VERSION "created by canmatrix"

NS_ :

BS_:

BU_: MD1_ECM ETC NODE_5 BSM_EBS RM_IRCS IC_Multic SGW BCM_NBM VCM NODE_31 ETS NODE_45 FCCU DICO NODE_72 FMReceiver SGW2 VCU ADCU MRGEN DTCO MBMS TPMS AI_CAID ELC ELC_R NODE_F7 BMS3 TUROLLA PCM SRR_Front_Left SRR_Rear_Right SRR_Front_Right SRR_Front SRR_Rear_Left ELFA3_S THERMOKING_M TMU_HP_Rr NODE_B1 NODE_B2 NODE_B3 NODE_B4 NODE_B5 NODE_B6 NODE_B7 NODE_B8 BMS2 NODE_B9 NODE_BA NODE_FC NODE_BB NODE_BC NODE_BE NODE_BD NODE_BF ACU NODE_C0 BMS1 NODE_C1 FCU NODE_C3 NODE_C4 NODE_EC NODE_C5 NODE_C6 NODE_C7 NODE_C8 VCU2 NODE_CA NODE_CB NODE_CD NODE_CE NODE_CF NODE_ED ST_ScanTool MASTER68_STD1 NODE_D1 NODE_F2 NODE_FD NODE_D2 MCSL NODE_EB NODE_D3 NODE_D4 NODE_D5 NODE_D6 VCCU NODE_D8 NODE_D9 NODE_F9 DiagTool NODE_DA NODE_DB NODE_DC NODE_DD NODE_DE NODE_DF NODE_E0 NODE_E1 NODE_E2 NODE_E9 NODE_E3 SAS NODE_FB NODE_F8 NODE_E6 ELFA3 NODE_F THERMOKING_D FMS MULTIC_S MULTIC_2 BMS4 BMS5 BMS6 BMS7 BMS8 BMS9 BMS10 BMS11 NODE_71

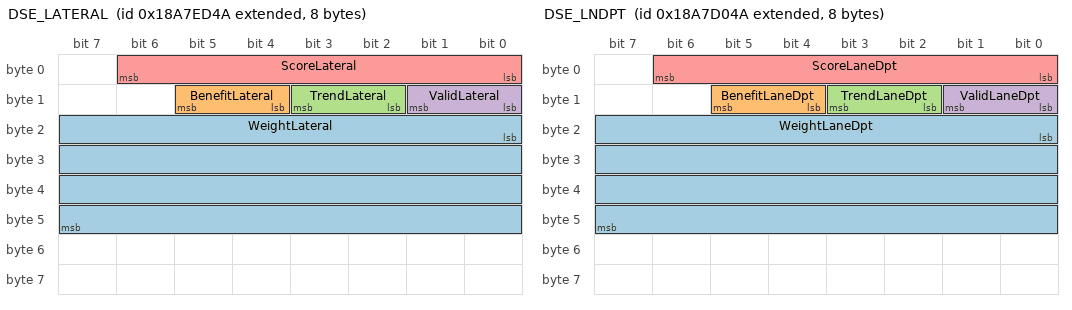
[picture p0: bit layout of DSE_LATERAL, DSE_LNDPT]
BO_ 2561142090 DSE_LATERAL: 8 PCM
 SG_ WeightLateral : 16|32@1+ (1,-1) [-1|4294967294] ""  NODE_ED
 SG_ BenefitLateral : 12|2@1+ (1,0) [0|3] ""  NODE_ED
 SG_ TrendLateral : 10|2@1+ (1,-1) [-1|2] ""  NODE_ED
 SG_ ValidLateral : 8|2@1+ (1,0) [0|3] ""  NODE_ED
 SG_ ScoreLateral : 0|7@1+ (1,0) [0|100] "%"  NODE_ED

BO_ 2561143114 DSE_LATERAL_DBG: 8 PCM
 SG_ EvaluatedMetersLateral : 16|16@1+ (1,-1) [-1|65534] "m"  ST_ScanTool
 SG_ NumEventsLateral : 0|16@1+ (1,-1) [-1|65534] "Count"  ST_ScanTool

BO_ 2561134666 DSE_LNDPT: 8 PCM
 SG_ WeightLaneDpt : 16|32@1+ (1,-1) [-1|4294967294] ""  MASTER68_STD1
 SG_ BenefitLaneDpt : 12|2@1+ (1,0) [0|3] ""  MASTER68_STD1
 SG_ TrendLaneDpt : 10|2@1+ (1,-1) [-1|2] ""  MASTER68_STD1
 SG_ ValidLaneDpt : 8|2@1+ (1,0) [0|3] ""  MASTER68_STD1
 SG_ ScoreLaneDpt : 0|7@1+ (1,-1) [-1|126] "Index"  MASTER68_STD1

BO_ 2561134922 DSE_LNDPT_DBG: 8 PCM
 SG_ EventLaneDpt : 16|2@1+ (1,0) [0|3] ""  NODE_D1
 SG_ EvaluatedSamplesLaneDpt : 0|16@1+ (1,-1) [-1|65534] ""  NODE_D1

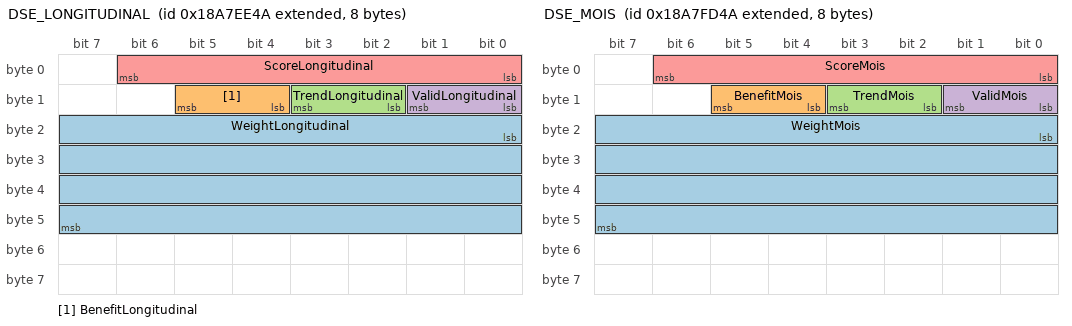
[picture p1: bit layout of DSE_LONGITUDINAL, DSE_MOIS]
BO_ 2561142346 DSE_LONGITUDINAL: 8 PCM
 SG_ WeightLongitudinal : 16|32@1+ (1,-1) [-1|4294967294] ""  DTCO
 SG_ BenefitLongitudinal : 12|2@1+ (1,0) [0|3] ""  DTCO
 SG_ TrendLongitudinal : 10|2@1+ (1,-1) [-1|2] ""  DTCO
 SG_ ValidLongitudinal : 8|2@1+ (1,0) [0|3] ""  DTCO
 SG_ ScoreLongitudinal : 0|7@1+ (1,0) [0|100] "%"  DTCO

BO_ 2561143370 DSE_LONGITUDINAL_DBG: 8 PCM
 SG_ EvalMetersLongitud : 16|16@1+ (1,-1) [-1|65534] "m"  NODE_F2
 SG_ NumEventsLongitudinal : 0|16@1+ (1,-1) [-1|65534] "Count"  NODE_F2

BO_ 2561146186 DSE_MOIS: 8 PCM
 SG_ WeightMois : 16|32@1+ (1,-1) [-1|4294967294] ""  NODE_FD
 SG_ BenefitMois : 12|2@1+ (1,0) [0|3] ""  NODE_FD
 SG_ TrendMois : 10|2@1+ (1,-1) [-1|2] ""  NODE_FD
 SG_ ValidMois : 8|2@1+ (1,0) [0|3] ""  NODE_FD
 SG_ ScoreMois : 0|7@1+ (1,-1) [-1|126] "Index"  NODE_FD

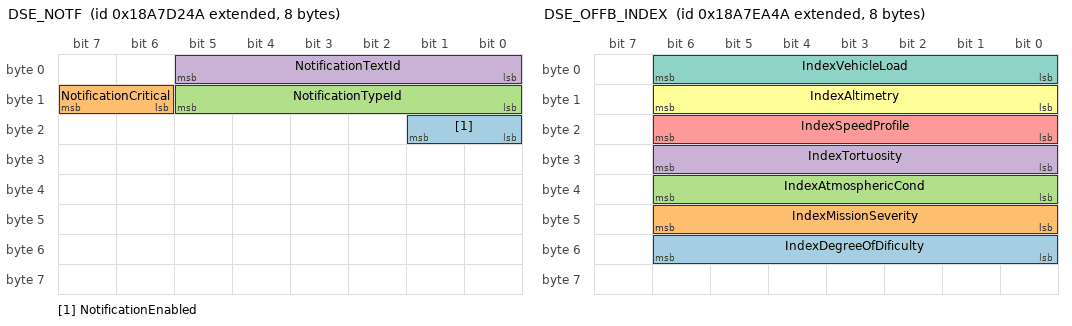
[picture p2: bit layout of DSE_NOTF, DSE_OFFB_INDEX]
BO_ 2561135178 DSE_NOTF: 8 PCM
 SG_ NotificationEnabled : 16|2@1+ (1,0) [0|3] ""  NODE_D2
 SG_ NotificationCritical : 14|2@1+ (1,0) [0|3] ""  NODE_D2
 SG_ NotificationTypeId : 8|6@1+ (1,0) [0|63] ""  NODE_D2
 SG_ NotificationTextId : 0|6@1+ (1,0) [0|63] ""  NODE_D2

BO_ 2561141322 DSE_OFFB_INDEX: 8 PCM
 SG_ IndexDegreeOfDificulty : 48|7@1+ (1,-1) [-1|126] "Index"  MCSL
 SG_ IndexMissionSeverity : 40|7@1+ (1,-1) [-1|126] "Index"  MCSL
 SG_ IndexAtmosphericCond : 32|7@1+ (1,-1) [-1|126] "Index"  MCSL
 SG_ IndexTortuosity : 24|7@1+ (1,-1) [-1|126] "Index"  MCSL
 SG_ IndexSpeedProfile : 16|7@1+ (1,-1) [-1|126] "Index"  MCSL
 SG_ IndexAltimetry : 8|7@1+ (1,-1) [-1|126] "Index"  MCSL
 SG_ IndexVehicleLoad : 0|7@1+ (1,-1) [-1|126] "Index"  MCSL

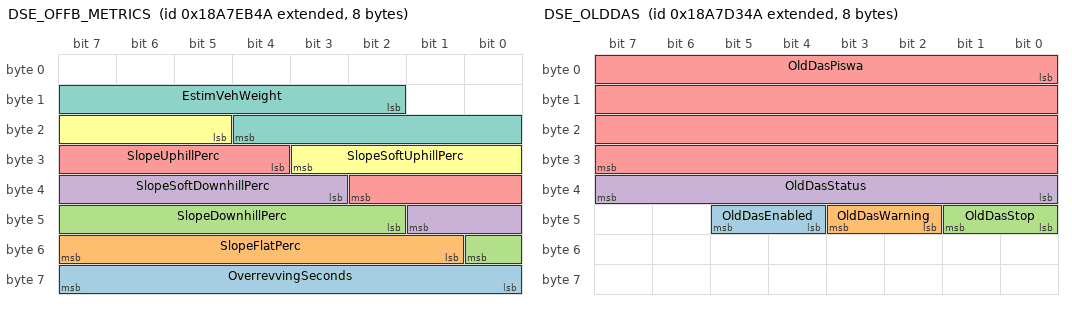
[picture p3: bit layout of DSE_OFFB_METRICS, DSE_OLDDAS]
BO_ 2561141578 DSE_OFFB_METRICS: 8 PCM
 SG_ OverrevvingSeconds : 56|8@1+ (1,-1) [-1|254] "s"  NODE_EB
 SG_ SlopeFlatPerc : 49|7@1+ (1,-1) [-1|126] "Index"  NODE_EB
 SG_ SlopeDownhillPerc : 42|7@1+ (1,-1) [-1|126] "Index"  NODE_EB
 SG_ SlopeSoftDownhillPerc : 35|7@1+ (1,-1) [-1|126] "Index"  NODE_EB
 SG_ SlopeUphillPerc : 28|7@1+ (1,-1) [-1|126] "Index"  NODE_EB
 SG_ SlopeSoftUphillPerc : 21|7@1+ (1,-1) [-1|126] "Index"  NODE_EB
 SG_ EstimVehWeight : 10|11@1+ (50,-1) [-1|102349] "kg"  NODE_EB

BO_ 2561135434 DSE_OLDDAS: 8 PCM
 SG_ OldDasEnabled : 44|2@1+ (1,0) [0|3] ""  NODE_D3
 SG_ OldDasWarning : 42|2@1+ (1,0) [0|3] ""  NODE_D3
 SG_ OldDasStop : 40|2@1+ (1,0) [0|3] ""  NODE_D3
 SG_ OldDasStatus : 32|8@1+ (1,0) [0|250] ""  NODE_D3
 SG_ OldDasPiswa : 0|32@1- (1,0) [0|4294967294] ""  NODE_D3

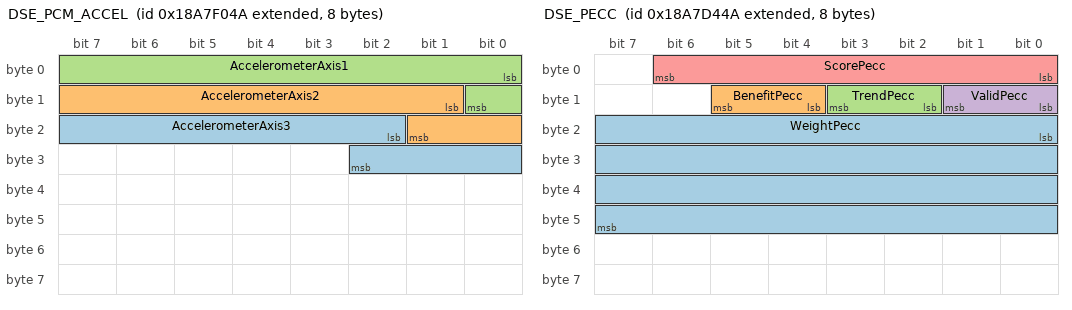
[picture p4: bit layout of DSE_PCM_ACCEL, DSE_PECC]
BO_ 2561142858 DSE_PCM_ACCEL: 8 PCM
 SG_ AccelerometerAxis3 : 18|9@1+ (0.1,-25.55) [-25.55|25.55] "m/s²"  ELFA3_S
 SG_ AccelerometerAxis2 : 9|9@1+ (0.1,-25.55) [-25.55|25.55] "m/s²"  ELFA3_S
 SG_ AccelerometerAxis1 : 0|9@1+ (0.1,-25.55) [-25.55|25.55] "m/s²"  ELFA3_S

BO_ 2561135690 DSE_PECC: 8 PCM
 SG_ WeightPecc : 16|32@1+ (1,-1) [-1|4294967294] ""  NODE_D4
 SG_ BenefitPecc : 12|2@1+ (1,0) [0|3] ""  NODE_D4
 SG_ TrendPecc : 10|2@1+ (1,-1) [-1|2] ""  NODE_D4
 SG_ ValidPecc : 8|2@1+ (1,0) [0|3] ""  NODE_D4
 SG_ ScorePecc : 0|7@1+ (1,-1) [-1|126] "Index"  NODE_D4

BO_ 2561135946 DSE_PECC_DBG: 8 PCM
 SG_ EventPecc : 16|2@1+ (1,0) [0|3] ""  NODE_D5
 SG_ EvalSamplesPecc : 0|16@1+ (1,-1) [-1|65534] ""  NODE_D5

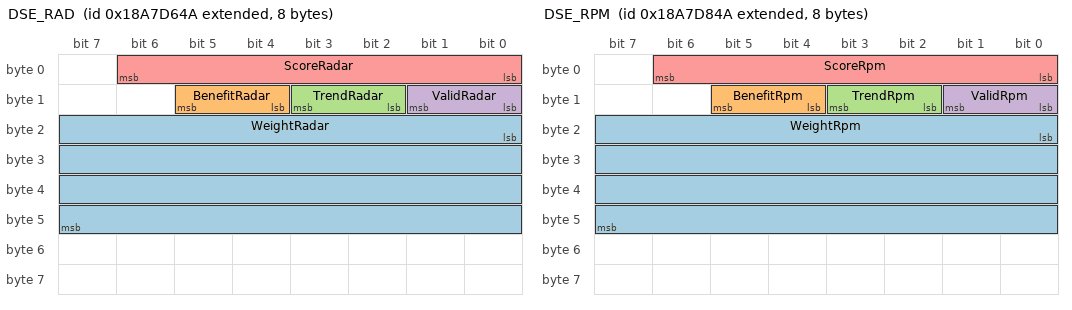
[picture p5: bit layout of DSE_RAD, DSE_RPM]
BO_ 2561136202 DSE_RAD: 8 PCM
 SG_ WeightRadar : 16|32@1+ (1,-1) [-1|4294967294] ""  NODE_D6
 SG_ BenefitRadar : 12|2@1+ (1,0) [0|3] ""  NODE_D6
 SG_ TrendRadar : 10|2@1+ (1,-1) [-1|2] ""  NODE_D6
 SG_ ValidRadar : 8|2@1+ (1,0) [0|3] ""  NODE_D6
 SG_ ScoreRadar : 0|7@1+ (1,-1) [-1|126] "Index"  NODE_D6

BO_ 2561136458 DSE_RAD_DBG: 8 PCM
 SG_ EventRadar : 16|2@1+ (1,0) [0|3] ""  VCCU
 SG_ EvalSamplesRadar : 0|16@1+ (1,-1) [-1|65534] ""  VCCU

BO_ 2561136714 DSE_RPM: 8 PCM
 SG_ WeightRpm : 16|32@1+ (1,-1) [-1|4294967294] ""  NODE_D8
 SG_ BenefitRpm : 12|2@1+ (1,0) [0|3] ""  NODE_D8
 SG_ TrendRpm : 10|2@1+ (1,-1) [-1|2] ""  NODE_D8
 SG_ ValidRpm : 8|2@1+ (1,0) [0|3] ""  NODE_D8
 SG_ ScoreRpm : 0|7@1+ (1,-1) [-1|126] "Index"  NODE_D8

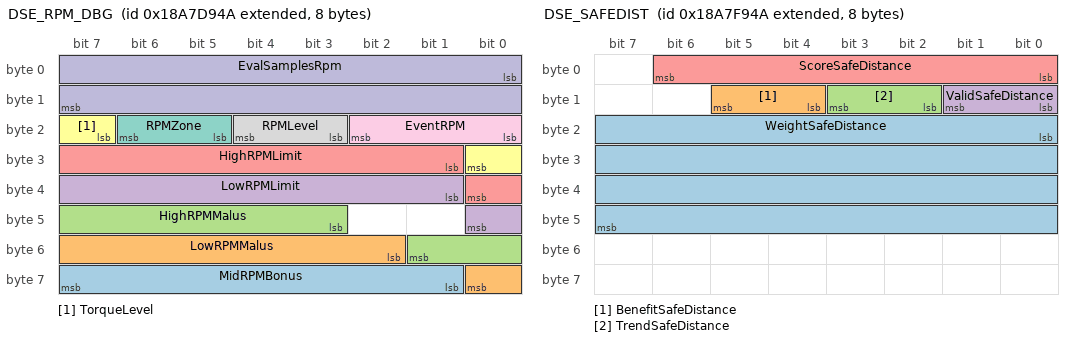
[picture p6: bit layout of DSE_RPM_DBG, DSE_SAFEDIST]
BO_ 2561136970 DSE_RPM_DBG: 8 PCM
 SG_ MidRPMBonus : 57|7@1+ (1,-1) [-1|126] "Index"  NODE_D9
 SG_ LowRPMMalus : 50|7@1+ (1,-126) [-126|1] "Index"  NODE_D9
 SG_ HighRPMMalus : 43|7@1+ (1,-126) [-126|1] "Index"  NODE_D9
 SG_ LowRPMLimit : 33|8@1+ (10,0) [0|2550] "rpm"  NODE_D9
 SG_ HighRPMLimit : 25|8@1+ (10,1000) [1000|3550] "rpm"  NODE_D9
 SG_ TorqueLevel : 23|2@1+ (1,0) [0|3] ""  NODE_D9
 SG_ RPMZone : 21|2@1+ (1,0) [0|3] ""  NODE_D9
 SG_ RPMLevel : 19|2@1+ (1,0) [0|3] ""  NODE_D9
 SG_ EventRPM : 16|3@1+ (1,0) [0|7] ""  NODE_D9
 SG_ EvalSamplesRpm : 0|16@1+ (1,-1) [-1|65534] ""  NODE_D9

BO_ 2561145162 DSE_SAFEDIST: 8 PCM
 SG_ WeightSafeDistance : 16|32@1+ (1,-1) [-1|4294967294] ""  NODE_F9
 SG_ BenefitSafeDistance : 12|2@1+ (1,0) [0|3] ""  NODE_F9
 SG_ TrendSafeDistance : 10|2@1+ (1,-1) [-1|2] ""  NODE_F9
 SG_ ValidSafeDistance : 8|2@1+ (1,0) [0|3] ""  NODE_F9
 SG_ ScoreSafeDistance : 0|7@1+ (1,-1) [-1|126] "Index"  NODE_F9

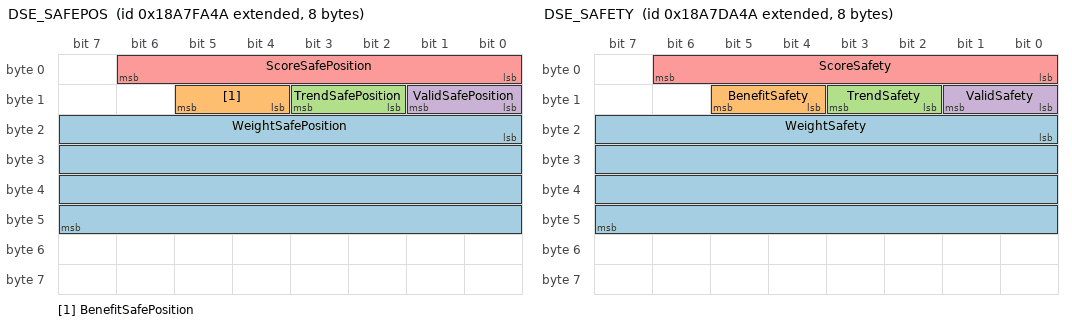
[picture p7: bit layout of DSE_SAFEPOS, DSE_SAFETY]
BO_ 2561145418 DSE_SAFEPOS: 8 PCM
 SG_ WeightSafePosition : 16|32@1+ (1,-1) [-1|4294967294] ""  DiagTool
 SG_ BenefitSafePosition : 12|2@1+ (1,0) [0|3] ""  DiagTool
 SG_ TrendSafePosition : 10|2@1+ (1,-1) [-1|2] ""  DiagTool
 SG_ ValidSafePosition : 8|2@1+ (1,0) [0|3] ""  DiagTool
 SG_ ScoreSafePosition : 0|7@1+ (1,-1) [-1|126] "Index"  DiagTool

BO_ 2561137226 DSE_SAFETY: 8 PCM
 SG_ WeightSafety : 16|32@1+ (1,-1) [-1|4294967294] ""  NODE_DA
 SG_ BenefitSafety : 12|2@1+ (1,0) [0|3] ""  NODE_DA
 SG_ TrendSafety : 10|2@1+ (1,-1) [-1|2] ""  NODE_DA
 SG_ ValidSafety : 8|2@1+ (1,0) [0|3] ""  NODE_DA
 SG_ ScoreSafety : 0|7@1+ (1,-1) [-1|126] "Index"  NODE_DA

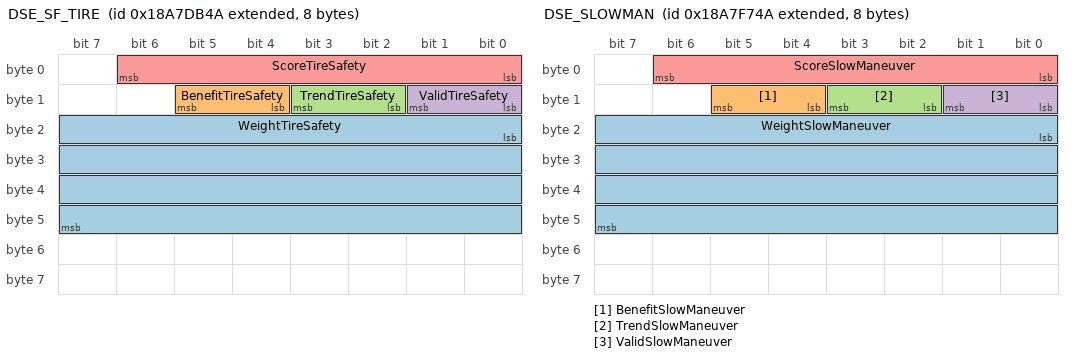
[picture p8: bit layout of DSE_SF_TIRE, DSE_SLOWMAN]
BO_ 2561137482 DSE_SF_TIRE: 8 PCM
 SG_ WeightTireSafety : 16|32@1+ (1,-1) [-1|4294967294] ""  NODE_DB
 SG_ BenefitTireSafety : 12|2@1+ (1,0) [0|3] ""  NODE_DB
 SG_ TrendTireSafety : 10|2@1+ (1,-1) [-1|2] ""  NODE_DB
 SG_ ValidTireSafety : 8|2@1+ (1,0) [0|3] ""  NODE_DB
 SG_ ScoreTireSafety : 0|7@1+ (1,-1) [-1|126] "Index"  NODE_DB

BO_ 2561137738 DSE_SF_TIRE_DBG: 8 PCM
 SG_ EventTireSafety : 16|2@1+ (1,0) [0|3] ""  NODE_DC
 SG_ EvalMetersTireSafety : 0|16@1+ (1,-1) [-1|65534] "m"  NODE_DC

BO_ 2561144650 DSE_SLOWMAN: 8 PCM
 SG_ WeightSlowManeuver : 16|32@1+ (1,-1) [-1|4294967294] ""  NODE_F7
 SG_ BenefitSlowManeuver : 12|2@1+ (1,0) [0|3] ""  NODE_F7
 SG_ TrendSlowManeuver : 10|2@1+ (1,-1) [-1|2] ""  NODE_F7
 SG_ ValidSlowManeuver : 8|2@1+ (1,0) [0|3] ""  NODE_F7
 SG_ ScoreSlowManeuver : 0|7@1+ (1,-1) [-1|126] "Index"  NODE_F7

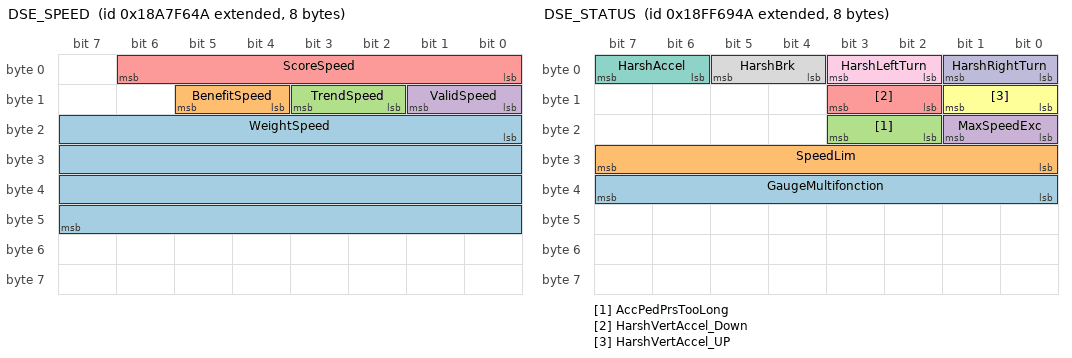
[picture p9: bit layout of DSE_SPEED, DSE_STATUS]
BO_ 2561144394 DSE_SPEED: 8 PCM
 SG_ WeightSpeed : 16|32@1+ (1,-1) [-1|4294967294] ""  BMS3
 SG_ BenefitSpeed : 12|2@1+ (1,0) [0|3] ""  BMS3
 SG_ TrendSpeed : 10|2@1+ (1,-1) [-1|2] ""  BMS3
 SG_ ValidSpeed : 8|2@1+ (1,0) [0|3] ""  BMS3
 SG_ ScoreSpeed : 0|7@1+ (1,-1) [-1|126] "Index"  BMS3

BO_ 2561137994 DSE_START: 8 PCM
 SG_ TimeStampTripStart : 32|32@1+ (1,946684800) [946684800|4294967294] "Count"  NODE_DD
 SG_ OdometerTripStart : 0|32@1+ (5,-1) [-1|21474836474] "m"  NODE_DD

BO_ 2566875466 DSE_STATUS: 8 PCM
 SG_ GaugeMultifonction : 32|8@1+ (0.4,0) [0|100] "%" Vector__XXX
 SG_ SpeedLim : 24|8@1+ (1,0) [0|250] "km/h" Vector__XXX
 SG_ AccPedPrsTooLong : 18|2@1+ (1,0) [0|3] "" Vector__XXX
 SG_ MaxSpeedExc : 16|2@1+ (1,0) [0|3] "" Vector__XXX
 SG_ HarshVertAccel_Down : 10|2@1+ (1,0) [0|3] "" Vector__XXX
 SG_ HarshVertAccel_UP : 8|2@1+ (1,0) [0|3] "" Vector__XXX
 SG_ HarshAccel : 6|2@1+ (1,0) [0|3] "" Vector__XXX
 SG_ HarshBrk : 4|2@1+ (1,0) [0|3] "" Vector__XXX
 SG_ HarshLeftTurn : 2|2@1+ (1,0) [0|3] "" Vector__XXX
 SG_ HarshRightTurn : 0|2@1+ (1,0) [0|3] "" Vector__XXX

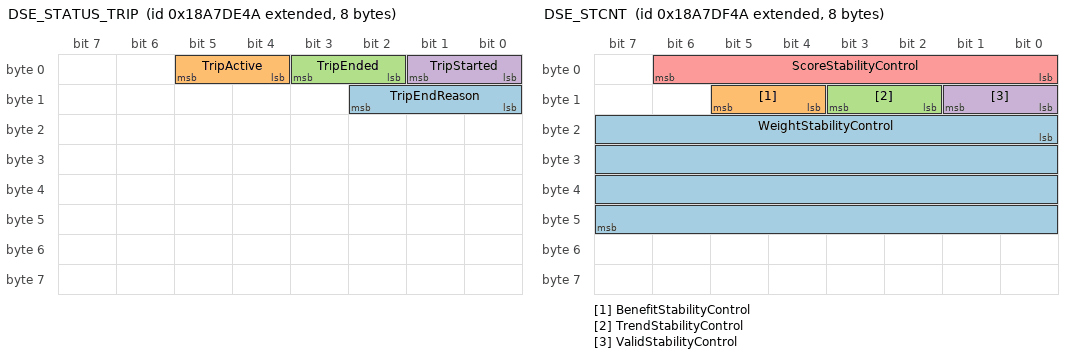
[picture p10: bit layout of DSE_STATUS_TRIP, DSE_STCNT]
BO_ 2561138250 DSE_STATUS_TRIP: 8 PCM
 SG_ TripEndReason : 8|3@1+ (1,0) [0|7] ""  NODE_DE
 SG_ TripActive : 4|2@1+ (1,0) [0|3] ""  NODE_DE
 SG_ TripEnded : 2|2@1+ (1,0) [0|3] ""  NODE_DE
 SG_ TripStarted : 0|2@1+ (1,0) [0|3] ""  NODE_DE

BO_ 2561138506 DSE_STCNT: 8 PCM
 SG_ WeightStabilityControl : 16|32@1+ (1,-1) [-1|4294967294] ""  NODE_DF
 SG_ BenefitStabilityControl : 12|2@1+ (1,0) [0|3] ""  NODE_DF
 SG_ TrendStabilityControl : 10|2@1+ (1,-1) [-1|2] ""  NODE_DF
 SG_ ValidStabilityControl : 8|2@1+ (1,0) [0|3] ""  NODE_DF
 SG_ ScoreStabilityControl : 0|7@1+ (1,-1) [-1|126] "Index"  NODE_DF

BO_ 2561138762 DSE_STCNT_DBG: 8 PCM
 SG_ EventStabilityControl : 16|2@1+ (1,0) [0|3] ""  NODE_E0
 SG_ EvalMetersStabilityCtrl : 0|16@1+ (1,-1) [-1|65534] ""  NODE_E0

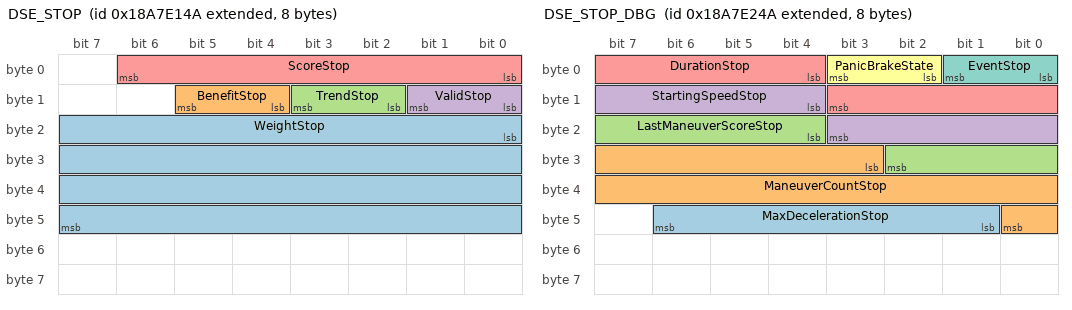
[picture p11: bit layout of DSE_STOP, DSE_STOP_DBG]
BO_ 2561139018 DSE_STOP: 8 PCM
 SG_ WeightStop : 16|32@1+ (1,-1) [-1|4294967294] ""  NODE_E1
 SG_ BenefitStop : 12|2@1+ (1,0) [0|3] ""  NODE_E1
 SG_ TrendStop : 10|2@1+ (1,-1) [-1|2] ""  NODE_E1
 SG_ ValidStop : 8|2@1+ (1,0) [0|3] ""  NODE_E1
 SG_ ScoreStop : 0|7@1+ (1,-1) [-1|126] "Index"  NODE_E1

BO_ 2561139274 DSE_STOP_DBG: 8 PCM
 SG_ MaxDecelerationStop : 41|6@1+ (1,0) [0|63] "kmh/s"  NODE_E2
 SG_ ManeuverCountStop : 27|14@1+ (1,-1) [-1|16382] "Count"  NODE_E2
 SG_ LastManeuverScoreStop : 20|7@1+ (1,-1) [-1|126] "Index"  NODE_E2
 SG_ StartingSpeedStop : 12|8@1+ (0.5,0) [0|127.5] "km/h"  NODE_E2
 SG_ DurationStop : 4|8@1+ (1,-1) [-1|254] "s"  NODE_E2
 SG_ PanicBrakeState : 2|2@1+ (1,0) [0|3] ""  NODE_E2
 SG_ EventStop : 0|2@1+ (1,0) [0|3] ""  NODE_E2

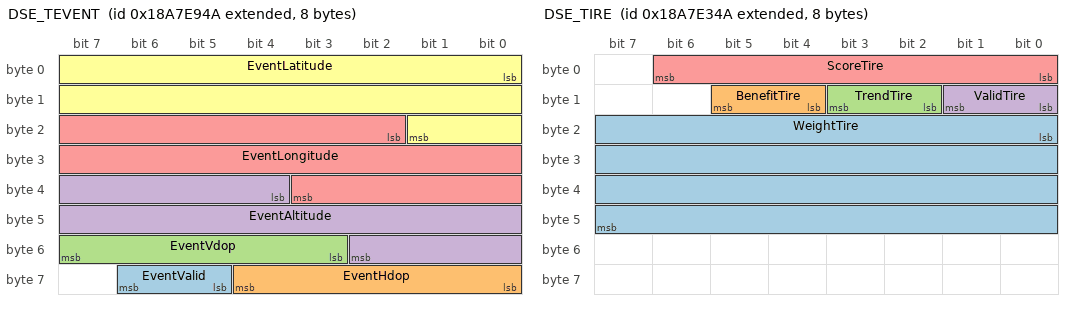
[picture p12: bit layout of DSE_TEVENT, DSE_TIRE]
BO_ 2561141066 DSE_TEVENT: 8 PCM
 SG_ EventValid : 61|2@1+ (1,0) [0|3] ""  NODE_E9
 SG_ EventHdop : 56|5@1+ (1,0) [0|25] ""  NODE_E9
 SG_ EventVdop : 51|5@1+ (1,0) [0|25] ""  NODE_E9
 SG_ EventAltitude : 36|15@1+ (0.2,-500) [-500|6053.4] ""  NODE_E9
 SG_ EventLongitude : 18|18@1+ (0.0015,-196.608) [-196.608|196.6065] ""  NODE_E9
 SG_ EventLatitude : 0|18@1+ (0.001,-131.072) [-131.072|131.071] ""  NODE_E9

BO_ 2561139530 DSE_TIRE: 8 PCM
 SG_ WeightTire : 16|32@1+ (1,-1) [-1|4294967294] ""  NODE_E3
 SG_ BenefitTire : 12|2@1+ (1,0) [0|3] ""  NODE_E3
 SG_ TrendTire : 10|2@1+ (1,-1) [-1|2] ""  NODE_E3
 SG_ ValidTire : 8|2@1+ (1,0) [0|3] ""  NODE_E3
 SG_ ScoreTire : 0|7@1+ (1,-1) [-1|126] "Index"  NODE_E3

BO_ 2561139786 DSE_TIRE_DBG: 8 PCM
 SG_ EventTireSaving : 16|2@1+ (1,0) [0|3] ""  SAS
 SG_ EvaluatedSamplesTire : 0|16@1+ (1,-1) [-1|65534] ""  SAS

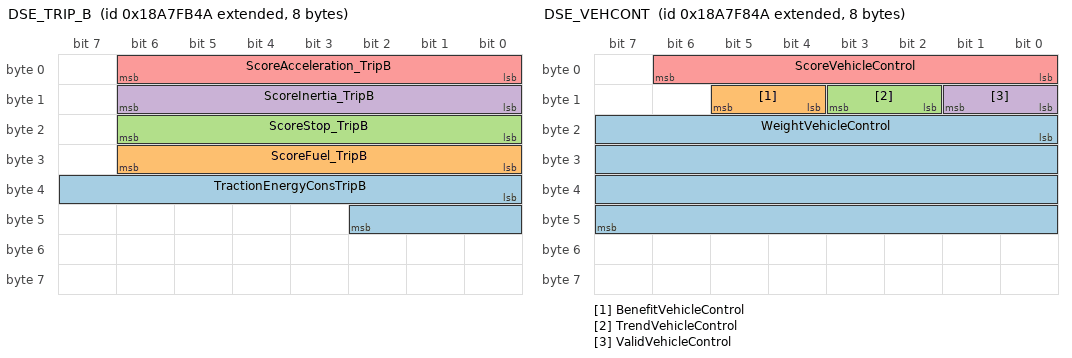
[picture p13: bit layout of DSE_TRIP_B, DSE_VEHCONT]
BO_ 2561145674 DSE_TRIP_B: 8 PCM
 SG_ TractionEnergyConsTripB : 32|11@1+ (0.1,-1) [-1|203.7] "kWh/100km"  NODE_FB
 SG_ ScoreFuel_TripB : 24|7@1+ (1,-1) [-1|100] "Index"  NODE_FB
 SG_ ScoreStop_TripB : 16|7@1+ (1,-1) [-1|100] "Index"  NODE_FB
 SG_ ScoreInertia_TripB : 8|7@1+ (1,-1) [-1|100] "Index"  NODE_FB
 SG_ ScoreAcceleration_TripB : 0|7@1+ (1,-1) [-1|100] "Index"  NODE_FB

BO_ 2561144906 DSE_VEHCONT: 8 PCM
 SG_ WeightVehicleControl : 16|32@1+ (1,-1) [-1|4294967294] ""  NODE_F8
 SG_ BenefitVehicleControl : 12|2@1+ (1,0) [0|3] ""  NODE_F8
 SG_ TrendVehicleControl : 10|2@1+ (1,-1) [-1|2] ""  NODE_F8
 SG_ ValidVehicleControl : 8|2@1+ (1,0) [0|3] ""  NODE_F8
 SG_ ScoreVehicleControl : 0|7@1+ (1,-1) [-1|126] "Index"  NODE_F8

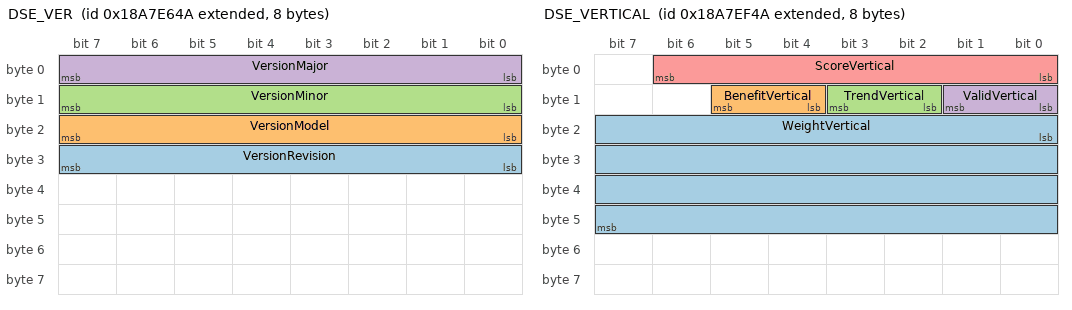
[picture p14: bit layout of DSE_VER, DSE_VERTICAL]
BO_ 2561140298 DSE_VER: 8 PCM
 SG_ VersionRevision : 24|8@1+ (1,-1) [-1|249] ""  NODE_E6
 SG_ VersionModel : 16|8@1+ (1,-1) [-1|249] ""  NODE_E6
 SG_ VersionMinor : 8|8@1+ (1,-1) [-1|249] ""  NODE_E6
 SG_ VersionMajor : 0|8@1+ (1,-1) [-1|249] ""  NODE_E6

BO_ 2561142602 DSE_VERTICAL: 8 PCM
 SG_ WeightVertical : 16|32@1+ (1,-1) [-1|4294967294] ""  ELFA3
 SG_ BenefitVertical : 12|2@1+ (1,0) [0|3] ""  ELFA3
 SG_ TrendVertical : 10|2@1+ (1,-1) [-1|2] ""  ELFA3
 SG_ ValidVertical : 8|2@1+ (1,0) [0|3] ""  ELFA3
 SG_ ScoreVertical : 0|7@1+ (1,0) [0|100] "%"  ELFA3

BO_ 2561143626 DSE_VERTICAL_DBG: 8 PCM
 SG_ EvalMetersVertical : 16|16@1+ (1,-1) [-1|65534] "m"  MBMS
 SG_ NumEventsVertical : 0|16@1+ (1,-1) [-1|65534] "Count"  MBMS

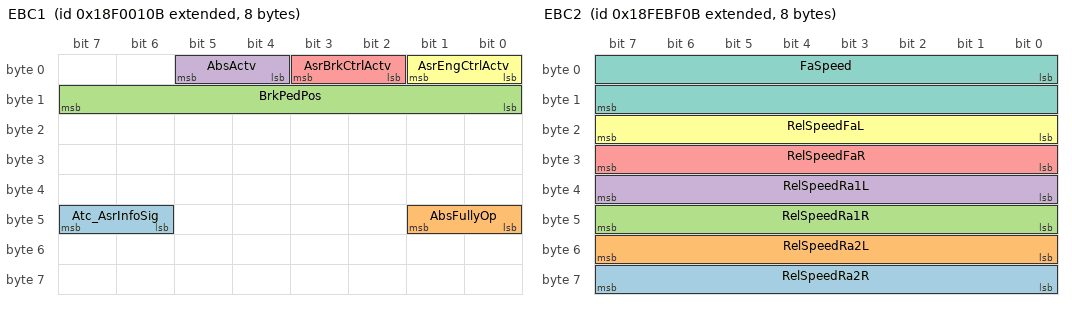
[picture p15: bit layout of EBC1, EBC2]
BO_ 2565865739 EBC1: 8 BSM_EBS
 SG_ Atc_AsrInfoSig : 46|2@1+ (1,0) [0|3] ""  PCM
 SG_ AbsFullyOp : 40|2@1+ (1,0) [0|3] ""  PCM
 SG_ BrkPedPos : 8|8@1+ (0.4,0) [0|100] "%"  PCM
 SG_ AbsActv : 4|2@1+ (1,0) [0|3] ""  PCM
 SG_ AsrBrkCtrlActv : 2|2@1+ (1,0) [0|3] ""  PCM
 SG_ AsrEngCtrlActv : 0|2@1+ (1,0) [0|3] ""  PCM

BO_ 2566831883 EBC2: 8 BSM_EBS
 SG_ RelSpeedRa2R : 56|8@1+ (0.0625,-7.8125) [-7.8125|7.8125] "km/h"  PCM
 SG_ RelSpeedRa2L : 48|8@1+ (0.0625,-7.8125) [-7.8125|7.8125] "km/h"  PCM
 SG_ RelSpeedRa1R : 40|8@1+ (0.0625,-7.8125) [-7.8125|7.8125] "km/h"  PCM
 SG_ RelSpeedRa1L : 32|8@1+ (0.0625,-7.8125) [-7.8125|7.8125] "km/h"  PCM
 SG_ RelSpeedFaR : 24|8@1+ (0.0625,-7.8125) [-7.8125|7.8125] "km/h"  PCM
 SG_ RelSpeedFaL : 16|8@1+ (0.0625,-7.8125) [-7.8125|7.8125] "km/h"  PCM
 SG_ FaSpeed : 0|16@1+ (0.00390625,0) [0|250.996] "km/h"  PCM

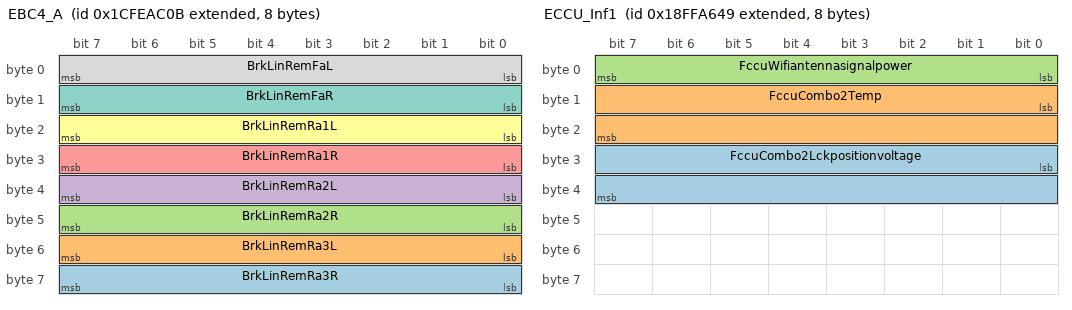
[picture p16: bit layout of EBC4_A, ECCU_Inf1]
BO_ 2633935883 EBC4_A: 8 BSM_EBS
 SG_ BrkLinRemRa3R : 56|8@1+ (0.4,0) [0|100] "%"  PCM
 SG_ BrkLinRemRa3L : 48|8@1+ (0.4,0) [0|100] "%"  PCM
 SG_ BrkLinRemRa2R : 40|8@1+ (0.4,0) [0|100] "%"  PCM
 SG_ BrkLinRemRa2L : 32|8@1+ (0.4,0) [0|100] "%"  PCM
 SG_ BrkLinRemRa1R : 24|8@1+ (0.4,0) [0|100] "%"  PCM
 SG_ BrkLinRemRa1L : 16|8@1+ (0.4,0) [0|100] "%"  PCM
 SG_ BrkLinRemFaR : 8|8@1+ (0.4,0) [0|100] "%"  PCM
 SG_ BrkLinRemFaL : 0|8@1+ (0.4,0) [0|100] "%"  PCM

BO_ 2566767627 EBC5: 8 BSM_EBS
 SG_ HhMode : 5|3@1+ (1,0) [0|7] ""  PCM
 SG_ HaltBrkMode : 2|3@1+ (1,0) [0|7] ""  PCM

BO_ 2566841088 EC1_00_E3: 40 MD1_ECM
 SG_ EngMaxMomOvrSpeedPnt7 : 168|16@1+ (0.125,0) [0|8031.875] "rpm"  PCM
 SG_ EngRefTrq : 152|16@1+ (1,0) [0|64255] "Nm"  PCM
 SG_ EngSpeedAtHighIdlePnt6 : 120|16@1+ (0.125,0) [0|8031.875] "rpm"  PCM
 SG_ EngSpeedAtIdlePnt1 : 0|16@1+ (0.125,0) [0|8031.875] "rpm"  PCM

BO_ 2566841216 EC1_80: 28 VCU
 SG_ EngRefTrq_FEE380 : 152|16@1+ (1,0) [0|64255] "Nm"  PCM

BO_ 2566891081 ECCU_Inf1: 8 FCCU
 SG_ FccuCombo2Lckpositionvoltage : 24|16@1+ (1,0) [0|65535] "mV"  PCM
 SG_ FccuCombo2Temp : 8|16@1+ (1,-150) [-150|65383] "°C"  PCM
 SG_ FccuWifiantennasignalpower : 0|8@1+ (1,-100) [-100|100] "dBm"  PCM

BO_ 2566889801 ECCU2SCU_49: 8 FCCU
 SG_ EvsePresCur : 40|16@1+ (0.1,0) [0|1000] "A"  PCM
 SG_ ChgIntrp : 8|2@1+ (1,0) [0|3] ""  PCM

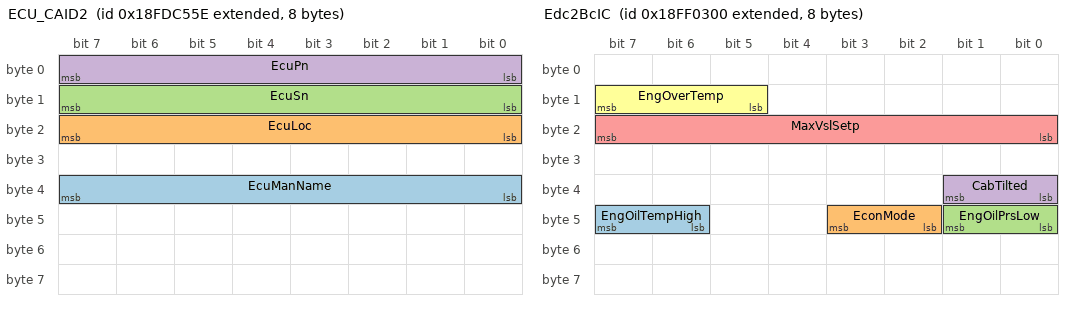
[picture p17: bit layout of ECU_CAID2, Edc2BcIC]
BO_ 2566767966 ECU_CAID2: 8 AI_CAID
 SG_ EcuManName : 32|8@1+ (1,0) [0|255] "ASCII"  PCM
 SG_ EcuLoc : 16|8@1+ (1,0) [0|255] "ASCII"  PCM
 SG_ EcuSn : 8|8@1+ (1,0) [0|255] "ASCII"  PCM
 SG_ EcuPn : 0|8@1+ (1,0) [0|255] "ASCII"  PCM

BO_ 2566767901 ECUID_1D: 1005 SGW
 SG_ EcuManName_FDC51D : 32|8@1+ (1,0) [0|255] "ASCII"  PCM
 SG_ EcuType : 24|8@1+ (1,0) [0|255] "ASCII"  PCM
 SG_ EcuLoc_FDC51D : 16|8@1+ (1,0) [0|255] "ASCII"  PCM
 SG_ EcuSn_FDC51D : 8|8@1+ (1,0) [0|255] "ASCII"  PCM
 SG_ EcuPn_FDC51D : 0|8@1+ (1,0) [0|255] "ASCII"  PCM

BO_ 2566849280 Edc2BcIC: 8 MD1_ECM
 SG_ EngOilTempHigh : 46|2@1+ (1,0) [0|3] ""  PCM
 SG_ EconMode : 42|2@1+ (1,0) [0|3] ""  PCM
 SG_ EngOilPrsLow : 40|2@1+ (1,0) [0|3] ""  PCM
 SG_ CabTilted : 32|2@1+ (1,0) [0|3] ""  PCM
 SG_ MaxVslSetp : 16|8@1+ (1,0) [0|250] "km/h"  PCM
 SG_ EngOverTemp : 13|3@1+ (1,0) [0|7] ""  PCM

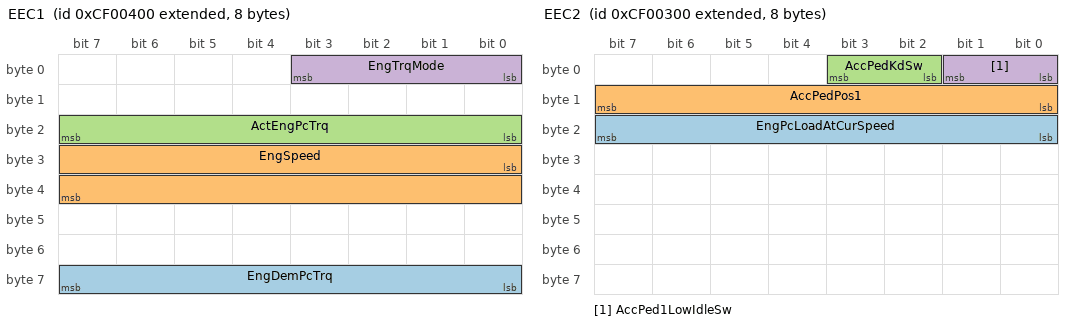
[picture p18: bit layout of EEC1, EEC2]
BO_ 2364539904 EEC1: 8 MD1_ECM
 SG_ EngDemPcTrq : 56|8@1+ (1,-125) [-125|125] "%"  PCM
 SG_ EngSpeed : 24|16@1+ (0.125,0) [0|8031.875] "rpm"  PCM
 SG_ ActEngPcTrq : 16|8@1+ (1,-125) [-125|125] "%"  PCM
 SG_ EngTrqMode : 0|4@1+ (1,0) [0|15] ""  PCM

BO_ 2364540032 EEC1_80: 8 VCU
 SG_ EngSpeed_00480 : 24|16@1+ (0.125,0) [0|8031.875] "rpm"  PCM
 SG_ ActEngPcTrq_00480 : 16|8@1+ (1,-125) [-125|125] "%"  PCM

BO_ 2566767127 EEC14_17: 8 IC_Multic
 SG_ FuelType : 48|8@1+ (1,0) [0|255] ""  PCM

BO_ 2364539648 EEC2: 8 MD1_ECM
 SG_ EngPcLoadAtCurSpeed : 16|8@1+ (1,0) [0|250] "%"  PCM
 SG_ AccPedPos1 : 8|8@1+ (0.4,0) [0|100] "%"  PCM
 SG_ AccPedKdSw : 2|2@1+ (1,0) [0|3] ""  PCM
 SG_ AccPed1LowIdleSw : 0|2@1+ (1,0) [0|3] ""  PCM

BO_ 2364539776 EEC2_80: 8 VCU
 SG_ ActMaxAvEngPcTrq : 48|8@1+ (0.4,0) [0|100] "%"  PCM
 SG_ EngPcLoadAtCurSpeed_00380 : 16|8@1+ (1,0) [0|250] "%"  PCM
 SG_ AccPedPos1_00380 : 8|8@1+ (0.4,0) [0|100] "%"  PCM

BO_ 2566840064 EEC3: 8 MD1_ECM
 SG_ NomFrictPcTrq : 0|8@1+ (1,-125) [-125|125] "%"  PCM

BO_ 2566840192 EEC3_80: 8 VCU
 SG_ NomFrictPcTrq_FEDF80 : 0|8@1+ (1,-125) [-125|125] "%"  PCM

BO_ 2566844160 EFLP1: 8 MD1_ECM
 SG_ EngOilPrs1 : 24|8@1+ (4,0) [0|1000] "kPa"  PCM
 SG_ EngFuelDelPrs : 0|8@1+ (4,0) [0|1000] "kPa"  PCM

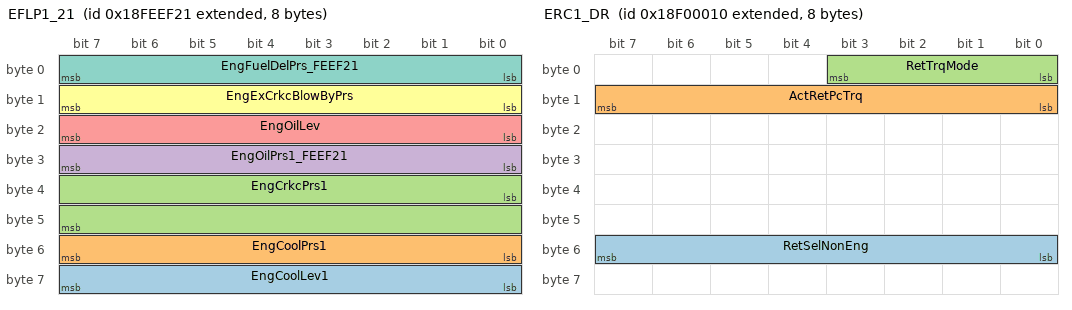
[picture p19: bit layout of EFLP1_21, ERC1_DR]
BO_ 2566844193 EFLP1_21: 8 BCM_NBM
 SG_ EngCoolLev1 : 56|8@1+ (0.4,0) [0|100] "%"  PCM
 SG_ EngCoolPrs1 : 48|8@1+ (2,0) [0|500] "kPa"  PCM
 SG_ EngCrkcPrs1 : 32|16@1+ (0.0078125,-250) [-250|251.99] "kPa"  PCM
 SG_ EngOilPrs1_FEEF21 : 24|8@1+ (4,0) [0|1000] "kPa"  PCM
 SG_ EngOilLev : 16|8@1+ (0.4,0) [0|100] "%"  PCM
 SG_ EngExCrkcBlowByPrs : 8|8@1+ (0.05,0) [0|12.5] "kPa"  PCM
 SG_ EngFuelDelPrs_FEEF21 : 0|8@1+ (4,0) [0|1000] "kPa"  PCM

BO_ 2566885210 ELFASys1_ELFA2: 8 DICO
 SG_ Modefb : 4|4@1+ (1,0) [0|3] ""  PCM

BO_ 2566898290 EmCmd: 8 NODE_72
 SG_ EngStopSw : 18|2@1+ (1,0) [0|3] ""  PCM

BO_ 2565865488 ERC1_DR: 8 RM_IRCS
 SG_ RetSelNonEng : 48|8@1+ (0.4,0) [0|100] "%"  PCM
 SG_ ActRetPcTrq : 8|8@1+ (1,-125) [-125|125] "%"  PCM
 SG_ RetTrqMode : 0|4@1+ (1,0) [0|15] ""  PCM

BO_ 2565865487 ERC1_ER: 8 NODE_F
 SG_ ActRetPcTrq_F0000F : 8|8@1+ (1,-125) [-125|125] "%"  PCM

BO_ 2566843904 ET1: 8 MD1_ECM
 SG_ EngOilTemp1 : 16|16@1+ (0.03125,-273) [-273|1734.96875] "°C"  PCM
 SG_ EngFuel1Temp1 : 8|8@1+ (1,-40) [-40|210] "°C"  PCM
 SG_ EngCoolTemp : 0|8@1+ (1,-40) [-40|210] "°C"  PCM

CM_ BO_ 2561142090 "- DSE Functionnality. Message sent for debugging on the CAN Telem";
CM_ BO_ 2561143114 "- DSE Functionnality. Message sent for debugging on the CAN Telem";
CM_ BO_ 2561134666 "- DSE Functionnality. Message sent for debugging on the CAN Telem";
CM_ BO_ 2561134922 "- DSE Functionnality. Message sent for debugging on the CAN Telem";
CM_ BO_ 2561142346 "- DSE Functionnality. Message sent for debugging on the CAN Telem";
CM_ BO_ 2561143370 "- DSE Functionnality. Message sent for debugging on the CAN Telem";
CM_ BO_ 2561146186 "- DSE Functionnality. Message sent for debugging on the CAN Telem";
CM_ BO_ 2561135178 "- DSE Functionnality. Message sent for debugging on the CAN Telem";
CM_ BO_ 2561141322 "- DSE Functionnality. Message sent for debugging on the CAN Telem";
CM_ BO_ 2561141578 "- DSE Functionnality. Message sent for debugging on the CAN Telem";
CM_ BO_ 2561135434 "- DSE Functionnality. Message sent for debugging on the CAN Telem";
CM_ SG_ 2561135434 OldDasEnabled "- Value Type: Signed --> Unsigned";
CM_ SG_ 2561135434 OldDasPiswa "- Value Type: IEEE Float --> Signed. To be tested if ok or needed Unsigned.";
CM_ BO_ 2561142858 "- DSE Functionnality. Message sent for debugging on the CAN Telem";
CM_ SG_ 2561142858 AccelerometerAxis3 "- Offset changed: 0--> -25.55. To be tested";
CM_ SG_ 2561142858 AccelerometerAxis2 "- Offset changed: 0--> -25.55. To be tested";
CM_ SG_ 2561142858 AccelerometerAxis1 "- Offset changed: 0--> -25.55. To be tested";
CM_ BO_ 2561135690 "- DSE Functionnality. Message sent for debugging on the CAN Telem";
CM_ BO_ 2561135946 "- DSE Functionnality. Message sent for debugging on the CAN Telem";
CM_ BO_ 2561136202 "- DSE Functionnality. Message sent for debugging on the CAN Telem";
CM_ BO_ 2561136458 "- DSE Functionnality. Message sent for debugging on the CAN Telem";
CM_ BO_ 2561136714 "- DSE Functionnality. Message sent for debugging on the CAN Telem";
CM_ BO_ 2561136970 "- DSE Functionnality. Message sent for debugging on the CAN Telem";
CM_ BO_ 2561145162 "- DSE Functionnality. Message sent for debugging on the CAN Telem";
CM_ BO_ 2561145418 "- DSE Functionnality. Message sent for debugging on the CAN Telem";
CM_ BO_ 2561137226 "- DSE Functionnality. Message sent for debugging on the CAN Telem";
CM_ BO_ 2561137482 "- DSE Functionnality. Message sent for debugging on the CAN Telem";
CM_ BO_ 2561137738 "- DSE Functionnality. Message sent for debugging on the CAN Telem";
CM_ BO_ 2561144650 "- DSE Functionnality. Message sent for debugging on the CAN Telem";
CM_ BO_ 2561144394 "- DSE Functionnality. Message sent for debugging on the CAN Telem";
CM_ BO_ 2561137994 "- DSE Functionnality. Message sent for debugging on the CAN Telem";
CM_ BO_ 2566875466 "- Blue pictograms displayed at the top right corner above the vehicle speed on the cluster";
CM_ BO_ 2561138250 "- DSE Functionnality";
CM_ BO_ 2561138506 "- DSE Functionnality. Message sent for debugging on the CAN Telem";
CM_ BO_ 2561138762 "- DSE Functionnality. Message sent for debugging on the CAN Telem";
CM_ BO_ 2561139018 "- DSE Functionnality. Message sent for debugging on the CAN Telem";
CM_ BO_ 2561139274 "- DSE Functionnality. Message sent for debugging on the CAN Telem";
CM_ BO_ 2561141066 "- DSE Functionnality. Message sent for debugging on the CAN Telem";
CM_ BO_ 2561139530 "- DSE Functionnality. Message sent for debugging on the CAN Telem";
CM_ BO_ 2561139786 "- DSE Functionnality. Message sent for debugging on the CAN Telem";
CM_ BO_ 2561145674 "- DSE Functionnality";
CM_ BO_ 2561144906 "- DSE Functionnality. Message sent for debugging on the CAN Telem";
CM_ BO_ 2561140298 "- DSE Functionnality. Message sent for debugging on the CAN Telem";
CM_ BO_ 2561142602 "- DSE Functionnality. Message sent for debugging on the CAN Telem";
CM_ BO_ 2561143626 "- DSE Functionnality. Message sent for debugging on the CAN Telem";
CM_ BO_ 2565865739 "- DR.ZF.RM.INT.3..VDB: only message timeout is monitored";
CM_ BO_ 2566831883 "- Full elec: Timeout (ms): 250 ms
- BC.A.BCM..24..VDB: Only for ESS without AEBS.";
CM_ SG_ 2566831883 RelSpeedRa2R "- 18m vehicle only";
CM_ SG_ 2566831883 RelSpeedRa2L "- 18m vehicle only";
CM_ BO_ 2633935883 "- Only valid if no faster OnRequest requests are sollicitated";
CM_ SG_ 2633935883 BrkLinRemRa3R "- Not applicable bus/coach";
CM_ SG_ 2633935883 BrkLinRemRa3L "- Not applicable bus/coach";
CM_ SG_ 2633935883 BrkLinRemRa2R "- 18m vehicle";
CM_ SG_ 2633935883 BrkLinRemRa2L "- 18m vehicle";
CM_ BO_ 2566767627 "- Not used for Bus ACC, as no XBR_ACC.
- BC.A.BCM..24..VDB: Only for ESS without AEBS
- CUC.C.PCM..3..TELEM: Predisposal
- MC.A.VCU..24..VDB: Only Gx (ELFA2).
- MC.B.VMU..25..Traction: Used (again) in according with VMU_CAN_Interface 4 file.
- MC.W.VCM....VDB: Used by VCM for adaptive cruise control.";
CM_ SG_ 2566767627 HhMode "- MC.A.VCU..24..VDB: Only Gx (ELFA2)";
CM_ SG_ 2566767627 HaltBrkMode "- EBC.KB.BSM..23..VDB: R.S: This signal is used by function Bus Stop Brake (Door Brake).
- MC.A.VCU..24..VDB: Only Gx (ELFA2)";
CM_ BO_ 2566841088 "- Message Length: 34/40 bytes, depending on the application.
-  Multipacket message handled by SAE Transport Protocol (J1939/21, par 5.10, Multipacket Broadcast with TP.CM/BAM, TP.DT).";
CM_ BO_ 2566841216 "- Specific to Siemens Full Elec vehicles.";
CM_ BO_ 2566891081 "- Specific to Siemens Full Elec vehicles. Only for case FCCU.";
CM_ BO_ 2566889801 "- Message sent by the ECCU at period 5000ms in the case ECCU.";
CM_ SG_ 2566889801 EvsePresCur "- The ground station current at the charger so the VCU can determine whether it is safe to charge, Not required for integration build";
CM_ SG_ 2566889801 ChgIntrp "- The charger sends a message to the VCU informing of an interruption of charging (stop button on charger), This is not currently included as default";
CM_ BO_ 2566767966 "- Multipacket message handled by SAE Transport Protocol (J1939/21, par 5.10, Multipacket Broadcast with TP.CM/BAM, TP.DT)
-  Transport Protocol with Control Flow  (RTS, CTS, EndOfMsgAck, Conn_Abort) shall be also supported by the receiver if the multipacket message has been solicited by a Destination Specific Request
-  Variable Message Length, maximum value used for dbc generation";
CM_ SG_ 2566767966 EcuManName "- 15+1 characters maximum, (CNHI Std. 18-2253)
-  Variable signal length, 8 bits used for dbc generation only";
CM_ SG_ 2566767966 EcuLoc "- 10+1 characters maximum. concatenation of Subnetwork Identifiers Hex number in ASCII (CNHI Std. 18-2254)
-  Variable signal length, 8 bits used for dbc generation only";
CM_ SG_ 2566767966 EcuSn "- 10+1 characters maximum. Manufacturer assigned (CNHI Std. 18-2253)
-  Variable signal length, 8 bits used for dbc generation only";
CM_ SG_ 2566767966 EcuPn "- 15+1 characters maximum. Iveco assigned ECU Hw+Sw P/N (CNHI Std. 18-2253)
-  Variable signal length, 8 bits used for dbc generation only";
CM_ BO_ 2566767901 "- Multipacket message handled by SAE Transport Protocol (J1939/21, par 5.10, Multipacket Broadcast with TP.CM/BAM, TP.DT)
-  Transport Protocol with Control Flow  (RTS, CTS, EndOfMsgAck, Conn_Abort) shall be also supported by the receiver if the multipacket message has been solicited by a Destination Specific Request
-  Variable Message Length, maximum value used for dbc generation";
CM_ SG_ 2566767901 EcuManName_FDC51D "- 15+1 characters maximum, (CNHI Std. 18-2253)
-  Variable signal length, 8 bits used for dbc generation only";
CM_ SG_ 2566767901 EcuType "- 1 character, Empty field, delimiter only (CNHI Std. 18-2253)";
CM_ SG_ 2566767901 EcuLoc_FDC51D "- 10+1 characters maximum. concatenation of Subnetwork Identifiers Hex number in ASCII (CNHI Std. 18-2254)
-  Variable signal length, 8 bits used for dbc generation only";
CM_ SG_ 2566767901 EcuSn_FDC51D "- 10+1 characters maximum. Manufacturer assigned (CNHI Std. 18-2253)
-  Variable signal length, 8 bits used for dbc generation only";
CM_ SG_ 2566767901 EcuPn_FDC51D "- 15+1 characters maximum. Iveco assigned ECU Hw+Sw P/N (CNHI Std. 18-2253)
-  Variable signal length, 8 bits used for dbc generation only";
CM_ BO_ 2566849280 "- VCM4 read EDC2BC on Engine CAN with Id 18 FF 21 00 and emit a copy with Id 18 FF 03 00.";
CM_ BO_ 2364539904 "- Broadcasted with modifications
-  CAN VDB, Telem, Tacho, FMS, Infot: Only ICE. CAN NRJ: available.
- VS2.B.SGW2..23..Ethylo: Added for backwards compatibility with CAID";
CM_ SG_ 2364539904 EngSpeed "- SAE J1939/73 Freeze Frame parameter";
CM_ SG_ 2364539904 ActEngPcTrq "- FEh in case of error";
CM_ SG_ 2364539904 EngTrqMode "- SAE J1939/73 Freeze Frame parameter";
CM_ BO_ 2364540032 "- Timeout (ms): 50 ms / -
- MC.A.VCU..24..VDB: Only Gx (ELFA2).
- PCM.Si.DICO....Traction: 10ms in messagerie ELFA2";
CM_ BO_ 2364539648 "- ICE bus only";
CM_ SG_ 2364539648 EngPcLoadAtCurSpeed "- SAE J1939/73 Freeze Frame parameter";
CM_ BO_ 2364539776 "- Full elec Siemens only";
CM_ SG_ 2364539776 EngPcLoadAtCurSpeed_00380 "- MC.A.VCU..24..VDB: Sent as Not available.
- MC.B.VMU..25..VDB: Sent as Not available.";
CM_ SG_ 2364539776 AccPedPos1_00380 "- UW: recopy of information in EEC2 (0C F0 03 00)";
CM_ BO_ 2566840064 "- Diesel / Gas only";
CM_ BO_ 2566840192 "- Siemens Full elec only. 250 ms in messagerie ELFA3 . 200ms in messagerie ELFA2.";
CM_ SG_ 2566844160 EngOilPrs1 "- FEh in case of defective sensor";
CM_ SG_ 2566844160 EngFuelDelPrs "- GAZ only. To be added into VCM4 VDB";
CM_ SG_ 2566844193 EngCoolLev1 "- Set to FF";
CM_ SG_ 2566844193 EngCoolPrs1 "- Set to FF";
CM_ SG_ 2566844193 EngCrkcPrs1 "- Set to FFFF";
CM_ SG_ 2566844193 EngOilPrs1_FEEF21 "- FEh in case of defective sensor";
CM_ SG_ 2566844193 EngExCrkcBlowByPrs "- Set to FF";
CM_ SG_ 2566844193 EngFuelDelPrs_FEEF21 "- Set to FF";
CM_ BO_ 2566885210 "- Specific to Siemens Full Elec vehicles. Elfa2 only.";
CM_ BO_ 2566898290 "- CNG and MH only
- MC.W.VCM....VDB: Transmission rate: ''As Needed''";
CM_ SG_ 2566898290 EngStopSw "- BC.A.BCM..24.UwDG.VDB: Gas: one shot 500ms (NBM)";
CM_ BO_ 2565865488 "-  2 Message Variant(s): Transm.Rates 20, 100
-  Specific to Siemens Full Elec vehicles.
-  Read only, no routing on ECB
-  Transmission Rate [ms] 100";
CM_ SG_ 2565865488 RetSelNonEng "- ETC1.ZF.ETC.Ecolife.2..VDB: Not available 0 value (shift selector not connected to the TCU)";
CM_ BO_ 2565865487 "- 1 message instance, SA=0x0F, 0x29, as selected by calibration (Integration Layer)
-  Routing from ERC1_ER";
CM_ SG_ 2566843904 EngOilTemp1 "- FE00h in case of defective sensor";
CM_ SG_ 2566843904 EngFuel1Temp1 "- FEh in case of defective sensor";
CM_ SG_ 2566843904 EngCoolTemp "- FEh in case of defective sensor
-  SAE J1939/73 Freeze Frame parameter";
BA_DEF_ BO_  "CI_MsgDefinition" STRING ;
BA_DEF_ BO_  "CI_MsgId" INT 0 2147483647;
BA_DEF_ BO_  "CI_MsgName" STRING ;
BA_DEF_ BO_  "GenMsgCycleTime" INT 0 3600000;
BA_DEF_ BO_  "GenMsgCycleTimeFast" INT 0 3600000;
BA_DEF_ BO_  "GenMsgDelayTime" INT 0 3600000;
BA_DEF_ BO_  "GenMsgILSupport" ENUM  "No","Yes";
BA_DEF_ BO_  "GenMsgNrOfRepetition" INT 0 1000000;
BA_DEF_ BO_  "GenMsgRequestable" INT 0 1;
BA_DEF_ BO_  "GenMsgSendType" ENUM  "cyclic","NotUsed","NotUsed","NotUsed","NotUsed","NotUsed","NotUsed","IfActive","noMsgSendType";
BA_DEF_ BO_  "GenMsgStartDelayTime" INT 0 100000;
BA_DEF_ BO_  "TpJ1939VarDlc" ENUM  "No","Yes";
BA_DEF_ BO_  "VFrameFormat" ENUM  "StandardCAN","ExtendedCAN","reserved","J1939PG";
BA_DEF_ SG_  "CI_ParId" STRING ;
BA_DEF_ SG_  "CI_SigId" INT 0 2147483647;
BA_DEF_ SG_  "CI_SigName" STRING ;
BA_DEF_ SG_  "GenSigEVName" STRING ;
BA_DEF_ SG_  "GenSigILSupport" ENUM  "No","Yes";
BA_DEF_ SG_  "GenSigInactiveValue" INT 0 2147483647;
BA_DEF_ SG_  "GenSigSendType" ENUM  "Cyclic","OnWrite","OnWriteWithRepetition","OnChange","OnChangeWithRepetition","IfActive","IfActiveWithRepetition","NoSigSendType";
BA_DEF_ SG_  "GenSigStartValue" INT 0 2147483647;
BA_DEF_ SG_  "GenSigTimeoutTime_ACM_CANAIR" INT 0 3600000;
BA_DEF_ SG_  "GenSigTimeoutTime_ACU" INT 0 3600000;
BA_DEF_ SG_  "GenSigTimeoutTime_ADCU" INT 0 3600000;
BA_DEF_ SG_  "GenSigTimeoutTime_AI_CAID" INT 0 3600000;
BA_DEF_ SG_  "GenSigTimeoutTime_ASM_ELC5_Fr" INT 0 3600000;
BA_DEF_ SG_  "GenSigTimeoutTime_AVAS" INT 0 3600000;
BA_DEF_ SG_  "GenSigTimeoutTime_Av2HP" INT 0 3600000;
BA_DEF_ SG_  "GenSigTimeoutTime_BCM_NBM" INT 0 3600000;
BA_DEF_ SG_  "GenSigTimeoutTime_BSM_EBS" INT 0 3600000;
BA_DEF_ SG_  "GenSigTimeoutTime_DICO" INT 0 3600000;
BA_DEF_ SG_  "GenSigTimeoutTime_DMS" INT 0 3600000;
BA_DEF_ SG_  "GenSigTimeoutTime_EBS_EBR" INT 0 3600000;
BA_DEF_ SG_  "GenSigTimeoutTime_ECM_MD1_D" INT 0 3600000;
BA_DEF_ SG_  "GenSigTimeoutTime_ECM_MD1_G" INT 0 3600000;
BA_DEF_ SG_  "GenSigTimeoutTime_ETC_DiwaNXT" INT 0 3600000;
BA_DEF_ SG_  "GenSigTimeoutTime_ETC_DiwaNXT_MH" INT 0 3600000;
BA_DEF_ SG_  "GenSigTimeoutTime_ETC_Ecolife2" INT 0 3600000;
BA_DEF_ SG_  "GenSigTimeoutTime_FCCU" INT 0 3600000;
BA_DEF_ SG_  "GenSigTimeoutTime_FMS_FMS4" INT 0 3600000;
BA_DEF_ SG_  "GenSigTimeoutTime_FMS_FMS5" INT 0 3600000;
BA_DEF_ SG_  "GenSigTimeoutTime_HVPDU_HV_BOX" INT 0 3600000;
BA_DEF_ SG_  "GenSigTimeoutTime_IC_MulticII" INT 0 3600000;
BA_DEF_ SG_  "GenSigTimeoutTime_IC_MulticS" INT 0 3600000;
BA_DEF_ SG_  "GenSigTimeoutTime_INVEM1_ELFA3" INT 0 3600000;
BA_DEF_ SG_  "GenSigTimeoutTime_MBMS" INT 0 3600000;
BA_DEF_ SG_  "GenSigTimeoutTime_MCSL" INT 0 3600000;
BA_DEF_ SG_  "GenSigTimeoutTime_MPPxPTFE2" INT 0 3600000;
BA_DEF_ SG_  "GenSigTimeoutTime_PCM" INT 0 3600000;
BA_DEF_ SG_  "GenSigTimeoutTime_RDAB_SmtRadio" INT 0 3600000;
BA_DEF_ SG_  "GenSigTimeoutTime_RM_INTD" INT 0 3600000;
BA_DEF_ SG_  "GenSigTimeoutTime_RM_IRCS" INT 0 3600000;
BA_DEF_ SG_  "GenSigTimeoutTime_SAS" INT 0 3600000;
BA_DEF_ SG_  "GenSigTimeoutTime_SGW" INT 0 3600000;
BA_DEF_ SG_  "GenSigTimeoutTime_SGW2" INT 0 3600000;
BA_DEF_ SG_  "GenSigTimeoutTime_TASM_ETS" INT 0 3600000;
BA_DEF_ SG_  "GenSigTimeoutTime_TMU_HP_Fr" INT 0 3600000;
BA_DEF_ SG_  "GenSigTimeoutTime_TMU_HP_Rr" INT 0 3600000;
BA_DEF_ SG_  "GenSigTimeoutTime_TPMS" INT 0 3600000;
BA_DEF_ SG_  "GenSigTimeoutTime_Tacho_DTCO" INT 0 3600000;
BA_DEF_ SG_  "GenSigTimeoutTime_Tacho_MTCO" INT 0 3600000;
BA_DEF_ SG_  "GenSigTimeoutTime_Tacho_TSU" INT 0 3600000;
BA_DEF_ SG_  "GenSigTimeoutTime_VCM" INT 0 3600000;
BA_DEF_ SG_  "GenSigTimeoutTime_VCU" INT 0 3600000;
BA_DEF_ SG_  "GenSigTimeoutTime_VMU" INT 0 3600000;
BA_DEF_ SG_  "SPN" INT 0 524287;
BA_DEF_ SG_  "SigType" ENUM  "Default","Range","RangeSigned","ASCII","Discrete","Control","ReferencePGN","DTC","StringDelimiter","StringLength","StringLengthControl";
BA_DEF_DEF_  "CI_MsgDefinition" "";
BA_DEF_DEF_  "CI_MsgId" 0;
BA_DEF_DEF_  "CI_MsgName" "";
BA_DEF_DEF_  "GenMsgCycleTime" 0;
BA_DEF_DEF_  "GenMsgCycleTimeFast" 0;
BA_DEF_DEF_  "GenMsgDelayTime" 1;
BA_DEF_DEF_  "GenMsgILSupport" "Yes";
BA_DEF_DEF_  "GenMsgNrOfRepetition" 0;
BA_DEF_DEF_  "GenMsgRequestable" 0;
BA_DEF_DEF_  "GenMsgSendType" "noMsgSendType";
BA_DEF_DEF_  "GenMsgStartDelayTime" 0;
BA_DEF_DEF_  "TpJ1939VarDlc" "No";
BA_DEF_DEF_  "VFrameFormat" "J1939PG";
BA_DEF_DEF_  "CI_ParId" "";
BA_DEF_DEF_  "CI_SigId" 0;
BA_DEF_DEF_  "CI_SigName" "";
BA_DEF_DEF_  "GenSigEVName" "Env@Nodename_@Signame";
BA_DEF_DEF_  "GenSigILSupport" "Yes";
BA_DEF_DEF_  "GenSigInactiveValue" 0;
BA_DEF_DEF_  "GenSigSendType" "NoSigSendType";
BA_DEF_DEF_  "GenSigStartValue" 0;
BA_DEF_DEF_  "GenSigTimeoutTime_ACM_CANAIR" 0;
BA_DEF_DEF_  "GenSigTimeoutTime_ACU" 0;
BA_DEF_DEF_  "GenSigTimeoutTime_ADCU" 0;
BA_DEF_DEF_  "GenSigTimeoutTime_AI_CAID" 0;
BA_DEF_DEF_  "GenSigTimeoutTime_ASM_ELC5_Fr" 0;
BA_DEF_DEF_  "GenSigTimeoutTime_AVAS" 0;
BA_DEF_DEF_  "GenSigTimeoutTime_Av2HP" 0;
BA_DEF_DEF_  "GenSigTimeoutTime_BCM_NBM" 0;
BA_DEF_DEF_  "GenSigTimeoutTime_BSM_EBS" 0;
BA_DEF_DEF_  "GenSigTimeoutTime_DICO" 0;
BA_DEF_DEF_  "GenSigTimeoutTime_DMS" 0;
BA_DEF_DEF_  "GenSigTimeoutTime_EBS_EBR" 0;
BA_DEF_DEF_  "GenSigTimeoutTime_ECM_MD1_D" 0;
BA_DEF_DEF_  "GenSigTimeoutTime_ECM_MD1_G" 0;
BA_DEF_DEF_  "GenSigTimeoutTime_ETC_DiwaNXT" 0;
BA_DEF_DEF_  "GenSigTimeoutTime_ETC_DiwaNXT_MH" 0;
BA_DEF_DEF_  "GenSigTimeoutTime_ETC_Ecolife2" 0;
BA_DEF_DEF_  "GenSigTimeoutTime_FCCU" 0;
BA_DEF_DEF_  "GenSigTimeoutTime_FMS_FMS4" 0;
BA_DEF_DEF_  "GenSigTimeoutTime_FMS_FMS5" 0;
BA_DEF_DEF_  "GenSigTimeoutTime_HVPDU_HV_BOX" 0;
BA_DEF_DEF_  "GenSigTimeoutTime_IC_MulticII" 0;
BA_DEF_DEF_  "GenSigTimeoutTime_IC_MulticS" 0;
BA_DEF_DEF_  "GenSigTimeoutTime_INVEM1_ELFA3" 0;
BA_DEF_DEF_  "GenSigTimeoutTime_MBMS" 0;
BA_DEF_DEF_  "GenSigTimeoutTime_MCSL" 0;
BA_DEF_DEF_  "GenSigTimeoutTime_MPPxPTFE2" 0;
BA_DEF_DEF_  "GenSigTimeoutTime_PCM" 0;
BA_DEF_DEF_  "GenSigTimeoutTime_RDAB_SmtRadio" 0;
BA_DEF_DEF_  "GenSigTimeoutTime_RM_INTD" 0;
BA_DEF_DEF_  "GenSigTimeoutTime_RM_IRCS" 0;
BA_DEF_DEF_  "GenSigTimeoutTime_SAS" 0;
BA_DEF_DEF_  "GenSigTimeoutTime_SGW" 0;
BA_DEF_DEF_  "GenSigTimeoutTime_SGW2" 0;
BA_DEF_DEF_  "GenSigTimeoutTime_TASM_ETS" 0;
BA_DEF_DEF_  "GenSigTimeoutTime_TMU_HP_Fr" 0;
BA_DEF_DEF_  "GenSigTimeoutTime_TMU_HP_Rr" 0;
BA_DEF_DEF_  "GenSigTimeoutTime_TPMS" 0;
BA_DEF_DEF_  "GenSigTimeoutTime_Tacho_DTCO" 0;
BA_DEF_DEF_  "GenSigTimeoutTime_Tacho_MTCO" 0;
BA_DEF_DEF_  "GenSigTimeoutTime_Tacho_TSU" 0;
BA_DEF_DEF_  "GenSigTimeoutTime_VCM" 0;
BA_DEF_DEF_  "GenSigTimeoutTime_VCU" 0;
BA_DEF_DEF_  "GenSigTimeoutTime_VMU" 0;
BA_DEF_DEF_  "SPN" 0;
BA_DEF_DEF_  "SigType" "Default";
BA_ "GenMsgStartDelayTime" BO_ 2561142090 118;
BA_ "GenMsgSendType" BO_ 2561142090 0;
BA_ "GenMsgDelayTime" BO_ 2561142090 500;
BA_ "GenMsgCycleTimeFast" BO_ 2561142090 1000;
BA_ "GenMsgCycleTime" BO_ 2561142090 1000;
BA_ "CI_MsgName" BO_ 2561142090 "DSE_LATERAL - DSE Lateral";
BA_ "CI_MsgId" BO_ 2561142090 14406;
BA_ "CI_MsgDefinition" BO_ 2561142090 "Iveco Bus Proprietary";
BA_ "GenMsgStartDelayTime" BO_ 2561143114 126;
BA_ "GenMsgSendType" BO_ 2561143114 0;
BA_ "GenMsgDelayTime" BO_ 2561143114 500;
BA_ "GenMsgCycleTimeFast" BO_ 2561143114 1000;
BA_ "GenMsgCycleTime" BO_ 2561143114 1000;
BA_ "CI_MsgName" BO_ 2561143114 "DSE_LATERAL_DBG - DSE Lateral DBG";
BA_ "CI_MsgId" BO_ 2561143114 14412;
BA_ "CI_MsgDefinition" BO_ 2561143114 "Iveco Bus Proprietary";
BA_ "GenMsgStartDelayTime" BO_ 2561134666 62;
BA_ "GenMsgSendType" BO_ 2561134666 0;
BA_ "GenMsgDelayTime" BO_ 2561134666 500;
BA_ "GenMsgCycleTimeFast" BO_ 2561134666 1000;
BA_ "GenMsgCycleTime" BO_ 2561134666 1000;
BA_ "CI_MsgName" BO_ 2561134666 "DSE_LNDPT - DSE Lane departure";
BA_ "CI_MsgId" BO_ 2561134666 14415;
BA_ "CI_MsgDefinition" BO_ 2561134666 "Iveco Bus Proprietary";
BA_ "GenMsgStartDelayTime" BO_ 2561134922 64;
BA_ "GenMsgSendType" BO_ 2561134922 0;
BA_ "GenMsgDelayTime" BO_ 2561134922 500;
BA_ "GenMsgCycleTimeFast" BO_ 2561134922 1000;
BA_ "GenMsgCycleTime" BO_ 2561134922 1000;
BA_ "CI_MsgName" BO_ 2561134922 "DSE_LNDPT_DBG - DSE Lane departure DBG";
BA_ "CI_MsgId" BO_ 2561134922 14421;
BA_ "CI_MsgDefinition" BO_ 2561134922 "Iveco Bus Proprietary";
BA_ "GenMsgStartDelayTime" BO_ 2561142346 120;
BA_ "GenMsgSendType" BO_ 2561142346 0;
BA_ "GenMsgDelayTime" BO_ 2561142346 500;
BA_ "GenMsgCycleTimeFast" BO_ 2561142346 1000;
BA_ "GenMsgCycleTime" BO_ 2561142346 1000;
BA_ "CI_MsgName" BO_ 2561142346 "DSE_LONGITUDINAL - DSE Longitudinal";
BA_ "CI_MsgId" BO_ 2561142346 14424;
BA_ "CI_MsgDefinition" BO_ 2561142346 "Iveco Bus Proprietary";
BA_ "GenMsgStartDelayTime" BO_ 2561143370 128;
BA_ "GenMsgSendType" BO_ 2561143370 0;
BA_ "GenMsgDelayTime" BO_ 2561143370 500;
BA_ "GenMsgCycleTimeFast" BO_ 2561143370 1000;
BA_ "GenMsgCycleTime" BO_ 2561143370 1000;
BA_ "CI_MsgName" BO_ 2561143370 "DSE_LONGITUDINAL_DBG - DSE Longitudinal DBG";
BA_ "CI_MsgId" BO_ 2561143370 14430;
BA_ "CI_MsgDefinition" BO_ 2561143370 "Iveco Bus Proprietary";
BA_ "GenMsgStartDelayTime" BO_ 2561146186 150;
BA_ "GenMsgSendType" BO_ 2561146186 0;
BA_ "GenMsgDelayTime" BO_ 2561146186 500;
BA_ "GenMsgCycleTimeFast" BO_ 2561146186 1000;
BA_ "GenMsgCycleTime" BO_ 2561146186 1000;
BA_ "CI_MsgName" BO_ 2561146186 "DSE_MOIS - DSE Mois";
BA_ "CI_MsgId" BO_ 2561146186 14511;
BA_ "CI_MsgDefinition" BO_ 2561146186 "Iveco Bus Proprietary";
BA_ "GenMsgStartDelayTime" BO_ 2561135178 66;
BA_ "GenMsgSendType" BO_ 2561135178 0;
BA_ "GenMsgDelayTime" BO_ 2561135178 500;
BA_ "GenMsgCycleTimeFast" BO_ 2561135178 1000;
BA_ "GenMsgCycleTime" BO_ 2561135178 1000;
BA_ "CI_MsgName" BO_ 2561135178 "DSE_NOTF - DSE Notification";
BA_ "CI_MsgId" BO_ 2561135178 14517;
BA_ "CI_MsgDefinition" BO_ 2561135178 "Iveco Bus Proprietary";
BA_ "GenMsgStartDelayTime" BO_ 2561141322 112;
BA_ "GenMsgSendType" BO_ 2561141322 0;
BA_ "GenMsgDelayTime" BO_ 2561141322 500;
BA_ "GenMsgCycleTimeFast" BO_ 2561141322 1000;
BA_ "GenMsgCycleTime" BO_ 2561141322 1000;
BA_ "CI_MsgName" BO_ 2561141322 "DSE_OFFB_INDEX - DSE OFFB Index";
BA_ "CI_MsgId" BO_ 2561141322 14522;
BA_ "CI_MsgDefinition" BO_ 2561141322 "Iveco Bus Proprietary";
BA_ "GenMsgStartDelayTime" BO_ 2561141578 114;
BA_ "GenMsgSendType" BO_ 2561141578 0;
BA_ "GenMsgDelayTime" BO_ 2561141578 500;
BA_ "GenMsgCycleTimeFast" BO_ 2561141578 1000;
BA_ "GenMsgCycleTime" BO_ 2561141578 1000;
BA_ "CI_MsgName" BO_ 2561141578 "DSE_OFFB_METRICS - DSE OFFB METRICS";
BA_ "CI_MsgId" BO_ 2561141578 14530;
BA_ "CI_MsgDefinition" BO_ 2561141578 "Iveco Bus Proprietary";
BA_ "GenMsgStartDelayTime" BO_ 2561135434 68;
BA_ "GenMsgSendType" BO_ 2561135434 0;
BA_ "GenMsgDelayTime" BO_ 2561135434 500;
BA_ "GenMsgCycleTimeFast" BO_ 2561135434 1000;
BA_ "GenMsgCycleTime" BO_ 2561135434 1000;
BA_ "CI_MsgName" BO_ 2561135434 "DSE_OLDDAS - DSE OldDas";
BA_ "CI_MsgId" BO_ 2561135434 14538;
BA_ "CI_MsgDefinition" BO_ 2561135434 "Iveco Bus Proprietary";
BA_ "GenMsgStartDelayTime" BO_ 2561142858 124;
BA_ "GenMsgSendType" BO_ 2561142858 0;
BA_ "GenMsgDelayTime" BO_ 2561142858 500;
BA_ "GenMsgCycleTimeFast" BO_ 2561142858 1000;
BA_ "GenMsgCycleTime" BO_ 2561142858 1000;
BA_ "CI_MsgName" BO_ 2561142858 "DSE_PCM_ACCEL - DSE PCM Accelerometer";
BA_ "CI_MsgId" BO_ 2561142858 14544;
BA_ "CI_MsgDefinition" BO_ 2561142858 "Iveco Bus Proprietary";
BA_ "GenMsgStartDelayTime" BO_ 2561135690 70;
BA_ "GenMsgSendType" BO_ 2561135690 0;
BA_ "GenMsgDelayTime" BO_ 2561135690 500;
BA_ "GenMsgCycleTimeFast" BO_ 2561135690 1000;
BA_ "GenMsgCycleTime" BO_ 2561135690 1000;
BA_ "CI_MsgName" BO_ 2561135690 "DSE_PECC - DSE Pecc";
BA_ "CI_MsgId" BO_ 2561135690 14548;
BA_ "CI_MsgDefinition" BO_ 2561135690 "Iveco Bus Proprietary";
BA_ "GenMsgStartDelayTime" BO_ 2561135946 72;
BA_ "GenMsgSendType" BO_ 2561135946 0;
BA_ "GenMsgDelayTime" BO_ 2561135946 500;
BA_ "GenMsgCycleTimeFast" BO_ 2561135946 1000;
BA_ "GenMsgCycleTime" BO_ 2561135946 1000;
BA_ "CI_MsgName" BO_ 2561135946 "DSE_PECC_DBG - DSE Pecc DBG";
BA_ "CI_MsgId" BO_ 2561135946 14554;
BA_ "CI_MsgDefinition" BO_ 2561135946 "Iveco Bus Proprietary";
BA_ "GenMsgStartDelayTime" BO_ 2561136202 74;
BA_ "GenMsgSendType" BO_ 2561136202 0;
BA_ "GenMsgDelayTime" BO_ 2561136202 500;
BA_ "GenMsgCycleTimeFast" BO_ 2561136202 1000;
BA_ "GenMsgCycleTime" BO_ 2561136202 1000;
BA_ "CI_MsgName" BO_ 2561136202 "DSE_RAD - DSE Radar";
BA_ "CI_MsgId" BO_ 2561136202 14557;
BA_ "CI_MsgDefinition" BO_ 2561136202 "Iveco Bus Proprietary";
BA_ "GenMsgStartDelayTime" BO_ 2561136458 76;
BA_ "GenMsgSendType" BO_ 2561136458 0;
BA_ "GenMsgDelayTime" BO_ 2561136458 500;
BA_ "GenMsgCycleTimeFast" BO_ 2561136458 1000;
BA_ "GenMsgCycleTime" BO_ 2561136458 1000;
BA_ "CI_MsgName" BO_ 2561136458 "DSE_RAD_DBG - DSE Radar DBG";
BA_ "CI_MsgId" BO_ 2561136458 14563;
BA_ "CI_MsgDefinition" BO_ 2561136458 "Iveco Bus Proprietary";
BA_ "GenMsgStartDelayTime" BO_ 2561136714 78;
BA_ "GenMsgSendType" BO_ 2561136714 0;
BA_ "GenMsgDelayTime" BO_ 2561136714 500;
BA_ "GenMsgCycleTimeFast" BO_ 2561136714 1000;
BA_ "GenMsgCycleTime" BO_ 2561136714 1000;
BA_ "CI_MsgName" BO_ 2561136714 "DSE_RPM - DSE Rpm";
BA_ "CI_MsgId" BO_ 2561136714 14566;
BA_ "CI_MsgDefinition" BO_ 2561136714 "Iveco Bus Proprietary";
BA_ "GenMsgStartDelayTime" BO_ 2561136970 80;
BA_ "GenMsgSendType" BO_ 2561136970 0;
BA_ "GenMsgDelayTime" BO_ 2561136970 500;
BA_ "GenMsgCycleTimeFast" BO_ 2561136970 1000;
BA_ "GenMsgCycleTime" BO_ 2561136970 1000;
BA_ "CI_MsgName" BO_ 2561136970 "DSE_RPM_DBG - DSE Rpm DBG";
BA_ "CI_MsgId" BO_ 2561136970 14572;
BA_ "CI_MsgDefinition" BO_ 2561136970 "Iveco Bus Proprietary";
BA_ "GenMsgStartDelayTime" BO_ 2561145162 142;
BA_ "GenMsgSendType" BO_ 2561145162 0;
BA_ "GenMsgDelayTime" BO_ 2561145162 500;
BA_ "GenMsgCycleTimeFast" BO_ 2561145162 1000;
BA_ "GenMsgCycleTime" BO_ 2561145162 1000;
BA_ "CI_MsgName" BO_ 2561145162 "DSE_SAFEDIST - DSE Safe Distance";
BA_ "CI_MsgId" BO_ 2561145162 14583;
BA_ "CI_MsgDefinition" BO_ 2561145162 "Iveco Bus Proprietary";
BA_ "GenMsgStartDelayTime" BO_ 2561145418 144;
BA_ "GenMsgSendType" BO_ 2561145418 0;
BA_ "GenMsgDelayTime" BO_ 2561145418 500;
BA_ "GenMsgCycleTimeFast" BO_ 2561145418 1000;
BA_ "GenMsgCycleTime" BO_ 2561145418 1000;
BA_ "CI_MsgName" BO_ 2561145418 "DSE_SAFEPOS - DSE Safe Position";
BA_ "CI_MsgId" BO_ 2561145418 14589;
BA_ "CI_MsgDefinition" BO_ 2561145418 "Iveco Bus Proprietary";
BA_ "GenMsgStartDelayTime" BO_ 2561137226 82;
BA_ "GenMsgSendType" BO_ 2561137226 0;
BA_ "GenMsgDelayTime" BO_ 2561137226 500;
BA_ "GenMsgCycleTimeFast" BO_ 2561137226 1000;
BA_ "GenMsgCycleTime" BO_ 2561137226 1000;
BA_ "CI_MsgName" BO_ 2561137226 "DSE_SAFETY - DSE Safety";
BA_ "CI_MsgId" BO_ 2561137226 14595;
BA_ "CI_MsgDefinition" BO_ 2561137226 "Iveco Bus Proprietary";
BA_ "GenMsgStartDelayTime" BO_ 2561137482 84;
BA_ "GenMsgSendType" BO_ 2561137482 0;
BA_ "GenMsgDelayTime" BO_ 2561137482 500;
BA_ "GenMsgCycleTimeFast" BO_ 2561137482 1000;
BA_ "GenMsgCycleTime" BO_ 2561137482 1000;
BA_ "CI_MsgName" BO_ 2561137482 "DSE_SF_TIRE - DSE Tire safety";
BA_ "CI_MsgId" BO_ 2561137482 14601;
BA_ "CI_MsgDefinition" BO_ 2561137482 "Iveco Bus Proprietary";
BA_ "GenMsgStartDelayTime" BO_ 2561137738 86;
BA_ "GenMsgSendType" BO_ 2561137738 0;
BA_ "GenMsgDelayTime" BO_ 2561137738 500;
BA_ "GenMsgCycleTimeFast" BO_ 2561137738 1000;
BA_ "GenMsgCycleTime" BO_ 2561137738 1000;
BA_ "CI_MsgName" BO_ 2561137738 "DSE_SF_TIRE_DBG - DSE Tire safety DBG";
BA_ "CI_MsgId" BO_ 2561137738 14607;
BA_ "CI_MsgDefinition" BO_ 2561137738 "Iveco Bus Proprietary";
BA_ "GenMsgStartDelayTime" BO_ 2561144650 138;
BA_ "GenMsgSendType" BO_ 2561144650 0;
BA_ "GenMsgDelayTime" BO_ 2561144650 500;
BA_ "GenMsgCycleTimeFast" BO_ 2561144650 1000;
BA_ "GenMsgCycleTime" BO_ 2561144650 1000;
BA_ "CI_MsgName" BO_ 2561144650 "DSE_SLOWMAN - DSE Slow Maneuver";
BA_ "CI_MsgId" BO_ 2561144650 14610;
BA_ "CI_MsgDefinition" BO_ 2561144650 "Iveco Bus Proprietary";
BA_ "GenMsgStartDelayTime" BO_ 2561144394 136;
BA_ "GenMsgSendType" BO_ 2561144394 0;
BA_ "GenMsgDelayTime" BO_ 2561144394 500;
BA_ "GenMsgCycleTimeFast" BO_ 2561144394 1000;
BA_ "GenMsgCycleTime" BO_ 2561144394 1000;
BA_ "CI_MsgName" BO_ 2561144394 "DSE_SPEED - DSE Speed";
BA_ "CI_MsgId" BO_ 2561144394 14616;
BA_ "CI_MsgDefinition" BO_ 2561144394 "Iveco Bus Proprietary";
BA_ "GenMsgStartDelayTime" BO_ 2561137994 88;
BA_ "GenMsgSendType" BO_ 2561137994 0;
BA_ "GenMsgDelayTime" BO_ 2561137994 500;
BA_ "GenMsgCycleTimeFast" BO_ 2561137994 1000;
BA_ "GenMsgCycleTime" BO_ 2561137994 1000;
BA_ "CI_MsgName" BO_ 2561137994 "DSE_START - DSE Start";
BA_ "CI_MsgId" BO_ 2561137994 14622;
BA_ "CI_MsgDefinition" BO_ 2561137994 "Iveco Bus Proprietary";
BA_ "GenMsgStartDelayTime" BO_ 2566875466 2;
BA_ "GenMsgSendType" BO_ 2566875466 0;
BA_ "GenMsgDelayTime" BO_ 2566875466 250;
BA_ "GenMsgCycleTimeFast" BO_ 2566875466 500;
BA_ "GenMsgCycleTime" BO_ 2566875466 500;
BA_ "CI_MsgName" BO_ 2566875466 "DSE_STATUS - DSE Status Harsh";
BA_ "CI_MsgId" BO_ 2566875466 1912;
BA_ "CI_MsgDefinition" BO_ 2566875466 "Iveco Proprietary";
BA_ "GenMsgStartDelayTime" BO_ 2561138250 90;
BA_ "GenMsgSendType" BO_ 2561138250 0;
BA_ "GenMsgDelayTime" BO_ 2561138250 500;
BA_ "GenMsgCycleTimeFast" BO_ 2561138250 1000;
BA_ "GenMsgCycleTime" BO_ 2561138250 1000;
BA_ "CI_MsgName" BO_ 2561138250 "DSE_STATUS_TRIP - DSE Status Trip";
BA_ "CI_MsgId" BO_ 2561138250 14625;
BA_ "CI_MsgDefinition" BO_ 2561138250 "Iveco Bus Proprietary";
BA_ "GenMsgStartDelayTime" BO_ 2561138506 92;
BA_ "GenMsgSendType" BO_ 2561138506 0;
BA_ "GenMsgDelayTime" BO_ 2561138506 500;
BA_ "GenMsgCycleTimeFast" BO_ 2561138506 1000;
BA_ "GenMsgCycleTime" BO_ 2561138506 1000;
BA_ "CI_MsgName" BO_ 2561138506 "DSE_STCNT - DSE Stability Control";
BA_ "CI_MsgId" BO_ 2561138506 14630;
BA_ "CI_MsgDefinition" BO_ 2561138506 "Iveco Bus Proprietary";
BA_ "GenMsgStartDelayTime" BO_ 2561138762 94;
BA_ "GenMsgSendType" BO_ 2561138762 0;
BA_ "GenMsgDelayTime" BO_ 2561138762 500;
BA_ "GenMsgCycleTimeFast" BO_ 2561138762 1000;
BA_ "GenMsgCycleTime" BO_ 2561138762 1000;
BA_ "CI_MsgName" BO_ 2561138762 "DSE_STCNT_DBG - DSE Stability Control DBG";
BA_ "CI_MsgId" BO_ 2561138762 14636;
BA_ "CI_MsgDefinition" BO_ 2561138762 "Iveco Bus Proprietary";
BA_ "GenMsgStartDelayTime" BO_ 2561139018 96;
BA_ "GenMsgSendType" BO_ 2561139018 0;
BA_ "GenMsgDelayTime" BO_ 2561139018 500;
BA_ "GenMsgCycleTimeFast" BO_ 2561139018 1000;
BA_ "GenMsgCycleTime" BO_ 2561139018 1000;
BA_ "CI_MsgName" BO_ 2561139018 "DSE_STOP - DSE Stop";
BA_ "CI_MsgId" BO_ 2561139018 14639;
BA_ "CI_MsgDefinition" BO_ 2561139018 "Iveco Bus Proprietary";
BA_ "GenMsgStartDelayTime" BO_ 2561139274 98;
BA_ "GenMsgSendType" BO_ 2561139274 0;
BA_ "GenMsgDelayTime" BO_ 2561139274 500;
BA_ "GenMsgCycleTimeFast" BO_ 2561139274 1000;
BA_ "GenMsgCycleTime" BO_ 2561139274 1000;
BA_ "CI_MsgName" BO_ 2561139274 "DSE_STOP_DBG - DSE Stop DBG";
BA_ "CI_MsgId" BO_ 2561139274 14645;
BA_ "CI_MsgDefinition" BO_ 2561139274 "Iveco Bus Proprietary";
BA_ "GenMsgStartDelayTime" BO_ 2561141066 110;
BA_ "GenMsgSendType" BO_ 2561141066 0;
BA_ "GenMsgDelayTime" BO_ 2561141066 500;
BA_ "GenMsgCycleTimeFast" BO_ 2561141066 1000;
BA_ "GenMsgCycleTime" BO_ 2561141066 1000;
BA_ "CI_MsgName" BO_ 2561141066 "DSE_TEVENT - DSE TEvent";
BA_ "CI_MsgId" BO_ 2561141066 14653;
BA_ "CI_MsgDefinition" BO_ 2561141066 "Iveco Bus Proprietary";
BA_ "GenMsgStartDelayTime" BO_ 2561139530 100;
BA_ "GenMsgSendType" BO_ 2561139530 0;
BA_ "GenMsgDelayTime" BO_ 2561139530 500;
BA_ "GenMsgCycleTimeFast" BO_ 2561139530 1000;
BA_ "GenMsgCycleTime" BO_ 2561139530 1000;
BA_ "CI_MsgName" BO_ 2561139530 "DSE_TIRE - DSE Tire";
BA_ "CI_MsgId" BO_ 2561139530 14660;
BA_ "CI_MsgDefinition" BO_ 2561139530 "Iveco Bus Proprietary";
BA_ "GenMsgStartDelayTime" BO_ 2561139786 102;
BA_ "GenMsgSendType" BO_ 2561139786 0;
BA_ "GenMsgDelayTime" BO_ 2561139786 500;
BA_ "GenMsgCycleTimeFast" BO_ 2561139786 1000;
BA_ "GenMsgCycleTime" BO_ 2561139786 1000;
BA_ "CI_MsgName" BO_ 2561139786 "DSE_TIRE_DBG - DSE Tire DBG";
BA_ "CI_MsgId" BO_ 2561139786 14666;
BA_ "CI_MsgDefinition" BO_ 2561139786 "Iveco Bus Proprietary";
BA_ "GenMsgStartDelayTime" BO_ 2561145674 146;
BA_ "GenMsgSendType" BO_ 2561145674 0;
BA_ "GenMsgDelayTime" BO_ 2561145674 500;
BA_ "GenMsgCycleTimeFast" BO_ 2561145674 1000;
BA_ "GenMsgCycleTime" BO_ 2561145674 1000;
BA_ "CI_MsgName" BO_ 2561145674 "DSE_TRIP_B - DSE TripB";
BA_ "CI_MsgId" BO_ 2561145674 14669;
BA_ "CI_MsgDefinition" BO_ 2561145674 "Iveco Bus Proprietary";
BA_ "GenMsgStartDelayTime" BO_ 2561144906 140;
BA_ "GenMsgSendType" BO_ 2561144906 0;
BA_ "GenMsgDelayTime" BO_ 2561144906 500;
BA_ "GenMsgCycleTimeFast" BO_ 2561144906 1000;
BA_ "GenMsgCycleTime" BO_ 2561144906 1000;
BA_ "CI_MsgName" BO_ 2561144906 "DSE_VEHCONT - DSE Vehicle Control";
BA_ "CI_MsgId" BO_ 2561144906 14675;
BA_ "CI_MsgDefinition" BO_ 2561144906 "Iveco Bus Proprietary";
BA_ "GenMsgStartDelayTime" BO_ 2561140298 104;
BA_ "GenMsgSendType" BO_ 2561140298 0;
BA_ "GenMsgDelayTime" BO_ 2561140298 500;
BA_ "GenMsgCycleTimeFast" BO_ 2561140298 1000;
BA_ "GenMsgCycleTime" BO_ 2561140298 1000;
BA_ "CI_MsgName" BO_ 2561140298 "DSE_VER - DSE Version";
BA_ "CI_MsgId" BO_ 2561140298 14681;
BA_ "CI_MsgDefinition" BO_ 2561140298 "Iveco Bus Proprietary";
BA_ "GenMsgStartDelayTime" BO_ 2561142602 122;
BA_ "GenMsgSendType" BO_ 2561142602 0;
BA_ "GenMsgDelayTime" BO_ 2561142602 500;
BA_ "GenMsgCycleTimeFast" BO_ 2561142602 1000;
BA_ "GenMsgCycleTime" BO_ 2561142602 1000;
BA_ "CI_MsgName" BO_ 2561142602 "DSE_VERTICAL - DSE Vertical";
BA_ "CI_MsgId" BO_ 2561142602 14686;
BA_ "CI_MsgDefinition" BO_ 2561142602 "Iveco Bus Proprietary";
BA_ "GenMsgStartDelayTime" BO_ 2561143626 130;
BA_ "GenMsgSendType" BO_ 2561143626 0;
BA_ "GenMsgDelayTime" BO_ 2561143626 500;
BA_ "GenMsgCycleTimeFast" BO_ 2561143626 1000;
BA_ "GenMsgCycleTime" BO_ 2561143626 1000;
BA_ "CI_MsgName" BO_ 2561143626 "DSE_VERTICAL_DBG - DSE Vertical DBG";
BA_ "CI_MsgId" BO_ 2561143626 14692;
BA_ "CI_MsgDefinition" BO_ 2561143626 "Iveco Bus Proprietary";
BA_ "GenMsgStartDelayTime" BO_ 2565865739 4;
BA_ "GenMsgSendType" BO_ 2565865739 0;
BA_ "GenMsgDelayTime" BO_ 2565865739 50;
BA_ "GenMsgCycleTimeFast" BO_ 2565865739 100;
BA_ "GenMsgCycleTime" BO_ 2565865739 100;
BA_ "CI_MsgName" BO_ 2565865739 "EBC1 - Electronic Brake Controller 1";
BA_ "CI_MsgId" BO_ 2565865739 229;
BA_ "CI_MsgDefinition" BO_ 2565865739 "J1939DA";
BA_ "GenMsgStartDelayTime" BO_ 2566831883 2;
BA_ "GenMsgSendType" BO_ 2566831883 0;
BA_ "GenMsgDelayTime" BO_ 2566831883 25;
BA_ "GenMsgCycleTimeFast" BO_ 2566831883 50;
BA_ "GenMsgCycleTime" BO_ 2566831883 50;
BA_ "CI_MsgName" BO_ 2566831883 "EBC2 - Wheel Speed Information";
BA_ "CI_MsgId" BO_ 2566831883 266;
BA_ "CI_MsgDefinition" BO_ 2566831883 "J1939DA";
BA_ "GenMsgStartDelayTime" BO_ 2633935883 55;
BA_ "GenMsgSendType" BO_ 2633935883 0;
BA_ "GenMsgDelayTime" BO_ 2633935883 2500;
BA_ "GenMsgCycleTimeFast" BO_ 2633935883 5000;
BA_ "GenMsgCycleTime" BO_ 2633935883 5000;
BA_ "CI_MsgName" BO_ 2633935883 "EBC4_A - Wheel Brake Lining Remaining Information";
BA_ "CI_MsgId" BO_ 2633935883 292;
BA_ "CI_MsgDefinition" BO_ 2633935883 "J1939DA";
BA_ "GenMsgStartDelayTime" BO_ 2566767627 16;
BA_ "GenMsgSendType" BO_ 2566767627 0;
BA_ "GenMsgDelayTime" BO_ 2566767627 50;
BA_ "GenMsgCycleTimeFast" BO_ 2566767627 100;
BA_ "GenMsgCycleTime" BO_ 2566767627 100;
BA_ "CI_MsgName" BO_ 2566767627 "EBC5 - Electronic Brake Controller 5";
BA_ "CI_MsgId" BO_ 2566767627 301;
BA_ "CI_MsgDefinition" BO_ 2566767627 "J1939DA";
BA_ "GenMsgStartDelayTime" BO_ 2566841088 44;
BA_ "GenMsgSendType" BO_ 2566841088 0;
BA_ "GenMsgDelayTime" BO_ 2566841088 500;
BA_ "GenMsgCycleTimeFast" BO_ 2566841088 5000;
BA_ "GenMsgCycleTime" BO_ 2566841088 5000;
BA_ "CI_MsgName" BO_ 2566841088 "EC1_00_E3 - Engine Configuration 1";
BA_ "CI_MsgId" BO_ 2566841088 965;
BA_ "CI_MsgDefinition" BO_ 2566841088 "J1939DA";
BA_ "GenMsgStartDelayTime" BO_ 2566841216 13;
BA_ "GenMsgSendType" BO_ 2566841216 0;
BA_ "GenMsgDelayTime" BO_ 2566841216 500;
BA_ "GenMsgCycleTimeFast" BO_ 2566841216 2000;
BA_ "GenMsgCycleTime" BO_ 2566841216 2000;
BA_ "CI_MsgName" BO_ 2566841216 "EC1_80 - Engine Configuration 1";
BA_ "CI_MsgId" BO_ 2566841216 994;
BA_ "CI_MsgDefinition" BO_ 2566841216 "J1939DA";
BA_ "GenMsgStartDelayTime" BO_ 2566891081 2;
BA_ "GenMsgSendType" BO_ 2566891081 0;
BA_ "GenMsgDelayTime" BO_ 2566891081 500;
BA_ "GenMsgCycleTimeFast" BO_ 2566891081 1000;
BA_ "GenMsgCycleTime" BO_ 2566891081 1000;
BA_ "CI_MsgName" BO_ 2566891081 "ECCU_Inf1 - ECCU_Information_1 - Embedded Charging Control Unit ";
BA_ "CI_MsgId" BO_ 2566891081 2904;
BA_ "CI_MsgDefinition" BO_ 2566891081 "Iveco Proprietary";
BA_ "GenMsgStartDelayTime" BO_ 2566889801 6;
BA_ "GenMsgSendType" BO_ 2566889801 0;
BA_ "GenMsgDelayTime" BO_ 2566889801 2500;
BA_ "GenMsgCycleTimeFast" BO_ 2566889801 5000;
BA_ "GenMsgCycleTime" BO_ 2566889801 5000;
BA_ "CI_MsgName" BO_ 2566889801 "ECCU2SCU_49 - Embedded Charging Control Unit to Supervisor";
BA_ "CI_MsgId" BO_ 2566889801 4033;
BA_ "CI_MsgDefinition" BO_ 2566889801 "Iveco Proprietary";
BA_ "GenMsgStartDelayTime" BO_ 2566767966 4;
BA_ "GenMsgSendType" BO_ 2566767966 0;
BA_ "GenMsgDelayTime" BO_ 2566767966 500;
BA_ "GenMsgCycleTimeFast" BO_ 2566767966 1000;
BA_ "GenMsgCycleTime" BO_ 2566767966 1000;
BA_ "CI_MsgName" BO_ 2566767966 "ECU_CAID2 - ECU Identification CAID2";
BA_ "CI_MsgId" BO_ 2566767966 10343;
BA_ "CI_MsgDefinition" BO_ 2566767966 "J1939DA";
BA_ "TpJ1939VarDlc" BO_ 2566767901 1;
BA_ "CI_MsgName" BO_ 2566767901 "ECUID_1D - ECU Identification Information";
BA_ "CI_MsgId" BO_ 2566767901 10322;
BA_ "CI_MsgDefinition" BO_ 2566767901 "J1939DA";
BA_ "GenMsgStartDelayTime" BO_ 2566849280 13;
BA_ "GenMsgSendType" BO_ 2566849280 0;
BA_ "GenMsgDelayTime" BO_ 2566849280 25;
BA_ "GenMsgCycleTimeFast" BO_ 2566849280 50;
BA_ "GenMsgCycleTime" BO_ 2566849280 50;
BA_ "CI_MsgName" BO_ 2566849280 "Edc2BcIC - EDC to Body Computer - IC";
BA_ "CI_MsgId" BO_ 2566849280 4048;
BA_ "CI_MsgDefinition" BO_ 2566849280 "Iveco SPR1 Proprietary";
BA_ "GenMsgStartDelayTime" BO_ 2364539904 8;
BA_ "GenMsgSendType" BO_ 2364539904 0;
BA_ "GenMsgDelayTime" BO_ 2364539904 5;
BA_ "GenMsgCycleTimeFast" BO_ 2364539904 10;
BA_ "GenMsgCycleTime" BO_ 2364539904 10;
BA_ "CI_MsgName" BO_ 2364539904 "EEC1 - Electronic Engine Controller 1";
BA_ "CI_MsgId" BO_ 2364539904 836;
BA_ "CI_MsgDefinition" BO_ 2364539904 "J1939DA";
BA_ "GenMsgStartDelayTime" BO_ 2364540032 2;
BA_ "GenMsgSendType" BO_ 2364540032 0;
BA_ "GenMsgDelayTime" BO_ 2364540032 5;
BA_ "GenMsgCycleTimeFast" BO_ 2364540032 10;
BA_ "GenMsgCycleTime" BO_ 2364540032 10;
BA_ "CI_MsgName" BO_ 2364540032 "EEC1_80 - Electronic Engine Controller 1";
BA_ "CI_MsgId" BO_ 2364540032 855;
BA_ "CI_MsgDefinition" BO_ 2364540032 "J1939DA";
BA_ "GenMsgStartDelayTime" BO_ 2566767127 127;
BA_ "GenMsgSendType" BO_ 2566767127 0;
BA_ "GenMsgDelayTime" BO_ 2566767127 5000;
BA_ "GenMsgCycleTimeFast" BO_ 2566767127 10000;
BA_ "GenMsgCycleTime" BO_ 2566767127 10000;
BA_ "CI_MsgName" BO_ 2566767127 "EEC14_17 - Engine Configuration";
BA_ "CI_MsgId" BO_ 2566767127 959;
BA_ "CI_MsgDefinition" BO_ 2566767127 "J1939DA";
BA_ "GenMsgStartDelayTime" BO_ 2364539648 11;
BA_ "GenMsgSendType" BO_ 2364539648 0;
BA_ "GenMsgDelayTime" BO_ 2364539648 25;
BA_ "GenMsgCycleTimeFast" BO_ 2364539648 50;
BA_ "GenMsgCycleTime" BO_ 2364539648 50;
BA_ "CI_MsgName" BO_ 2364539648 "EEC2 - Electronic Engine Controller 2";
BA_ "CI_MsgId" BO_ 2364539648 863;
BA_ "CI_MsgDefinition" BO_ 2364539648 "J1939DA";
BA_ "GenMsgStartDelayTime" BO_ 2364539776 6;
BA_ "GenMsgSendType" BO_ 2364539776 0;
BA_ "GenMsgDelayTime" BO_ 2364539776 25;
BA_ "GenMsgCycleTimeFast" BO_ 2364539776 50;
BA_ "GenMsgCycleTime" BO_ 2364539776 50;
BA_ "CI_MsgName" BO_ 2364539776 "EEC2_80 - Electronic Engine Controller 2";
BA_ "CI_MsgId" BO_ 2364539776 878;
BA_ "CI_MsgDefinition" BO_ 2364539776 "J1939DA";
BA_ "GenMsgStartDelayTime" BO_ 2566840064 32;
BA_ "GenMsgSendType" BO_ 2566840064 0;
BA_ "GenMsgDelayTime" BO_ 2566840064 125;
BA_ "GenMsgCycleTimeFast" BO_ 2566840064 250;
BA_ "GenMsgCycleTime" BO_ 2566840064 250;
BA_ "CI_MsgName" BO_ 2566840064 "EEC3 - Electronic Engine Controller 3";
BA_ "CI_MsgId" BO_ 2566840064 931;
BA_ "CI_MsgDefinition" BO_ 2566840064 "J1939DA";
BA_ "GenMsgStartDelayTime" BO_ 2566840192 17;
BA_ "GenMsgSendType" BO_ 2566840192 0;
BA_ "GenMsgDelayTime" BO_ 2566840192 100;
BA_ "GenMsgCycleTimeFast" BO_ 2566840192 200;
BA_ "GenMsgCycleTime" BO_ 2566840192 200;
BA_ "CI_MsgName" BO_ 2566840192 "EEC3_80 - Electronic Engine Controller 3";
BA_ "CI_MsgId" BO_ 2566840192 941;
BA_ "CI_MsgDefinition" BO_ 2566840192 "J1939DA";
BA_ "GenMsgStartDelayTime" BO_ 2566844160 29;
BA_ "GenMsgSendType" BO_ 2566844160 0;
BA_ "GenMsgDelayTime" BO_ 2566844160 250;
BA_ "GenMsgCycleTimeFast" BO_ 2566844160 500;
BA_ "GenMsgCycleTime" BO_ 2566844160 500;
BA_ "CI_MsgName" BO_ 2566844160 "EFLP1 - Engine Fluid Level/Pressure 1";
BA_ "CI_MsgId" BO_ 2566844160 1076;
BA_ "CI_MsgDefinition" BO_ 2566844160 "J1939DA";
BA_ "GenMsgStartDelayTime" BO_ 2566844193 92;
BA_ "GenMsgSendType" BO_ 2566844193 0;
BA_ "GenMsgDelayTime" BO_ 2566844193 250;
BA_ "GenMsgCycleTimeFast" BO_ 2566844193 500;
BA_ "GenMsgCycleTime" BO_ 2566844193 500;
BA_ "CI_MsgName" BO_ 2566844193 "EFLP1_21 - Engine Fluid Level/Pressure 1";
BA_ "CI_MsgId" BO_ 2566844193 1085;
BA_ "CI_MsgDefinition" BO_ 2566844193 "J1939DA";
BA_ "GenMsgStartDelayTime" BO_ 2566885210 8;
BA_ "GenMsgSendType" BO_ 2566885210 0;
BA_ "GenMsgDelayTime" BO_ 2566885210 25;
BA_ "GenMsgCycleTimeFast" BO_ 2566885210 50;
BA_ "GenMsgCycleTime" BO_ 2566885210 50;
BA_ "CI_MsgName" BO_ 2566885210 "ELFASys1_ELFA2 - ElfaSystem1 - DICO to VCU";
BA_ "CI_MsgId" BO_ 2566885210 1364;
BA_ "CI_MsgDefinition" BO_ 2566885210 "Iveco Proprietary";
BA_ "GenMsgStartDelayTime" BO_ 2566898290 10;
BA_ "GenMsgSendType" BO_ 2566898290 0;
BA_ "GenMsgDelayTime" BO_ 2566898290 50;
BA_ "GenMsgCycleTimeFast" BO_ 2566898290 50;
BA_ "GenMsgCycleTime" BO_ 2566898290 50;
BA_ "CI_MsgName" BO_ 2566898290 "EmCmd - Expansion Module Command";
BA_ "CI_MsgId" BO_ 2566898290 3928;
BA_ "CI_MsgDefinition" BO_ 2566898290 "Iveco SPR2 Proprietary";
BA_ "GenMsgStartDelayTime" BO_ 2565865488 4;
BA_ "GenMsgSendType" BO_ 2565865488 0;
BA_ "GenMsgDelayTime" BO_ 2565865488 10;
BA_ "GenMsgCycleTimeFast" BO_ 2565865488 20;
BA_ "GenMsgCycleTime" BO_ 2565865488 20;
BA_ "CI_MsgName" BO_ 2565865488 "ERC1_DR - Electronic Retarder Controller 1 - Driveline Retarder";
BA_ "CI_MsgId" BO_ 2565865488 407;
BA_ "CI_MsgDefinition" BO_ 2565865488 "J1939DA";
BA_ "GenMsgStartDelayTime" BO_ 2565865487 15;
BA_ "GenMsgSendType" BO_ 2565865487 0;
BA_ "GenMsgDelayTime" BO_ 2565865487 50;
BA_ "GenMsgCycleTimeFast" BO_ 2565865487 100;
BA_ "GenMsgCycleTime" BO_ 2565865487 100;
BA_ "CI_MsgName" BO_ 2565865487 "ERC1_ER - Electronic Retarder Controller 1 - Engine Retarder";
BA_ "CI_MsgId" BO_ 2565865487 14809;
BA_ "CI_MsgDefinition" BO_ 2565865487 "J1939DA";
BA_ "GenMsgStartDelayTime" BO_ 2566843904 42;
BA_ "GenMsgSendType" BO_ 2566843904 0;
BA_ "GenMsgDelayTime" BO_ 2566843904 500;
BA_ "GenMsgCycleTimeFast" BO_ 2566843904 1000;
BA_ "GenMsgCycleTime" BO_ 2566843904 1000;
BA_ "CI_MsgName" BO_ 2566843904 "ET1 - Engine Temperature 1";
BA_ "CI_MsgId" BO_ 2566843904 1069;
BA_ "CI_MsgDefinition" BO_ 2566843904 "J1939DA";
BA_ "GenSigTimeoutTime_SGW" SG_ 2561142090 WeightLateral 5000;
BA_ "GenSigStartValue" SG_ 2561142090 WeightLateral 1;
BA_ "CI_SigName" SG_ 2561142090 WeightLateral "WeightLateral";
BA_ "CI_SigId" SG_ 2561142090 WeightLateral 14411;
BA_ "CI_ParId" SG_ 2561142090 WeightLateral "IB1764";
BA_ "SigType" SG_ 2561142090 BenefitLateral 4;
BA_ "GenSigTimeoutTime_SGW" SG_ 2561142090 BenefitLateral 5000;
BA_ "CI_SigName" SG_ 2561142090 BenefitLateral "BenefitLateral";
BA_ "CI_SigId" SG_ 2561142090 BenefitLateral 14410;
BA_ "CI_ParId" SG_ 2561142090 BenefitLateral "IB1763";
BA_ "GenSigTimeoutTime_SGW" SG_ 2561142090 TrendLateral 5000;
BA_ "GenSigStartValue" SG_ 2561142090 TrendLateral 1;
BA_ "CI_SigName" SG_ 2561142090 TrendLateral "TrendLateral";
BA_ "CI_SigId" SG_ 2561142090 TrendLateral 14409;
BA_ "CI_ParId" SG_ 2561142090 TrendLateral "IB1762";
BA_ "SigType" SG_ 2561142090 ValidLateral 4;
BA_ "GenSigTimeoutTime_SGW" SG_ 2561142090 ValidLateral 5000;
BA_ "CI_SigName" SG_ 2561142090 ValidLateral "ValidLateral";
BA_ "CI_SigId" SG_ 2561142090 ValidLateral 14408;
BA_ "CI_ParId" SG_ 2561142090 ValidLateral "IB1761";
BA_ "GenSigTimeoutTime_SGW" SG_ 2561142090 ScoreLateral 5000;
BA_ "CI_SigName" SG_ 2561142090 ScoreLateral "ScoreLateral";
BA_ "CI_SigId" SG_ 2561142090 ScoreLateral 14407;
BA_ "CI_ParId" SG_ 2561142090 ScoreLateral "IB1760";
BA_ "SigType" SG_ 2561143114 EvaluatedMetersLateral 1;
BA_ "GenSigTimeoutTime_SGW" SG_ 2561143114 EvaluatedMetersLateral 5000;
BA_ "GenSigStartValue" SG_ 2561143114 EvaluatedMetersLateral 1;
BA_ "CI_SigName" SG_ 2561143114 EvaluatedMetersLateral "EvaluatedMetersLateral";
BA_ "CI_SigId" SG_ 2561143114 EvaluatedMetersLateral 14414;
BA_ "CI_ParId" SG_ 2561143114 EvaluatedMetersLateral "IB1766";
BA_ "SigType" SG_ 2561143114 NumEventsLateral 1;
BA_ "GenSigTimeoutTime_SGW" SG_ 2561143114 NumEventsLateral 5000;
BA_ "GenSigStartValue" SG_ 2561143114 NumEventsLateral 1;
BA_ "CI_SigName" SG_ 2561143114 NumEventsLateral "NumEventsLateral";
BA_ "CI_SigId" SG_ 2561143114 NumEventsLateral 14413;
BA_ "CI_ParId" SG_ 2561143114 NumEventsLateral "IB1765";
BA_ "GenSigTimeoutTime_SGW" SG_ 2561134666 WeightLaneDpt 5000;
BA_ "GenSigStartValue" SG_ 2561134666 WeightLaneDpt 1;
BA_ "CI_SigName" SG_ 2561134666 WeightLaneDpt "WeightLaneDpt";
BA_ "CI_SigId" SG_ 2561134666 WeightLaneDpt 14420;
BA_ "CI_ParId" SG_ 2561134666 WeightLaneDpt "IB1771";
BA_ "SigType" SG_ 2561134666 BenefitLaneDpt 4;
BA_ "GenSigTimeoutTime_SGW" SG_ 2561134666 BenefitLaneDpt 5000;
BA_ "CI_SigName" SG_ 2561134666 BenefitLaneDpt "BenefitLaneDpt";
BA_ "CI_SigId" SG_ 2561134666 BenefitLaneDpt 14419;
BA_ "CI_ParId" SG_ 2561134666 BenefitLaneDpt "IB1770";
BA_ "GenSigTimeoutTime_SGW" SG_ 2561134666 TrendLaneDpt 5000;
BA_ "GenSigStartValue" SG_ 2561134666 TrendLaneDpt 1;
BA_ "CI_SigName" SG_ 2561134666 TrendLaneDpt "TrendLaneDpt";
BA_ "CI_SigId" SG_ 2561134666 TrendLaneDpt 14418;
BA_ "CI_ParId" SG_ 2561134666 TrendLaneDpt "IB1769";
BA_ "SigType" SG_ 2561134666 ValidLaneDpt 4;
BA_ "GenSigTimeoutTime_SGW" SG_ 2561134666 ValidLaneDpt 5000;
BA_ "CI_SigName" SG_ 2561134666 ValidLaneDpt "ValidLaneDpt";
BA_ "CI_SigId" SG_ 2561134666 ValidLaneDpt 14417;
BA_ "CI_ParId" SG_ 2561134666 ValidLaneDpt "IB1768";
BA_ "GenSigTimeoutTime_SGW" SG_ 2561134666 ScoreLaneDpt 5000;
BA_ "GenSigStartValue" SG_ 2561134666 ScoreLaneDpt 1;
BA_ "CI_SigName" SG_ 2561134666 ScoreLaneDpt "ScoreLaneDpt";
BA_ "CI_SigId" SG_ 2561134666 ScoreLaneDpt 14416;
BA_ "CI_ParId" SG_ 2561134666 ScoreLaneDpt "IB1767";
BA_ "SigType" SG_ 2561134922 EventLaneDpt 4;
BA_ "GenSigTimeoutTime_SGW" SG_ 2561134922 EventLaneDpt 5000;
BA_ "CI_SigName" SG_ 2561134922 EventLaneDpt "EventLaneDpt";
BA_ "CI_SigId" SG_ 2561134922 EventLaneDpt 14423;
BA_ "CI_ParId" SG_ 2561134922 EventLaneDpt "IB1773";
BA_ "GenSigTimeoutTime_SGW" SG_ 2561134922 EvaluatedSamplesLaneDpt 5000;
BA_ "GenSigStartValue" SG_ 2561134922 EvaluatedSamplesLaneDpt 1;
BA_ "CI_SigName" SG_ 2561134922 EvaluatedSamplesLaneDpt "EvaluatedSamplesLaneDpt";
BA_ "CI_SigId" SG_ 2561134922 EvaluatedSamplesLaneDpt 14422;
BA_ "CI_ParId" SG_ 2561134922 EvaluatedSamplesLaneDpt "IB1772";
BA_ "GenSigTimeoutTime_SGW" SG_ 2561142346 WeightLongitudinal 5000;
BA_ "GenSigStartValue" SG_ 2561142346 WeightLongitudinal 1;
BA_ "CI_SigName" SG_ 2561142346 WeightLongitudinal "WeightLongitudinal";
BA_ "CI_SigId" SG_ 2561142346 WeightLongitudinal 14429;
BA_ "CI_ParId" SG_ 2561142346 WeightLongitudinal "IB1778";
BA_ "SigType" SG_ 2561142346 BenefitLongitudinal 4;
BA_ "GenSigTimeoutTime_SGW" SG_ 2561142346 BenefitLongitudinal 5000;
BA_ "CI_SigName" SG_ 2561142346 BenefitLongitudinal "BenefitLongitudinal";
BA_ "CI_SigId" SG_ 2561142346 BenefitLongitudinal 14428;
BA_ "CI_ParId" SG_ 2561142346 BenefitLongitudinal "IB1777";
BA_ "GenSigTimeoutTime_SGW" SG_ 2561142346 TrendLongitudinal 5000;
BA_ "GenSigStartValue" SG_ 2561142346 TrendLongitudinal 1;
BA_ "CI_SigName" SG_ 2561142346 TrendLongitudinal "TrendLongitudinal";
BA_ "CI_SigId" SG_ 2561142346 TrendLongitudinal 14427;
BA_ "CI_ParId" SG_ 2561142346 TrendLongitudinal "IB1776";
BA_ "SigType" SG_ 2561142346 ValidLongitudinal 4;
BA_ "GenSigTimeoutTime_SGW" SG_ 2561142346 ValidLongitudinal 5000;
BA_ "CI_SigName" SG_ 2561142346 ValidLongitudinal "ValidLongitudinal";
BA_ "CI_SigId" SG_ 2561142346 ValidLongitudinal 14426;
BA_ "CI_ParId" SG_ 2561142346 ValidLongitudinal "IB1775";
BA_ "GenSigTimeoutTime_SGW" SG_ 2561142346 ScoreLongitudinal 5000;
BA_ "CI_SigName" SG_ 2561142346 ScoreLongitudinal "ScoreLongitudinal";
BA_ "CI_SigId" SG_ 2561142346 ScoreLongitudinal 14425;
BA_ "CI_ParId" SG_ 2561142346 ScoreLongitudinal "IB1774";
BA_ "SigType" SG_ 2561143370 EvalMetersLongitud 1;
BA_ "GenSigTimeoutTime_SGW" SG_ 2561143370 EvalMetersLongitud 5000;
BA_ "GenSigStartValue" SG_ 2561143370 EvalMetersLongitud 1;
BA_ "CI_SigName" SG_ 2561143370 EvalMetersLongitud "EvaluatedMetersLongitudinal";
BA_ "CI_SigId" SG_ 2561143370 EvalMetersLongitud 14432;
BA_ "CI_ParId" SG_ 2561143370 EvalMetersLongitud "IB1780";
BA_ "SigType" SG_ 2561143370 NumEventsLongitudinal 1;
BA_ "GenSigTimeoutTime_SGW" SG_ 2561143370 NumEventsLongitudinal 5000;
BA_ "GenSigStartValue" SG_ 2561143370 NumEventsLongitudinal 1;
BA_ "CI_SigName" SG_ 2561143370 NumEventsLongitudinal "NumEventsLongitudinal";
BA_ "CI_SigId" SG_ 2561143370 NumEventsLongitudinal 14431;
BA_ "CI_ParId" SG_ 2561143370 NumEventsLongitudinal "IB1779";
BA_ "GenSigTimeoutTime_SGW" SG_ 2561146186 WeightMois 5000;
BA_ "GenSigStartValue" SG_ 2561146186 WeightMois 1;
BA_ "CI_SigName" SG_ 2561146186 WeightMois "WeightMois";
BA_ "CI_SigId" SG_ 2561146186 WeightMois 14516;
BA_ "CI_ParId" SG_ 2561146186 WeightMois "IB1785";
BA_ "SigType" SG_ 2561146186 BenefitMois 4;
BA_ "GenSigTimeoutTime_SGW" SG_ 2561146186 BenefitMois 5000;
BA_ "CI_SigName" SG_ 2561146186 BenefitMois "BenefitMois";
BA_ "CI_SigId" SG_ 2561146186 BenefitMois 14515;
BA_ "CI_ParId" SG_ 2561146186 BenefitMois "IB1784";
BA_ "GenSigTimeoutTime_SGW" SG_ 2561146186 TrendMois 5000;
BA_ "GenSigStartValue" SG_ 2561146186 TrendMois 1;
BA_ "CI_SigName" SG_ 2561146186 TrendMois "TrendMois";
BA_ "CI_SigId" SG_ 2561146186 TrendMois 14514;
BA_ "CI_ParId" SG_ 2561146186 TrendMois "IB1783";
BA_ "SigType" SG_ 2561146186 ValidMois 4;
BA_ "GenSigTimeoutTime_SGW" SG_ 2561146186 ValidMois 5000;
BA_ "CI_SigName" SG_ 2561146186 ValidMois "ValidMois";
BA_ "CI_SigId" SG_ 2561146186 ValidMois 14513;
BA_ "CI_ParId" SG_ 2561146186 ValidMois "IB1782";
BA_ "GenSigTimeoutTime_SGW" SG_ 2561146186 ScoreMois 5000;
BA_ "GenSigStartValue" SG_ 2561146186 ScoreMois 1;
BA_ "CI_SigName" SG_ 2561146186 ScoreMois "ScoreMois";
BA_ "CI_SigId" SG_ 2561146186 ScoreMois 14512;
BA_ "CI_ParId" SG_ 2561146186 ScoreMois "IB1781";
BA_ "GenSigTimeoutTime_SGW" SG_ 2561135178 NotificationEnabled 5000;
BA_ "CI_SigName" SG_ 2561135178 NotificationEnabled "NotificationEnabled";
BA_ "CI_SigId" SG_ 2561135178 NotificationEnabled 14521;
BA_ "CI_ParId" SG_ 2561135178 NotificationEnabled "IB1789";
BA_ "GenSigTimeoutTime_SGW" SG_ 2561135178 NotificationCritical 5000;
BA_ "CI_SigName" SG_ 2561135178 NotificationCritical "NotificationCritical";
BA_ "CI_SigId" SG_ 2561135178 NotificationCritical 14520;
BA_ "CI_ParId" SG_ 2561135178 NotificationCritical "IB1788";
BA_ "GenSigTimeoutTime_SGW" SG_ 2561135178 NotificationTypeId 5000;
BA_ "CI_SigName" SG_ 2561135178 NotificationTypeId "NotificationTypeId";
BA_ "CI_SigId" SG_ 2561135178 NotificationTypeId 14519;
BA_ "CI_ParId" SG_ 2561135178 NotificationTypeId "IB1787";
BA_ "GenSigTimeoutTime_SGW" SG_ 2561135178 NotificationTextId 5000;
BA_ "CI_SigName" SG_ 2561135178 NotificationTextId "NotificationTextId";
BA_ "CI_SigId" SG_ 2561135178 NotificationTextId 14518;
BA_ "CI_ParId" SG_ 2561135178 NotificationTextId "IB1786";
BA_ "GenSigTimeoutTime_SGW" SG_ 2561141322 IndexDegreeOfDificulty 5000;
BA_ "GenSigStartValue" SG_ 2561141322 IndexDegreeOfDificulty 1;
BA_ "CI_SigName" SG_ 2561141322 IndexDegreeOfDificulty "IndexDegreeOfDificulty";
BA_ "CI_SigId" SG_ 2561141322 IndexDegreeOfDificulty 14529;
BA_ "CI_ParId" SG_ 2561141322 IndexDegreeOfDificulty "IB1931";
BA_ "GenSigTimeoutTime_SGW" SG_ 2561141322 IndexMissionSeverity 5000;
BA_ "GenSigStartValue" SG_ 2561141322 IndexMissionSeverity 1;
BA_ "CI_SigName" SG_ 2561141322 IndexMissionSeverity "IndexMissionSeverity";
BA_ "CI_SigId" SG_ 2561141322 IndexMissionSeverity 14528;
BA_ "CI_ParId" SG_ 2561141322 IndexMissionSeverity "IB1930";
BA_ "GenSigTimeoutTime_SGW" SG_ 2561141322 IndexAtmosphericCond 5000;
BA_ "GenSigStartValue" SG_ 2561141322 IndexAtmosphericCond 1;
BA_ "CI_SigName" SG_ 2561141322 IndexAtmosphericCond "IndexAtmosphericConditions";
BA_ "CI_SigId" SG_ 2561141322 IndexAtmosphericCond 14527;
BA_ "CI_ParId" SG_ 2561141322 IndexAtmosphericCond "IB1929";
BA_ "GenSigTimeoutTime_SGW" SG_ 2561141322 IndexTortuosity 5000;
BA_ "GenSigStartValue" SG_ 2561141322 IndexTortuosity 1;
BA_ "CI_SigName" SG_ 2561141322 IndexTortuosity "IndexTortuosity";
BA_ "CI_SigId" SG_ 2561141322 IndexTortuosity 14526;
BA_ "CI_ParId" SG_ 2561141322 IndexTortuosity "IB1928";
BA_ "GenSigTimeoutTime_SGW" SG_ 2561141322 IndexSpeedProfile 5000;
BA_ "GenSigStartValue" SG_ 2561141322 IndexSpeedProfile 1;
BA_ "CI_SigName" SG_ 2561141322 IndexSpeedProfile "IndexSpeedProfile";
BA_ "CI_SigId" SG_ 2561141322 IndexSpeedProfile 14525;
BA_ "CI_ParId" SG_ 2561141322 IndexSpeedProfile "IB1927";
BA_ "GenSigTimeoutTime_SGW" SG_ 2561141322 IndexAltimetry 5000;
BA_ "GenSigStartValue" SG_ 2561141322 IndexAltimetry 1;
BA_ "CI_SigName" SG_ 2561141322 IndexAltimetry "IndexAltimetry";
BA_ "CI_SigId" SG_ 2561141322 IndexAltimetry 14524;
BA_ "CI_ParId" SG_ 2561141322 IndexAltimetry "IB1926";
BA_ "GenSigTimeoutTime_SGW" SG_ 2561141322 IndexVehicleLoad 5000;
BA_ "GenSigStartValue" SG_ 2561141322 IndexVehicleLoad 1;
BA_ "CI_SigName" SG_ 2561141322 IndexVehicleLoad "IndexVehicleLoad";
BA_ "CI_SigId" SG_ 2561141322 IndexVehicleLoad 14523;
BA_ "CI_ParId" SG_ 2561141322 IndexVehicleLoad "IB1925";
BA_ "SigType" SG_ 2561141578 OverrevvingSeconds 1;
BA_ "GenSigTimeoutTime_SGW" SG_ 2561141578 OverrevvingSeconds 5000;
BA_ "GenSigStartValue" SG_ 2561141578 OverrevvingSeconds 1;
BA_ "CI_SigName" SG_ 2561141578 OverrevvingSeconds "OverrevvingSeconds";
BA_ "CI_SigId" SG_ 2561141578 OverrevvingSeconds 14537;
BA_ "CI_ParId" SG_ 2561141578 OverrevvingSeconds "IB1796";
BA_ "GenSigTimeoutTime_SGW" SG_ 2561141578 SlopeFlatPerc 5000;
BA_ "GenSigStartValue" SG_ 2561141578 SlopeFlatPerc 1;
BA_ "CI_SigName" SG_ 2561141578 SlopeFlatPerc "SlopeFlatPerc";
BA_ "CI_SigId" SG_ 2561141578 SlopeFlatPerc 14536;
BA_ "CI_ParId" SG_ 2561141578 SlopeFlatPerc "IB1795";
BA_ "GenSigTimeoutTime_SGW" SG_ 2561141578 SlopeDownhillPerc 5000;
BA_ "GenSigStartValue" SG_ 2561141578 SlopeDownhillPerc 1;
BA_ "CI_SigName" SG_ 2561141578 SlopeDownhillPerc "SlopeDownhillPerc";
BA_ "CI_SigId" SG_ 2561141578 SlopeDownhillPerc 14535;
BA_ "CI_ParId" SG_ 2561141578 SlopeDownhillPerc "IB1794";
BA_ "GenSigTimeoutTime_SGW" SG_ 2561141578 SlopeSoftDownhillPerc 5000;
BA_ "GenSigStartValue" SG_ 2561141578 SlopeSoftDownhillPerc 1;
BA_ "CI_SigName" SG_ 2561141578 SlopeSoftDownhillPerc "SlopeSoftDownhillPerc";
BA_ "CI_SigId" SG_ 2561141578 SlopeSoftDownhillPerc 14534;
BA_ "CI_ParId" SG_ 2561141578 SlopeSoftDownhillPerc "IB1793";
BA_ "GenSigTimeoutTime_SGW" SG_ 2561141578 SlopeUphillPerc 5000;
BA_ "GenSigStartValue" SG_ 2561141578 SlopeUphillPerc 1;
BA_ "CI_SigName" SG_ 2561141578 SlopeUphillPerc "SlopeUphillPerc";
BA_ "CI_SigId" SG_ 2561141578 SlopeUphillPerc 14533;
BA_ "CI_ParId" SG_ 2561141578 SlopeUphillPerc "IB1792";
BA_ "GenSigTimeoutTime_SGW" SG_ 2561141578 SlopeSoftUphillPerc 5000;
BA_ "GenSigStartValue" SG_ 2561141578 SlopeSoftUphillPerc 1;
BA_ "CI_SigName" SG_ 2561141578 SlopeSoftUphillPerc "SlopeSoftUphillPerc";
BA_ "CI_SigId" SG_ 2561141578 SlopeSoftUphillPerc 14532;
BA_ "CI_ParId" SG_ 2561141578 SlopeSoftUphillPerc "IB1791";
BA_ "GenSigTimeoutTime_SGW" SG_ 2561141578 EstimVehWeight 5000;
BA_ "CI_SigName" SG_ 2561141578 EstimVehWeight "EstimatedVehicleWeight";
BA_ "CI_SigId" SG_ 2561141578 EstimVehWeight 14531;
BA_ "CI_ParId" SG_ 2561141578 EstimVehWeight "IB1790";
BA_ "SigType" SG_ 2561135434 OldDasEnabled 4;
BA_ "GenSigTimeoutTime_SGW" SG_ 2561135434 OldDasEnabled 5000;
BA_ "CI_SigName" SG_ 2561135434 OldDasEnabled "OldDasEnabled";
BA_ "CI_SigId" SG_ 2561135434 OldDasEnabled 14543;
BA_ "CI_ParId" SG_ 2561135434 OldDasEnabled "IB1801";
BA_ "SigType" SG_ 2561135434 OldDasWarning 4;
BA_ "GenSigTimeoutTime_SGW" SG_ 2561135434 OldDasWarning 5000;
BA_ "CI_SigName" SG_ 2561135434 OldDasWarning "OldDasWarning";
BA_ "CI_SigId" SG_ 2561135434 OldDasWarning 14542;
BA_ "CI_ParId" SG_ 2561135434 OldDasWarning "IB1800";
BA_ "SigType" SG_ 2561135434 OldDasStop 4;
BA_ "GenSigTimeoutTime_SGW" SG_ 2561135434 OldDasStop 5000;
BA_ "CI_SigName" SG_ 2561135434 OldDasStop "OldDasStop";
BA_ "CI_SigId" SG_ 2561135434 OldDasStop 14541;
BA_ "CI_ParId" SG_ 2561135434 OldDasStop "IB1799";
BA_ "GenSigTimeoutTime_SGW" SG_ 2561135434 OldDasStatus 5000;
BA_ "CI_SigName" SG_ 2561135434 OldDasStatus "OldDasStatus";
BA_ "CI_SigId" SG_ 2561135434 OldDasStatus 14540;
BA_ "CI_ParId" SG_ 2561135434 OldDasStatus "IB1798";
BA_ "GenSigTimeoutTime_SGW" SG_ 2561135434 OldDasPiswa 5000;
BA_ "CI_SigName" SG_ 2561135434 OldDasPiswa "OldDasPiswa";
BA_ "CI_SigId" SG_ 2561135434 OldDasPiswa 14539;
BA_ "CI_ParId" SG_ 2561135434 OldDasPiswa "IB1797";
BA_ "GenSigTimeoutTime_SGW" SG_ 2561142858 AccelerometerAxis3 5000;
BA_ "GenSigStartValue" SG_ 2561142858 AccelerometerAxis3 256;
BA_ "CI_SigName" SG_ 2561142858 AccelerometerAxis3 "AccelerometerAxis3";
BA_ "CI_SigId" SG_ 2561142858 AccelerometerAxis3 14547;
BA_ "CI_ParId" SG_ 2561142858 AccelerometerAxis3 "IB1804";
BA_ "GenSigTimeoutTime_SGW" SG_ 2561142858 AccelerometerAxis2 5000;
BA_ "GenSigStartValue" SG_ 2561142858 AccelerometerAxis2 256;
BA_ "CI_SigName" SG_ 2561142858 AccelerometerAxis2 "AccelerometerAxis2";
BA_ "CI_SigId" SG_ 2561142858 AccelerometerAxis2 14546;
BA_ "CI_ParId" SG_ 2561142858 AccelerometerAxis2 "IB1803";
BA_ "GenSigTimeoutTime_SGW" SG_ 2561142858 AccelerometerAxis1 5000;
BA_ "GenSigStartValue" SG_ 2561142858 AccelerometerAxis1 256;
BA_ "CI_SigName" SG_ 2561142858 AccelerometerAxis1 "AccelerometerAxis1";
BA_ "CI_SigId" SG_ 2561142858 AccelerometerAxis1 14545;
BA_ "CI_ParId" SG_ 2561142858 AccelerometerAxis1 "IB1802";
BA_ "GenSigTimeoutTime_SGW" SG_ 2561135690 WeightPecc 5000;
BA_ "GenSigStartValue" SG_ 2561135690 WeightPecc 1;
BA_ "CI_SigName" SG_ 2561135690 WeightPecc "WeightPecc";
BA_ "CI_SigId" SG_ 2561135690 WeightPecc 14553;
BA_ "CI_ParId" SG_ 2561135690 WeightPecc "IB1809";
BA_ "SigType" SG_ 2561135690 BenefitPecc 4;
BA_ "GenSigTimeoutTime_SGW" SG_ 2561135690 BenefitPecc 5000;
BA_ "CI_SigName" SG_ 2561135690 BenefitPecc "BenefitPecc";
BA_ "CI_SigId" SG_ 2561135690 BenefitPecc 14552;
BA_ "CI_ParId" SG_ 2561135690 BenefitPecc "IB1808";
BA_ "GenSigTimeoutTime_SGW" SG_ 2561135690 TrendPecc 5000;
BA_ "GenSigStartValue" SG_ 2561135690 TrendPecc 1;
BA_ "CI_SigName" SG_ 2561135690 TrendPecc "TrendPecc";
BA_ "CI_SigId" SG_ 2561135690 TrendPecc 14551;
BA_ "CI_ParId" SG_ 2561135690 TrendPecc "IB1807";
BA_ "SigType" SG_ 2561135690 ValidPecc 4;
BA_ "GenSigTimeoutTime_SGW" SG_ 2561135690 ValidPecc 5000;
BA_ "CI_SigName" SG_ 2561135690 ValidPecc "ValidPecc";
BA_ "CI_SigId" SG_ 2561135690 ValidPecc 14550;
BA_ "CI_ParId" SG_ 2561135690 ValidPecc "IB1806";
BA_ "GenSigTimeoutTime_SGW" SG_ 2561135690 ScorePecc 5000;
BA_ "GenSigStartValue" SG_ 2561135690 ScorePecc 1;
BA_ "CI_SigName" SG_ 2561135690 ScorePecc "ScorePecc";
BA_ "CI_SigId" SG_ 2561135690 ScorePecc 14549;
BA_ "CI_ParId" SG_ 2561135690 ScorePecc "IB1805";
BA_ "SigType" SG_ 2561135946 EventPecc 4;
BA_ "GenSigTimeoutTime_SGW" SG_ 2561135946 EventPecc 5000;
BA_ "CI_SigName" SG_ 2561135946 EventPecc "EventPecc";
BA_ "CI_SigId" SG_ 2561135946 EventPecc 14556;
BA_ "CI_ParId" SG_ 2561135946 EventPecc "IB1811";
BA_ "GenSigTimeoutTime_SGW" SG_ 2561135946 EvalSamplesPecc 5000;
BA_ "GenSigStartValue" SG_ 2561135946 EvalSamplesPecc 1;
BA_ "CI_SigName" SG_ 2561135946 EvalSamplesPecc "EvaluatedSamplesPecc";
BA_ "CI_SigId" SG_ 2561135946 EvalSamplesPecc 14555;
BA_ "CI_ParId" SG_ 2561135946 EvalSamplesPecc "IB1810";
BA_ "GenSigTimeoutTime_SGW" SG_ 2561136202 WeightRadar 5000;
BA_ "GenSigStartValue" SG_ 2561136202 WeightRadar 1;
BA_ "CI_SigName" SG_ 2561136202 WeightRadar "WeightRadar";
BA_ "CI_SigId" SG_ 2561136202 WeightRadar 14562;
BA_ "CI_ParId" SG_ 2561136202 WeightRadar "IB1816";
BA_ "SigType" SG_ 2561136202 BenefitRadar 4;
BA_ "GenSigTimeoutTime_SGW" SG_ 2561136202 BenefitRadar 5000;
BA_ "CI_SigName" SG_ 2561136202 BenefitRadar "BenefitRadar";
BA_ "CI_SigId" SG_ 2561136202 BenefitRadar 14561;
BA_ "CI_ParId" SG_ 2561136202 BenefitRadar "IB1815";
BA_ "GenSigTimeoutTime_SGW" SG_ 2561136202 TrendRadar 5000;
BA_ "GenSigStartValue" SG_ 2561136202 TrendRadar 1;
BA_ "CI_SigName" SG_ 2561136202 TrendRadar "TrendRadar";
BA_ "CI_SigId" SG_ 2561136202 TrendRadar 14560;
BA_ "CI_ParId" SG_ 2561136202 TrendRadar "IB1814";
BA_ "SigType" SG_ 2561136202 ValidRadar 4;
BA_ "GenSigTimeoutTime_SGW" SG_ 2561136202 ValidRadar 5000;
BA_ "CI_SigName" SG_ 2561136202 ValidRadar "ValidRadar";
BA_ "CI_SigId" SG_ 2561136202 ValidRadar 14559;
BA_ "CI_ParId" SG_ 2561136202 ValidRadar "IB1813";
BA_ "GenSigTimeoutTime_SGW" SG_ 2561136202 ScoreRadar 5000;
BA_ "GenSigStartValue" SG_ 2561136202 ScoreRadar 1;
BA_ "CI_SigName" SG_ 2561136202 ScoreRadar "ScoreRadar";
BA_ "CI_SigId" SG_ 2561136202 ScoreRadar 14558;
BA_ "CI_ParId" SG_ 2561136202 ScoreRadar "IB1812";
BA_ "SigType" SG_ 2561136458 EventRadar 4;
BA_ "GenSigTimeoutTime_SGW" SG_ 2561136458 EventRadar 5000;
BA_ "CI_SigName" SG_ 2561136458 EventRadar "EventRadar";
BA_ "CI_SigId" SG_ 2561136458 EventRadar 14565;
BA_ "CI_ParId" SG_ 2561136458 EventRadar "IB1818";
BA_ "GenSigTimeoutTime_SGW" SG_ 2561136458 EvalSamplesRadar 5000;
BA_ "GenSigStartValue" SG_ 2561136458 EvalSamplesRadar 1;
BA_ "CI_SigName" SG_ 2561136458 EvalSamplesRadar "EvaluatedSamplesRadar";
BA_ "CI_SigId" SG_ 2561136458 EvalSamplesRadar 14564;
BA_ "CI_ParId" SG_ 2561136458 EvalSamplesRadar "IB1817";
BA_ "GenSigTimeoutTime_SGW" SG_ 2561136714 WeightRpm 5000;
BA_ "GenSigStartValue" SG_ 2561136714 WeightRpm 1;
BA_ "CI_SigName" SG_ 2561136714 WeightRpm "WeightRpm";
BA_ "CI_SigId" SG_ 2561136714 WeightRpm 14571;
BA_ "CI_ParId" SG_ 2561136714 WeightRpm "IB1823";
BA_ "SigType" SG_ 2561136714 BenefitRpm 4;
BA_ "GenSigTimeoutTime_SGW" SG_ 2561136714 BenefitRpm 5000;
BA_ "CI_SigName" SG_ 2561136714 BenefitRpm "BenefitRpm";
BA_ "CI_SigId" SG_ 2561136714 BenefitRpm 14570;
BA_ "CI_ParId" SG_ 2561136714 BenefitRpm "IB1822";
BA_ "GenSigTimeoutTime_SGW" SG_ 2561136714 TrendRpm 5000;
BA_ "GenSigStartValue" SG_ 2561136714 TrendRpm 1;
BA_ "CI_SigName" SG_ 2561136714 TrendRpm "TrendRpm";
BA_ "CI_SigId" SG_ 2561136714 TrendRpm 14569;
BA_ "CI_ParId" SG_ 2561136714 TrendRpm "IB1821";
BA_ "SigType" SG_ 2561136714 ValidRpm 4;
BA_ "GenSigTimeoutTime_SGW" SG_ 2561136714 ValidRpm 5000;
BA_ "CI_SigName" SG_ 2561136714 ValidRpm "ValidRpm";
BA_ "CI_SigId" SG_ 2561136714 ValidRpm 14568;
BA_ "CI_ParId" SG_ 2561136714 ValidRpm "IB1820";
BA_ "GenSigTimeoutTime_SGW" SG_ 2561136714 ScoreRpm 5000;
BA_ "GenSigStartValue" SG_ 2561136714 ScoreRpm 1;
BA_ "CI_SigName" SG_ 2561136714 ScoreRpm "ScoreRpm";
BA_ "CI_SigId" SG_ 2561136714 ScoreRpm 14567;
BA_ "CI_ParId" SG_ 2561136714 ScoreRpm "IB1819";
BA_ "GenSigTimeoutTime_SGW" SG_ 2561136970 MidRPMBonus 5000;
BA_ "GenSigStartValue" SG_ 2561136970 MidRPMBonus 1;
BA_ "CI_SigName" SG_ 2561136970 MidRPMBonus "MidRPMBonus";
BA_ "CI_SigId" SG_ 2561136970 MidRPMBonus 14582;
BA_ "CI_ParId" SG_ 2561136970 MidRPMBonus "IB1833";
BA_ "GenSigTimeoutTime_SGW" SG_ 2561136970 LowRPMMalus 5000;
BA_ "GenSigStartValue" SG_ 2561136970 LowRPMMalus 126;
BA_ "CI_SigName" SG_ 2561136970 LowRPMMalus "LowRPMMalus";
BA_ "CI_SigId" SG_ 2561136970 LowRPMMalus 14581;
BA_ "CI_ParId" SG_ 2561136970 LowRPMMalus "IB1832";
BA_ "GenSigTimeoutTime_SGW" SG_ 2561136970 HighRPMMalus 5000;
BA_ "GenSigStartValue" SG_ 2561136970 HighRPMMalus 126;
BA_ "CI_SigName" SG_ 2561136970 HighRPMMalus "HighRPMMalus";
BA_ "CI_SigId" SG_ 2561136970 HighRPMMalus 14580;
BA_ "CI_ParId" SG_ 2561136970 HighRPMMalus "IB1831";
BA_ "SigType" SG_ 2561136970 LowRPMLimit 1;
BA_ "GenSigTimeoutTime_SGW" SG_ 2561136970 LowRPMLimit 5000;
BA_ "CI_SigName" SG_ 2561136970 LowRPMLimit "LowRPMLimit";
BA_ "CI_SigId" SG_ 2561136970 LowRPMLimit 14579;
BA_ "CI_ParId" SG_ 2561136970 LowRPMLimit "IB1830";
BA_ "SigType" SG_ 2561136970 HighRPMLimit 1;
BA_ "GenSigTimeoutTime_SGW" SG_ 2561136970 HighRPMLimit 5000;
BA_ "CI_SigName" SG_ 2561136970 HighRPMLimit "HighRPMLimit";
BA_ "CI_SigId" SG_ 2561136970 HighRPMLimit 14578;
BA_ "CI_ParId" SG_ 2561136970 HighRPMLimit "IB1829";
BA_ "SigType" SG_ 2561136970 TorqueLevel 4;
BA_ "GenSigTimeoutTime_SGW" SG_ 2561136970 TorqueLevel 5000;
BA_ "CI_SigName" SG_ 2561136970 TorqueLevel "TorqueLevel";
BA_ "CI_SigId" SG_ 2561136970 TorqueLevel 14577;
BA_ "CI_ParId" SG_ 2561136970 TorqueLevel "IB1828";
BA_ "SigType" SG_ 2561136970 RPMZone 4;
BA_ "GenSigTimeoutTime_SGW" SG_ 2561136970 RPMZone 5000;
BA_ "CI_SigName" SG_ 2561136970 RPMZone "RPMZone";
BA_ "CI_SigId" SG_ 2561136970 RPMZone 14576;
BA_ "CI_ParId" SG_ 2561136970 RPMZone "IB1827";
BA_ "SigType" SG_ 2561136970 RPMLevel 4;
BA_ "GenSigTimeoutTime_SGW" SG_ 2561136970 RPMLevel 5000;
BA_ "CI_SigName" SG_ 2561136970 RPMLevel "RPMLevel";
BA_ "CI_SigId" SG_ 2561136970 RPMLevel 14575;
BA_ "CI_ParId" SG_ 2561136970 RPMLevel "IB1826";
BA_ "GenSigTimeoutTime_SGW" SG_ 2561136970 EventRPM 5000;
BA_ "CI_SigName" SG_ 2561136970 EventRPM "EventRPM";
BA_ "CI_SigId" SG_ 2561136970 EventRPM 14574;
BA_ "CI_ParId" SG_ 2561136970 EventRPM "IB1825";
BA_ "GenSigTimeoutTime_SGW" SG_ 2561136970 EvalSamplesRpm 5000;
BA_ "GenSigStartValue" SG_ 2561136970 EvalSamplesRpm 1;
BA_ "CI_SigName" SG_ 2561136970 EvalSamplesRpm "EvaluatedSamplesRpm";
BA_ "CI_SigId" SG_ 2561136970 EvalSamplesRpm 14573;
BA_ "CI_ParId" SG_ 2561136970 EvalSamplesRpm "IB1824";
BA_ "GenSigTimeoutTime_SGW" SG_ 2561145162 WeightSafeDistance 5000;
BA_ "GenSigStartValue" SG_ 2561145162 WeightSafeDistance 1;
BA_ "CI_SigName" SG_ 2561145162 WeightSafeDistance "WeightSafeDistance";
BA_ "CI_SigId" SG_ 2561145162 WeightSafeDistance 14588;
BA_ "CI_ParId" SG_ 2561145162 WeightSafeDistance "IB1838";
BA_ "SigType" SG_ 2561145162 BenefitSafeDistance 4;
BA_ "GenSigTimeoutTime_SGW" SG_ 2561145162 BenefitSafeDistance 5000;
BA_ "CI_SigName" SG_ 2561145162 BenefitSafeDistance "BenefitSafeDistance";
BA_ "CI_SigId" SG_ 2561145162 BenefitSafeDistance 14587;
BA_ "CI_ParId" SG_ 2561145162 BenefitSafeDistance "IB1837";
BA_ "GenSigTimeoutTime_SGW" SG_ 2561145162 TrendSafeDistance 5000;
BA_ "GenSigStartValue" SG_ 2561145162 TrendSafeDistance 1;
BA_ "CI_SigName" SG_ 2561145162 TrendSafeDistance "TrendSafeDistance";
BA_ "CI_SigId" SG_ 2561145162 TrendSafeDistance 14586;
BA_ "CI_ParId" SG_ 2561145162 TrendSafeDistance "IB1836";
BA_ "SigType" SG_ 2561145162 ValidSafeDistance 4;
BA_ "GenSigTimeoutTime_SGW" SG_ 2561145162 ValidSafeDistance 5000;
BA_ "CI_SigName" SG_ 2561145162 ValidSafeDistance "ValidSafeDistance";
BA_ "CI_SigId" SG_ 2561145162 ValidSafeDistance 14585;
BA_ "CI_ParId" SG_ 2561145162 ValidSafeDistance "IB1835";
BA_ "GenSigTimeoutTime_SGW" SG_ 2561145162 ScoreSafeDistance 5000;
BA_ "GenSigStartValue" SG_ 2561145162 ScoreSafeDistance 1;
BA_ "CI_SigName" SG_ 2561145162 ScoreSafeDistance "ScoreSafeDistance";
BA_ "CI_SigId" SG_ 2561145162 ScoreSafeDistance 14584;
BA_ "CI_ParId" SG_ 2561145162 ScoreSafeDistance "IB1834";
BA_ "GenSigTimeoutTime_SGW" SG_ 2561145418 WeightSafePosition 5000;
BA_ "GenSigStartValue" SG_ 2561145418 WeightSafePosition 1;
BA_ "CI_SigName" SG_ 2561145418 WeightSafePosition "WeightSafePosition";
BA_ "CI_SigId" SG_ 2561145418 WeightSafePosition 14594;
BA_ "CI_ParId" SG_ 2561145418 WeightSafePosition "IB1843";
BA_ "SigType" SG_ 2561145418 BenefitSafePosition 4;
BA_ "GenSigTimeoutTime_SGW" SG_ 2561145418 BenefitSafePosition 5000;
BA_ "CI_SigName" SG_ 2561145418 BenefitSafePosition "BenefitSafePosition";
BA_ "CI_SigId" SG_ 2561145418 BenefitSafePosition 14593;
BA_ "CI_ParId" SG_ 2561145418 BenefitSafePosition "IB1842";
BA_ "GenSigTimeoutTime_SGW" SG_ 2561145418 TrendSafePosition 5000;
BA_ "GenSigStartValue" SG_ 2561145418 TrendSafePosition 1;
BA_ "CI_SigName" SG_ 2561145418 TrendSafePosition "TrendSafePosition";
BA_ "CI_SigId" SG_ 2561145418 TrendSafePosition 14592;
BA_ "CI_ParId" SG_ 2561145418 TrendSafePosition "IB1841";
BA_ "SigType" SG_ 2561145418 ValidSafePosition 4;
BA_ "GenSigTimeoutTime_SGW" SG_ 2561145418 ValidSafePosition 5000;
BA_ "CI_SigName" SG_ 2561145418 ValidSafePosition "ValidSafePosition";
BA_ "CI_SigId" SG_ 2561145418 ValidSafePosition 14591;
BA_ "CI_ParId" SG_ 2561145418 ValidSafePosition "IB1840";
BA_ "GenSigTimeoutTime_SGW" SG_ 2561145418 ScoreSafePosition 5000;
BA_ "GenSigStartValue" SG_ 2561145418 ScoreSafePosition 1;
BA_ "CI_SigName" SG_ 2561145418 ScoreSafePosition "ScoreSafePosition";
BA_ "CI_SigId" SG_ 2561145418 ScoreSafePosition 14590;
BA_ "CI_ParId" SG_ 2561145418 ScoreSafePosition "IB1839";
BA_ "GenSigTimeoutTime_SGW" SG_ 2561137226 WeightSafety 5000;
BA_ "GenSigStartValue" SG_ 2561137226 WeightSafety 1;
BA_ "CI_SigName" SG_ 2561137226 WeightSafety "WeightSafety";
BA_ "CI_SigId" SG_ 2561137226 WeightSafety 14600;
BA_ "CI_ParId" SG_ 2561137226 WeightSafety "IB1848";
BA_ "SigType" SG_ 2561137226 BenefitSafety 4;
BA_ "GenSigTimeoutTime_SGW" SG_ 2561137226 BenefitSafety 5000;
BA_ "CI_SigName" SG_ 2561137226 BenefitSafety "BenefitSafety";
BA_ "CI_SigId" SG_ 2561137226 BenefitSafety 14599;
BA_ "CI_ParId" SG_ 2561137226 BenefitSafety "IB1847";
BA_ "GenSigTimeoutTime_SGW" SG_ 2561137226 TrendSafety 5000;
BA_ "GenSigStartValue" SG_ 2561137226 TrendSafety 1;
BA_ "CI_SigName" SG_ 2561137226 TrendSafety "TrendSafety";
BA_ "CI_SigId" SG_ 2561137226 TrendSafety 14598;
BA_ "CI_ParId" SG_ 2561137226 TrendSafety "IB1846";
BA_ "SigType" SG_ 2561137226 ValidSafety 4;
BA_ "GenSigTimeoutTime_SGW" SG_ 2561137226 ValidSafety 5000;
BA_ "CI_SigName" SG_ 2561137226 ValidSafety "ValidSafety";
BA_ "CI_SigId" SG_ 2561137226 ValidSafety 14597;
BA_ "CI_ParId" SG_ 2561137226 ValidSafety "IB1845";
BA_ "GenSigTimeoutTime_SGW" SG_ 2561137226 ScoreSafety 5000;
BA_ "GenSigStartValue" SG_ 2561137226 ScoreSafety 1;
BA_ "CI_SigName" SG_ 2561137226 ScoreSafety "ScoreSafety";
BA_ "CI_SigId" SG_ 2561137226 ScoreSafety 14596;
BA_ "CI_ParId" SG_ 2561137226 ScoreSafety "IB1844";
BA_ "GenSigTimeoutTime_SGW" SG_ 2561137482 WeightTireSafety 5000;
BA_ "GenSigStartValue" SG_ 2561137482 WeightTireSafety 1;
BA_ "CI_SigName" SG_ 2561137482 WeightTireSafety "WeightTireSafety";
BA_ "CI_SigId" SG_ 2561137482 WeightTireSafety 14606;
BA_ "CI_ParId" SG_ 2561137482 WeightTireSafety "IB1853";
BA_ "SigType" SG_ 2561137482 BenefitTireSafety 4;
BA_ "GenSigTimeoutTime_SGW" SG_ 2561137482 BenefitTireSafety 5000;
BA_ "CI_SigName" SG_ 2561137482 BenefitTireSafety "BenefitTireSafety";
BA_ "CI_SigId" SG_ 2561137482 BenefitTireSafety 14605;
BA_ "CI_ParId" SG_ 2561137482 BenefitTireSafety "IB1852";
BA_ "GenSigTimeoutTime_SGW" SG_ 2561137482 TrendTireSafety 5000;
BA_ "GenSigStartValue" SG_ 2561137482 TrendTireSafety 1;
BA_ "CI_SigName" SG_ 2561137482 TrendTireSafety "TrendTireSafety";
BA_ "CI_SigId" SG_ 2561137482 TrendTireSafety 14604;
BA_ "CI_ParId" SG_ 2561137482 TrendTireSafety "IB1851";
BA_ "SigType" SG_ 2561137482 ValidTireSafety 4;
BA_ "GenSigTimeoutTime_SGW" SG_ 2561137482 ValidTireSafety 5000;
BA_ "CI_SigName" SG_ 2561137482 ValidTireSafety "ValidTireSafety";
BA_ "CI_SigId" SG_ 2561137482 ValidTireSafety 14603;
BA_ "CI_ParId" SG_ 2561137482 ValidTireSafety "IB1850";
BA_ "GenSigTimeoutTime_SGW" SG_ 2561137482 ScoreTireSafety 5000;
BA_ "GenSigStartValue" SG_ 2561137482 ScoreTireSafety 1;
BA_ "CI_SigName" SG_ 2561137482 ScoreTireSafety "ScoreTireSafety";
BA_ "CI_SigId" SG_ 2561137482 ScoreTireSafety 14602;
BA_ "CI_ParId" SG_ 2561137482 ScoreTireSafety "IB1849";
BA_ "SigType" SG_ 2561137738 EventTireSafety 4;
BA_ "GenSigTimeoutTime_SGW" SG_ 2561137738 EventTireSafety 5000;
BA_ "CI_SigName" SG_ 2561137738 EventTireSafety "EventTireSafety";
BA_ "CI_SigId" SG_ 2561137738 EventTireSafety 14609;
BA_ "CI_ParId" SG_ 2561137738 EventTireSafety "IB1855";
BA_ "SigType" SG_ 2561137738 EvalMetersTireSafety 1;
BA_ "GenSigTimeoutTime_SGW" SG_ 2561137738 EvalMetersTireSafety 5000;
BA_ "GenSigStartValue" SG_ 2561137738 EvalMetersTireSafety 1;
BA_ "CI_SigName" SG_ 2561137738 EvalMetersTireSafety "EvaluatedMetersTireSafety";
BA_ "CI_SigId" SG_ 2561137738 EvalMetersTireSafety 14608;
BA_ "CI_ParId" SG_ 2561137738 EvalMetersTireSafety "IB1854";
BA_ "GenSigTimeoutTime_SGW" SG_ 2561144650 WeightSlowManeuver 5000;
BA_ "GenSigStartValue" SG_ 2561144650 WeightSlowManeuver 1;
BA_ "CI_SigName" SG_ 2561144650 WeightSlowManeuver "WeightSlowManeuver";
BA_ "CI_SigId" SG_ 2561144650 WeightSlowManeuver 14615;
BA_ "CI_ParId" SG_ 2561144650 WeightSlowManeuver "IB1860";
BA_ "SigType" SG_ 2561144650 BenefitSlowManeuver 4;
BA_ "GenSigTimeoutTime_SGW" SG_ 2561144650 BenefitSlowManeuver 5000;
BA_ "CI_SigName" SG_ 2561144650 BenefitSlowManeuver "BenefitSlowManeuver";
BA_ "CI_SigId" SG_ 2561144650 BenefitSlowManeuver 14614;
BA_ "CI_ParId" SG_ 2561144650 BenefitSlowManeuver "IB1859";
BA_ "GenSigTimeoutTime_SGW" SG_ 2561144650 TrendSlowManeuver 5000;
BA_ "GenSigStartValue" SG_ 2561144650 TrendSlowManeuver 1;
BA_ "CI_SigName" SG_ 2561144650 TrendSlowManeuver "TrendSlowManeuver";
BA_ "CI_SigId" SG_ 2561144650 TrendSlowManeuver 14613;
BA_ "CI_ParId" SG_ 2561144650 TrendSlowManeuver "IB1858";
BA_ "SigType" SG_ 2561144650 ValidSlowManeuver 4;
BA_ "GenSigTimeoutTime_SGW" SG_ 2561144650 ValidSlowManeuver 5000;
BA_ "CI_SigName" SG_ 2561144650 ValidSlowManeuver "ValidSlowManeuver";
BA_ "CI_SigId" SG_ 2561144650 ValidSlowManeuver 14612;
BA_ "CI_ParId" SG_ 2561144650 ValidSlowManeuver "IB1857";
BA_ "GenSigTimeoutTime_SGW" SG_ 2561144650 ScoreSlowManeuver 5000;
BA_ "GenSigStartValue" SG_ 2561144650 ScoreSlowManeuver 1;
BA_ "CI_SigName" SG_ 2561144650 ScoreSlowManeuver "ScoreSlowManeuver";
BA_ "CI_SigId" SG_ 2561144650 ScoreSlowManeuver 14611;
BA_ "CI_ParId" SG_ 2561144650 ScoreSlowManeuver "IB1856";
BA_ "GenSigTimeoutTime_SGW" SG_ 2561144394 WeightSpeed 5000;
BA_ "GenSigStartValue" SG_ 2561144394 WeightSpeed 1;
BA_ "CI_SigName" SG_ 2561144394 WeightSpeed "WeightSpeed";
BA_ "CI_SigId" SG_ 2561144394 WeightSpeed 14621;
BA_ "CI_ParId" SG_ 2561144394 WeightSpeed "IB1865";
BA_ "SigType" SG_ 2561144394 BenefitSpeed 4;
BA_ "GenSigTimeoutTime_SGW" SG_ 2561144394 BenefitSpeed 5000;
BA_ "CI_SigName" SG_ 2561144394 BenefitSpeed "BenefitSpeed";
BA_ "CI_SigId" SG_ 2561144394 BenefitSpeed 14620;
BA_ "CI_ParId" SG_ 2561144394 BenefitSpeed "IB1864";
BA_ "GenSigTimeoutTime_SGW" SG_ 2561144394 TrendSpeed 5000;
BA_ "GenSigStartValue" SG_ 2561144394 TrendSpeed 1;
BA_ "CI_SigName" SG_ 2561144394 TrendSpeed "TrendSpeed";
BA_ "CI_SigId" SG_ 2561144394 TrendSpeed 14619;
BA_ "CI_ParId" SG_ 2561144394 TrendSpeed "IB1863";
BA_ "SigType" SG_ 2561144394 ValidSpeed 4;
BA_ "GenSigTimeoutTime_SGW" SG_ 2561144394 ValidSpeed 5000;
BA_ "CI_SigName" SG_ 2561144394 ValidSpeed "ValidSpeed";
BA_ "CI_SigId" SG_ 2561144394 ValidSpeed 14618;
BA_ "CI_ParId" SG_ 2561144394 ValidSpeed "IB1862";
BA_ "GenSigTimeoutTime_SGW" SG_ 2561144394 ScoreSpeed 5000;
BA_ "GenSigStartValue" SG_ 2561144394 ScoreSpeed 1;
BA_ "CI_SigName" SG_ 2561144394 ScoreSpeed "ScoreSpeed";
BA_ "CI_SigId" SG_ 2561144394 ScoreSpeed 14617;
BA_ "CI_ParId" SG_ 2561144394 ScoreSpeed "IB1861";
BA_ "SigType" SG_ 2561137994 TimeStampTripStart 1;
BA_ "GenSigTimeoutTime_SGW" SG_ 2561137994 TimeStampTripStart 5000;
BA_ "CI_SigName" SG_ 2561137994 TimeStampTripStart "TimeStampTripStart";
BA_ "CI_SigId" SG_ 2561137994 TimeStampTripStart 14624;
BA_ "CI_ParId" SG_ 2561137994 TimeStampTripStart "IB1867";
BA_ "SigType" SG_ 2561137994 OdometerTripStart 1;
BA_ "GenSigTimeoutTime_SGW" SG_ 2561137994 OdometerTripStart 5000;
BA_ "CI_SigName" SG_ 2561137994 OdometerTripStart "OdometerTripStart";
BA_ "CI_SigId" SG_ 2561137994 OdometerTripStart 14623;
BA_ "CI_ParId" SG_ 2561137994 OdometerTripStart "IB1866";
BA_ "SigType" SG_ 2566875466 GaugeMultifonction 1;
BA_ "GenSigTimeoutTime_SGW" SG_ 2566875466 GaugeMultifonction 2500;
BA_ "GenSigTimeoutTime_IC_MulticS" SG_ 2566875466 GaugeMultifonction 2500;
BA_ "GenSigTimeoutTime_IC_MulticII" SG_ 2566875466 GaugeMultifonction 2500;
BA_ "CI_SigName" SG_ 2566875466 GaugeMultifonction "Gauge multifonction (not used)";
BA_ "CI_SigId" SG_ 2566875466 GaugeMultifonction 1922;
BA_ "CI_ParId" SG_ 2566875466 GaugeMultifonction "IB805";
BA_ "SigType" SG_ 2566875466 SpeedLim 1;
BA_ "GenSigTimeoutTime_SGW" SG_ 2566875466 SpeedLim 2500;
BA_ "GenSigTimeoutTime_IC_MulticS" SG_ 2566875466 SpeedLim 2500;
BA_ "GenSigTimeoutTime_IC_MulticII" SG_ 2566875466 SpeedLim 2500;
BA_ "CI_SigName" SG_ 2566875466 SpeedLim "Speed limit";
BA_ "CI_SigId" SG_ 2566875466 SpeedLim 1921;
BA_ "CI_ParId" SG_ 2566875466 SpeedLim "IB804";
BA_ "SigType" SG_ 2566875466 AccPedPrsTooLong 4;
BA_ "GenSigTimeoutTime_SGW" SG_ 2566875466 AccPedPrsTooLong 2500;
BA_ "GenSigTimeoutTime_IC_MulticS" SG_ 2566875466 AccPedPrsTooLong 2500;
BA_ "GenSigTimeoutTime_IC_MulticII" SG_ 2566875466 AccPedPrsTooLong 2500;
BA_ "CI_SigName" SG_ 2566875466 AccPedPrsTooLong "Accelerator pedal pressed too long";
BA_ "CI_SigId" SG_ 2566875466 AccPedPrsTooLong 1920;
BA_ "CI_ParId" SG_ 2566875466 AccPedPrsTooLong "IB803";
BA_ "SigType" SG_ 2566875466 MaxSpeedExc 4;
BA_ "GenSigTimeoutTime_SGW" SG_ 2566875466 MaxSpeedExc 2500;
BA_ "GenSigTimeoutTime_IC_MulticS" SG_ 2566875466 MaxSpeedExc 2500;
BA_ "GenSigTimeoutTime_IC_MulticII" SG_ 2566875466 MaxSpeedExc 2500;
BA_ "CI_SigName" SG_ 2566875466 MaxSpeedExc "Maximum speed exceeded";
BA_ "CI_SigId" SG_ 2566875466 MaxSpeedExc 1919;
BA_ "CI_ParId" SG_ 2566875466 MaxSpeedExc "IB802";
BA_ "SigType" SG_ 2566875466 HarshVertAccel_Down 4;
BA_ "GenSigTimeoutTime_SGW" SG_ 2566875466 HarshVertAccel_Down 2500;
BA_ "GenSigTimeoutTime_IC_MulticS" SG_ 2566875466 HarshVertAccel_Down 2500;
BA_ "GenSigTimeoutTime_IC_MulticII" SG_ 2566875466 HarshVertAccel_Down 2500;
BA_ "CI_SigName" SG_ 2566875466 HarshVertAccel_Down "Harsh vertical acceleration (downwards)";
BA_ "CI_SigId" SG_ 2566875466 HarshVertAccel_Down 1918;
BA_ "CI_ParId" SG_ 2566875466 HarshVertAccel_Down "IB801";
BA_ "SigType" SG_ 2566875466 HarshVertAccel_UP 4;
BA_ "GenSigTimeoutTime_SGW" SG_ 2566875466 HarshVertAccel_UP 2500;
BA_ "GenSigTimeoutTime_IC_MulticS" SG_ 2566875466 HarshVertAccel_UP 2500;
BA_ "GenSigTimeoutTime_IC_MulticII" SG_ 2566875466 HarshVertAccel_UP 2500;
BA_ "CI_SigName" SG_ 2566875466 HarshVertAccel_UP "Harsh vertical acceleration (upwards)";
BA_ "CI_SigId" SG_ 2566875466 HarshVertAccel_UP 1917;
BA_ "CI_ParId" SG_ 2566875466 HarshVertAccel_UP "IB800";
BA_ "SigType" SG_ 2566875466 HarshAccel 4;
BA_ "GenSigTimeoutTime_SGW" SG_ 2566875466 HarshAccel 2500;
BA_ "GenSigTimeoutTime_IC_MulticS" SG_ 2566875466 HarshAccel 2500;
BA_ "GenSigTimeoutTime_IC_MulticII" SG_ 2566875466 HarshAccel 2500;
BA_ "CI_SigName" SG_ 2566875466 HarshAccel "Harsh acceleration";
BA_ "CI_SigId" SG_ 2566875466 HarshAccel 1916;
BA_ "CI_ParId" SG_ 2566875466 HarshAccel "IB799";
BA_ "SigType" SG_ 2566875466 HarshBrk 4;
BA_ "GenSigTimeoutTime_SGW" SG_ 2566875466 HarshBrk 2500;
BA_ "GenSigTimeoutTime_IC_MulticS" SG_ 2566875466 HarshBrk 2500;
BA_ "GenSigTimeoutTime_IC_MulticII" SG_ 2566875466 HarshBrk 2500;
BA_ "CI_SigName" SG_ 2566875466 HarshBrk "Harsh braking";
BA_ "CI_SigId" SG_ 2566875466 HarshBrk 1915;
BA_ "CI_ParId" SG_ 2566875466 HarshBrk "IB798";
BA_ "SigType" SG_ 2566875466 HarshLeftTurn 4;
BA_ "GenSigTimeoutTime_SGW" SG_ 2566875466 HarshLeftTurn 2500;
BA_ "GenSigTimeoutTime_IC_MulticS" SG_ 2566875466 HarshLeftTurn 2500;
BA_ "GenSigTimeoutTime_IC_MulticII" SG_ 2566875466 HarshLeftTurn 2500;
BA_ "CI_SigName" SG_ 2566875466 HarshLeftTurn "Harsh left turn";
BA_ "CI_SigId" SG_ 2566875466 HarshLeftTurn 1914;
BA_ "CI_ParId" SG_ 2566875466 HarshLeftTurn "IB797";
BA_ "SigType" SG_ 2566875466 HarshRightTurn 4;
BA_ "GenSigTimeoutTime_SGW" SG_ 2566875466 HarshRightTurn 2500;
BA_ "GenSigTimeoutTime_IC_MulticS" SG_ 2566875466 HarshRightTurn 2500;
BA_ "GenSigTimeoutTime_IC_MulticII" SG_ 2566875466 HarshRightTurn 2500;
BA_ "CI_SigName" SG_ 2566875466 HarshRightTurn "Harsh right turn";
BA_ "CI_SigId" SG_ 2566875466 HarshRightTurn 1913;
BA_ "CI_ParId" SG_ 2566875466 HarshRightTurn "IB796";
BA_ "GenSigTimeoutTime_SGW" SG_ 2561138250 TripEndReason 5000;
BA_ "GenSigTimeoutTime_IC_MulticS" SG_ 2561138250 TripEndReason 5000;
BA_ "CI_SigName" SG_ 2561138250 TripEndReason "TripEndReason";
BA_ "CI_SigId" SG_ 2561138250 TripEndReason 14629;
BA_ "CI_ParId" SG_ 2561138250 TripEndReason "IB1871";
BA_ "SigType" SG_ 2561138250 TripActive 4;
BA_ "GenSigTimeoutTime_SGW" SG_ 2561138250 TripActive 5000;
BA_ "GenSigTimeoutTime_IC_MulticS" SG_ 2561138250 TripActive 5000;
BA_ "CI_SigName" SG_ 2561138250 TripActive "TripActive";
BA_ "CI_SigId" SG_ 2561138250 TripActive 14628;
BA_ "CI_ParId" SG_ 2561138250 TripActive "IB1870";
BA_ "SigType" SG_ 2561138250 TripEnded 4;
BA_ "GenSigTimeoutTime_SGW" SG_ 2561138250 TripEnded 5000;
BA_ "GenSigTimeoutTime_IC_MulticS" SG_ 2561138250 TripEnded 5000;
BA_ "CI_SigName" SG_ 2561138250 TripEnded "TripEnded";
BA_ "CI_SigId" SG_ 2561138250 TripEnded 14627;
BA_ "CI_ParId" SG_ 2561138250 TripEnded "IB1869";
BA_ "SigType" SG_ 2561138250 TripStarted 4;
BA_ "GenSigTimeoutTime_SGW" SG_ 2561138250 TripStarted 5000;
BA_ "GenSigTimeoutTime_IC_MulticS" SG_ 2561138250 TripStarted 5000;
BA_ "CI_SigName" SG_ 2561138250 TripStarted "TripStarted";
BA_ "CI_SigId" SG_ 2561138250 TripStarted 14626;
BA_ "CI_ParId" SG_ 2561138250 TripStarted "IB1868";
BA_ "GenSigTimeoutTime_SGW" SG_ 2561138506 WeightStabilityControl 5000;
BA_ "GenSigStartValue" SG_ 2561138506 WeightStabilityControl 1;
BA_ "CI_SigName" SG_ 2561138506 WeightStabilityControl "WeightStabilityControl";
BA_ "CI_SigId" SG_ 2561138506 WeightStabilityControl 14635;
BA_ "CI_ParId" SG_ 2561138506 WeightStabilityControl "IB1876";
BA_ "SigType" SG_ 2561138506 BenefitStabilityControl 4;
BA_ "GenSigTimeoutTime_SGW" SG_ 2561138506 BenefitStabilityControl 5000;
BA_ "CI_SigName" SG_ 2561138506 BenefitStabilityControl "BenefitStabilityControl";
BA_ "CI_SigId" SG_ 2561138506 BenefitStabilityControl 14634;
BA_ "CI_ParId" SG_ 2561138506 BenefitStabilityControl "IB1875";
BA_ "GenSigTimeoutTime_SGW" SG_ 2561138506 TrendStabilityControl 5000;
BA_ "GenSigStartValue" SG_ 2561138506 TrendStabilityControl 1;
BA_ "CI_SigName" SG_ 2561138506 TrendStabilityControl "TrendStabilityControl";
BA_ "CI_SigId" SG_ 2561138506 TrendStabilityControl 14633;
BA_ "CI_ParId" SG_ 2561138506 TrendStabilityControl "IB1874";
BA_ "SigType" SG_ 2561138506 ValidStabilityControl 4;
BA_ "GenSigTimeoutTime_SGW" SG_ 2561138506 ValidStabilityControl 5000;
BA_ "CI_SigName" SG_ 2561138506 ValidStabilityControl "ValidStabilityControl";
BA_ "CI_SigId" SG_ 2561138506 ValidStabilityControl 14632;
BA_ "CI_ParId" SG_ 2561138506 ValidStabilityControl "IB1873";
BA_ "GenSigTimeoutTime_SGW" SG_ 2561138506 ScoreStabilityControl 5000;
BA_ "GenSigStartValue" SG_ 2561138506 ScoreStabilityControl 1;
BA_ "CI_SigName" SG_ 2561138506 ScoreStabilityControl "ScoreStabilityControl";
BA_ "CI_SigId" SG_ 2561138506 ScoreStabilityControl 14631;
BA_ "CI_ParId" SG_ 2561138506 ScoreStabilityControl "IB1872";
BA_ "SigType" SG_ 2561138762 EventStabilityControl 4;
BA_ "GenSigTimeoutTime_SGW" SG_ 2561138762 EventStabilityControl 5000;
BA_ "CI_SigName" SG_ 2561138762 EventStabilityControl "EventStabilityControl";
BA_ "CI_SigId" SG_ 2561138762 EventStabilityControl 14638;
BA_ "CI_ParId" SG_ 2561138762 EventStabilityControl "IB1878";
BA_ "GenSigTimeoutTime_SGW" SG_ 2561138762 EvalMetersStabilityCtrl 5000;
BA_ "GenSigStartValue" SG_ 2561138762 EvalMetersStabilityCtrl 1;
BA_ "CI_SigName" SG_ 2561138762 EvalMetersStabilityCtrl "EvaluatedMetersStabilityControl";
BA_ "CI_SigId" SG_ 2561138762 EvalMetersStabilityCtrl 14637;
BA_ "CI_ParId" SG_ 2561138762 EvalMetersStabilityCtrl "IB1877";
BA_ "GenSigTimeoutTime_SGW" SG_ 2561139018 WeightStop 5000;
BA_ "GenSigStartValue" SG_ 2561139018 WeightStop 1;
BA_ "CI_SigName" SG_ 2561139018 WeightStop "WeightStop";
BA_ "CI_SigId" SG_ 2561139018 WeightStop 14644;
BA_ "CI_ParId" SG_ 2561139018 WeightStop "IB1883";
BA_ "SigType" SG_ 2561139018 BenefitStop 4;
BA_ "GenSigTimeoutTime_SGW" SG_ 2561139018 BenefitStop 5000;
BA_ "CI_SigName" SG_ 2561139018 BenefitStop "BenefitStop";
BA_ "CI_SigId" SG_ 2561139018 BenefitStop 14643;
BA_ "CI_ParId" SG_ 2561139018 BenefitStop "IB1882";
BA_ "GenSigTimeoutTime_SGW" SG_ 2561139018 TrendStop 5000;
BA_ "GenSigStartValue" SG_ 2561139018 TrendStop 1;
BA_ "CI_SigName" SG_ 2561139018 TrendStop "TrendStop";
BA_ "CI_SigId" SG_ 2561139018 TrendStop 14642;
BA_ "CI_ParId" SG_ 2561139018 TrendStop "IB1881";
BA_ "SigType" SG_ 2561139018 ValidStop 4;
BA_ "GenSigTimeoutTime_SGW" SG_ 2561139018 ValidStop 5000;
BA_ "CI_SigName" SG_ 2561139018 ValidStop "ValidStop";
BA_ "CI_SigId" SG_ 2561139018 ValidStop 14641;
BA_ "CI_ParId" SG_ 2561139018 ValidStop "IB1880";
BA_ "GenSigTimeoutTime_SGW" SG_ 2561139018 ScoreStop 5000;
BA_ "GenSigStartValue" SG_ 2561139018 ScoreStop 1;
BA_ "CI_SigName" SG_ 2561139018 ScoreStop "ScoreStop";
BA_ "CI_SigId" SG_ 2561139018 ScoreStop 14640;
BA_ "CI_ParId" SG_ 2561139018 ScoreStop "IB1879";
BA_ "GenSigTimeoutTime_SGW" SG_ 2561139274 MaxDecelerationStop 5000;
BA_ "CI_SigName" SG_ 2561139274 MaxDecelerationStop "MaxDecelerationStop";
BA_ "CI_SigId" SG_ 2561139274 MaxDecelerationStop 14652;
BA_ "CI_ParId" SG_ 2561139274 MaxDecelerationStop "IB1890";
BA_ "GenSigTimeoutTime_SGW" SG_ 2561139274 ManeuverCountStop 5000;
BA_ "GenSigStartValue" SG_ 2561139274 ManeuverCountStop 1;
BA_ "CI_SigName" SG_ 2561139274 ManeuverCountStop "ManeuverCountStop";
BA_ "CI_SigId" SG_ 2561139274 ManeuverCountStop 14651;
BA_ "CI_ParId" SG_ 2561139274 ManeuverCountStop "IB1889";
BA_ "GenSigTimeoutTime_SGW" SG_ 2561139274 LastManeuverScoreStop 5000;
BA_ "GenSigStartValue" SG_ 2561139274 LastManeuverScoreStop 1;
BA_ "CI_SigName" SG_ 2561139274 LastManeuverScoreStop "LastManeuverScoreStop";
BA_ "CI_SigId" SG_ 2561139274 LastManeuverScoreStop 14650;
BA_ "CI_ParId" SG_ 2561139274 LastManeuverScoreStop "IB1888";
BA_ "SigType" SG_ 2561139274 StartingSpeedStop 1;
BA_ "GenSigTimeoutTime_SGW" SG_ 2561139274 StartingSpeedStop 5000;
BA_ "CI_SigName" SG_ 2561139274 StartingSpeedStop "StartingSpeedStop";
BA_ "CI_SigId" SG_ 2561139274 StartingSpeedStop 14649;
BA_ "CI_ParId" SG_ 2561139274 StartingSpeedStop "IB1887";
BA_ "SigType" SG_ 2561139274 DurationStop 1;
BA_ "GenSigTimeoutTime_SGW" SG_ 2561139274 DurationStop 5000;
BA_ "GenSigStartValue" SG_ 2561139274 DurationStop 1;
BA_ "CI_SigName" SG_ 2561139274 DurationStop "DurationStop";
BA_ "CI_SigId" SG_ 2561139274 DurationStop 14648;
BA_ "CI_ParId" SG_ 2561139274 DurationStop "IB1886";
BA_ "SigType" SG_ 2561139274 PanicBrakeState 4;
BA_ "GenSigTimeoutTime_SGW" SG_ 2561139274 PanicBrakeState 5000;
BA_ "CI_SigName" SG_ 2561139274 PanicBrakeState "PanicBrakeState";
BA_ "CI_SigId" SG_ 2561139274 PanicBrakeState 14647;
BA_ "CI_ParId" SG_ 2561139274 PanicBrakeState "IB1885";
BA_ "SigType" SG_ 2561139274 EventStop 4;
BA_ "GenSigTimeoutTime_SGW" SG_ 2561139274 EventStop 5000;
BA_ "CI_SigName" SG_ 2561139274 EventStop "EventStop";
BA_ "CI_SigId" SG_ 2561139274 EventStop 14646;
BA_ "CI_ParId" SG_ 2561139274 EventStop "IB1884";
BA_ "SigType" SG_ 2561141066 EventValid 4;
BA_ "GenSigTimeoutTime_SGW" SG_ 2561141066 EventValid 5000;
BA_ "CI_SigName" SG_ 2561141066 EventValid "EventValid";
BA_ "CI_SigId" SG_ 2561141066 EventValid 14659;
BA_ "CI_ParId" SG_ 2561141066 EventValid "IB1896";
BA_ "GenSigTimeoutTime_SGW" SG_ 2561141066 EventHdop 5000;
BA_ "CI_SigName" SG_ 2561141066 EventHdop "EventHdop";
BA_ "CI_SigId" SG_ 2561141066 EventHdop 14658;
BA_ "CI_ParId" SG_ 2561141066 EventHdop "IB1895";
BA_ "GenSigTimeoutTime_SGW" SG_ 2561141066 EventVdop 5000;
BA_ "CI_SigName" SG_ 2561141066 EventVdop "EventVdop";
BA_ "CI_SigId" SG_ 2561141066 EventVdop 14657;
BA_ "CI_ParId" SG_ 2561141066 EventVdop "IB1894";
BA_ "GenSigTimeoutTime_SGW" SG_ 2561141066 EventAltitude 5000;
BA_ "GenSigStartValue" SG_ 2561141066 EventAltitude 2500;
BA_ "CI_SigName" SG_ 2561141066 EventAltitude "EventAltitude";
BA_ "CI_SigId" SG_ 2561141066 EventAltitude 14656;
BA_ "CI_ParId" SG_ 2561141066 EventAltitude "IB1893";
BA_ "GenSigTimeoutTime_SGW" SG_ 2561141066 EventLongitude 5000;
BA_ "GenSigStartValue" SG_ 2561141066 EventLongitude 131072;
BA_ "CI_SigName" SG_ 2561141066 EventLongitude "EventLongitude";
BA_ "CI_SigId" SG_ 2561141066 EventLongitude 14655;
BA_ "CI_ParId" SG_ 2561141066 EventLongitude "IB1892";
BA_ "GenSigTimeoutTime_SGW" SG_ 2561141066 EventLatitude 5000;
BA_ "GenSigStartValue" SG_ 2561141066 EventLatitude 131072;
BA_ "CI_SigName" SG_ 2561141066 EventLatitude "EventLatitude";
BA_ "CI_SigId" SG_ 2561141066 EventLatitude 14654;
BA_ "CI_ParId" SG_ 2561141066 EventLatitude "IB1891";
BA_ "GenSigTimeoutTime_SGW" SG_ 2561139530 WeightTire 5000;
BA_ "GenSigStartValue" SG_ 2561139530 WeightTire 1;
BA_ "CI_SigName" SG_ 2561139530 WeightTire "WeightTire";
BA_ "CI_SigId" SG_ 2561139530 WeightTire 14665;
BA_ "CI_ParId" SG_ 2561139530 WeightTire "IB1901";
BA_ "SigType" SG_ 2561139530 BenefitTire 4;
BA_ "GenSigTimeoutTime_SGW" SG_ 2561139530 BenefitTire 5000;
BA_ "CI_SigName" SG_ 2561139530 BenefitTire "BenefitTire";
BA_ "CI_SigId" SG_ 2561139530 BenefitTire 14664;
BA_ "CI_ParId" SG_ 2561139530 BenefitTire "IB1900";
BA_ "GenSigTimeoutTime_SGW" SG_ 2561139530 TrendTire 5000;
BA_ "GenSigStartValue" SG_ 2561139530 TrendTire 1;
BA_ "CI_SigName" SG_ 2561139530 TrendTire "TrendTire";
BA_ "CI_SigId" SG_ 2561139530 TrendTire 14663;
BA_ "CI_ParId" SG_ 2561139530 TrendTire "IB1899";
BA_ "SigType" SG_ 2561139530 ValidTire 4;
BA_ "GenSigTimeoutTime_SGW" SG_ 2561139530 ValidTire 5000;
BA_ "CI_SigName" SG_ 2561139530 ValidTire "ValidTire";
BA_ "CI_SigId" SG_ 2561139530 ValidTire 14662;
BA_ "CI_ParId" SG_ 2561139530 ValidTire "IB1898";
BA_ "GenSigTimeoutTime_SGW" SG_ 2561139530 ScoreTire 5000;
BA_ "GenSigStartValue" SG_ 2561139530 ScoreTire 1;
BA_ "CI_SigName" SG_ 2561139530 ScoreTire "ScoreTire";
BA_ "CI_SigId" SG_ 2561139530 ScoreTire 14661;
BA_ "CI_ParId" SG_ 2561139530 ScoreTire "IB1897";
BA_ "SigType" SG_ 2561139786 EventTireSaving 4;
BA_ "GenSigTimeoutTime_SGW" SG_ 2561139786 EventTireSaving 5000;
BA_ "CI_SigName" SG_ 2561139786 EventTireSaving "EventTireSaving";
BA_ "CI_SigId" SG_ 2561139786 EventTireSaving 14668;
BA_ "CI_ParId" SG_ 2561139786 EventTireSaving "IB1903";
BA_ "GenSigTimeoutTime_SGW" SG_ 2561139786 EvaluatedSamplesTire 5000;
BA_ "GenSigStartValue" SG_ 2561139786 EvaluatedSamplesTire 1;
BA_ "CI_SigName" SG_ 2561139786 EvaluatedSamplesTire "EvaluatedSamplesTire";
BA_ "CI_SigId" SG_ 2561139786 EvaluatedSamplesTire 14667;
BA_ "CI_ParId" SG_ 2561139786 EvaluatedSamplesTire "IB1902";
BA_ "GenSigTimeoutTime_SGW" SG_ 2561145674 TractionEnergyConsTripB 5000;
BA_ "GenSigTimeoutTime_IC_MulticS" SG_ 2561145674 TractionEnergyConsTripB 5000;
BA_ "GenSigStartValue" SG_ 2561145674 TractionEnergyConsTripB 10;
BA_ "CI_SigName" SG_ 2561145674 TractionEnergyConsTripB "TractionEnergyConsumption_TripB";
BA_ "CI_SigId" SG_ 2561145674 TractionEnergyConsTripB 14674;
BA_ "CI_ParId" SG_ 2561145674 TractionEnergyConsTripB "IB1908";
BA_ "GenSigTimeoutTime_SGW" SG_ 2561145674 ScoreFuel_TripB 5000;
BA_ "GenSigTimeoutTime_IC_MulticS" SG_ 2561145674 ScoreFuel_TripB 5000;
BA_ "GenSigStartValue" SG_ 2561145674 ScoreFuel_TripB 1;
BA_ "CI_SigName" SG_ 2561145674 ScoreFuel_TripB "ScoreFuel_TripB";
BA_ "CI_SigId" SG_ 2561145674 ScoreFuel_TripB 14673;
BA_ "CI_ParId" SG_ 2561145674 ScoreFuel_TripB "IB1907";
BA_ "GenSigTimeoutTime_SGW" SG_ 2561145674 ScoreStop_TripB 5000;
BA_ "GenSigTimeoutTime_IC_MulticS" SG_ 2561145674 ScoreStop_TripB 5000;
BA_ "GenSigStartValue" SG_ 2561145674 ScoreStop_TripB 1;
BA_ "CI_SigName" SG_ 2561145674 ScoreStop_TripB "ScoreStop_TripB";
BA_ "CI_SigId" SG_ 2561145674 ScoreStop_TripB 14672;
BA_ "CI_ParId" SG_ 2561145674 ScoreStop_TripB "IB1906";
BA_ "GenSigTimeoutTime_SGW" SG_ 2561145674 ScoreInertia_TripB 5000;
BA_ "GenSigTimeoutTime_IC_MulticS" SG_ 2561145674 ScoreInertia_TripB 5000;
BA_ "GenSigStartValue" SG_ 2561145674 ScoreInertia_TripB 1;
BA_ "CI_SigName" SG_ 2561145674 ScoreInertia_TripB "ScoreInertia_TripB";
BA_ "CI_SigId" SG_ 2561145674 ScoreInertia_TripB 14671;
BA_ "CI_ParId" SG_ 2561145674 ScoreInertia_TripB "IB1905";
BA_ "GenSigTimeoutTime_SGW" SG_ 2561145674 ScoreAcceleration_TripB 5000;
BA_ "GenSigTimeoutTime_IC_MulticS" SG_ 2561145674 ScoreAcceleration_TripB 5000;
BA_ "GenSigStartValue" SG_ 2561145674 ScoreAcceleration_TripB 1;
BA_ "CI_SigName" SG_ 2561145674 ScoreAcceleration_TripB "ScoreAcceleration_TripB";
BA_ "CI_SigId" SG_ 2561145674 ScoreAcceleration_TripB 14670;
BA_ "CI_ParId" SG_ 2561145674 ScoreAcceleration_TripB "IB1904";
BA_ "GenSigTimeoutTime_SGW" SG_ 2561144906 WeightVehicleControl 5000;
BA_ "GenSigStartValue" SG_ 2561144906 WeightVehicleControl 1;
BA_ "CI_SigName" SG_ 2561144906 WeightVehicleControl "WeightVehicleControl";
BA_ "CI_SigId" SG_ 2561144906 WeightVehicleControl 14680;
BA_ "CI_ParId" SG_ 2561144906 WeightVehicleControl "IB1913";
BA_ "SigType" SG_ 2561144906 BenefitVehicleControl 4;
BA_ "GenSigTimeoutTime_SGW" SG_ 2561144906 BenefitVehicleControl 5000;
BA_ "CI_SigName" SG_ 2561144906 BenefitVehicleControl "BenefitVehicleControl";
BA_ "CI_SigId" SG_ 2561144906 BenefitVehicleControl 14679;
BA_ "CI_ParId" SG_ 2561144906 BenefitVehicleControl "IB1912";
BA_ "GenSigTimeoutTime_SGW" SG_ 2561144906 TrendVehicleControl 5000;
BA_ "GenSigStartValue" SG_ 2561144906 TrendVehicleControl 1;
BA_ "CI_SigName" SG_ 2561144906 TrendVehicleControl "TrendVehicleControl";
BA_ "CI_SigId" SG_ 2561144906 TrendVehicleControl 14678;
BA_ "CI_ParId" SG_ 2561144906 TrendVehicleControl "IB1911";
BA_ "SigType" SG_ 2561144906 ValidVehicleControl 4;
BA_ "GenSigTimeoutTime_SGW" SG_ 2561144906 ValidVehicleControl 5000;
BA_ "CI_SigName" SG_ 2561144906 ValidVehicleControl "ValidVehicleControl";
BA_ "CI_SigId" SG_ 2561144906 ValidVehicleControl 14677;
BA_ "CI_ParId" SG_ 2561144906 ValidVehicleControl "IB1910";
BA_ "GenSigTimeoutTime_SGW" SG_ 2561144906 ScoreVehicleControl 5000;
BA_ "GenSigStartValue" SG_ 2561144906 ScoreVehicleControl 1;
BA_ "CI_SigName" SG_ 2561144906 ScoreVehicleControl "ScoreVehicleControl";
BA_ "CI_SigId" SG_ 2561144906 ScoreVehicleControl 14676;
BA_ "CI_ParId" SG_ 2561144906 ScoreVehicleControl "IB1909";
BA_ "GenSigTimeoutTime_SGW" SG_ 2561140298 VersionRevision 5000;
BA_ "GenSigStartValue" SG_ 2561140298 VersionRevision 1;
BA_ "CI_SigName" SG_ 2561140298 VersionRevision "VersionRevision";
BA_ "CI_SigId" SG_ 2561140298 VersionRevision 14685;
BA_ "CI_ParId" SG_ 2561140298 VersionRevision "IB1917";
BA_ "GenSigTimeoutTime_SGW" SG_ 2561140298 VersionModel 5000;
BA_ "GenSigStartValue" SG_ 2561140298 VersionModel 1;
BA_ "CI_SigName" SG_ 2561140298 VersionModel "VersionModel";
BA_ "CI_SigId" SG_ 2561140298 VersionModel 14684;
BA_ "CI_ParId" SG_ 2561140298 VersionModel "IB1916";
BA_ "GenSigTimeoutTime_SGW" SG_ 2561140298 VersionMinor 5000;
BA_ "GenSigStartValue" SG_ 2561140298 VersionMinor 1;
BA_ "CI_SigName" SG_ 2561140298 VersionMinor "VersionMinor";
BA_ "CI_SigId" SG_ 2561140298 VersionMinor 14683;
BA_ "CI_ParId" SG_ 2561140298 VersionMinor "IB1915";
BA_ "GenSigTimeoutTime_SGW" SG_ 2561140298 VersionMajor 5000;
BA_ "GenSigStartValue" SG_ 2561140298 VersionMajor 1;
BA_ "CI_SigName" SG_ 2561140298 VersionMajor "VersionMajor";
BA_ "CI_SigId" SG_ 2561140298 VersionMajor 14682;
BA_ "CI_ParId" SG_ 2561140298 VersionMajor "IB1914";
BA_ "GenSigTimeoutTime_SGW" SG_ 2561142602 WeightVertical 5000;
BA_ "GenSigStartValue" SG_ 2561142602 WeightVertical 1;
BA_ "CI_SigName" SG_ 2561142602 WeightVertical "WeightVertical";
BA_ "CI_SigId" SG_ 2561142602 WeightVertical 14691;
BA_ "CI_ParId" SG_ 2561142602 WeightVertical "IB1922";
BA_ "SigType" SG_ 2561142602 BenefitVertical 4;
BA_ "GenSigTimeoutTime_SGW" SG_ 2561142602 BenefitVertical 5000;
BA_ "CI_SigName" SG_ 2561142602 BenefitVertical "BenefitVertical";
BA_ "CI_SigId" SG_ 2561142602 BenefitVertical 14690;
BA_ "CI_ParId" SG_ 2561142602 BenefitVertical "IB1921";
BA_ "GenSigTimeoutTime_SGW" SG_ 2561142602 TrendVertical 5000;
BA_ "GenSigStartValue" SG_ 2561142602 TrendVertical 1;
BA_ "CI_SigName" SG_ 2561142602 TrendVertical "TrendVertical";
BA_ "CI_SigId" SG_ 2561142602 TrendVertical 14689;
BA_ "CI_ParId" SG_ 2561142602 TrendVertical "IB1920";
BA_ "SigType" SG_ 2561142602 ValidVertical 4;
BA_ "GenSigTimeoutTime_SGW" SG_ 2561142602 ValidVertical 5000;
BA_ "CI_SigName" SG_ 2561142602 ValidVertical "ValidVertical";
BA_ "CI_SigId" SG_ 2561142602 ValidVertical 14688;
BA_ "CI_ParId" SG_ 2561142602 ValidVertical "IB1919";
BA_ "GenSigTimeoutTime_SGW" SG_ 2561142602 ScoreVertical 5000;
BA_ "CI_SigName" SG_ 2561142602 ScoreVertical "ScoreVertical";
BA_ "CI_SigId" SG_ 2561142602 ScoreVertical 14687;
BA_ "CI_ParId" SG_ 2561142602 ScoreVertical "IB1918";
BA_ "SigType" SG_ 2561143626 EvalMetersVertical 1;
BA_ "GenSigTimeoutTime_SGW" SG_ 2561143626 EvalMetersVertical 5000;
BA_ "GenSigStartValue" SG_ 2561143626 EvalMetersVertical 1;
BA_ "CI_SigName" SG_ 2561143626 EvalMetersVertical "EvaluatedMetersVertical";
BA_ "CI_SigId" SG_ 2561143626 EvalMetersVertical 14694;
BA_ "CI_ParId" SG_ 2561143626 EvalMetersVertical "IB1924";
BA_ "SigType" SG_ 2561143626 NumEventsVertical 1;
BA_ "GenSigTimeoutTime_SGW" SG_ 2561143626 NumEventsVertical 5000;
BA_ "GenSigStartValue" SG_ 2561143626 NumEventsVertical 1;
BA_ "CI_SigName" SG_ 2561143626 NumEventsVertical "NumEventsVertical";
BA_ "CI_SigId" SG_ 2561143626 NumEventsVertical 14693;
BA_ "CI_ParId" SG_ 2561143626 NumEventsVertical "IB1923";
BA_ "SigType" SG_ 2565865739 Atc_AsrInfoSig 4;
BA_ "SPN" SG_ 2565865739 Atc_AsrInfoSig 1793;
BA_ "GenSigTimeoutTime_VCM" SG_ 2565865739 Atc_AsrInfoSig 500;
BA_ "GenSigTimeoutTime_SGW" SG_ 2565865739 Atc_AsrInfoSig 500;
BA_ "GenSigTimeoutTime_PCM" SG_ 2565865739 Atc_AsrInfoSig 500;
BA_ "GenSigTimeoutTime_IC_MulticS" SG_ 2565865739 Atc_AsrInfoSig 500;
BA_ "GenSigTimeoutTime_IC_MulticII" SG_ 2565865739 Atc_AsrInfoSig 500;
BA_ "CI_SigName" SG_ 2565865739 Atc_AsrInfoSig "ATC/ASR Information Signal";
BA_ "CI_SigId" SG_ 2565865739 Atc_AsrInfoSig 248;
BA_ "CI_ParId" SG_ 2565865739 Atc_AsrInfoSig "1793";
BA_ "SigType" SG_ 2565865739 AbsFullyOp 4;
BA_ "SPN" SG_ 2565865739 AbsFullyOp 1243;
BA_ "GenSigTimeoutTime_VCM" SG_ 2565865739 AbsFullyOp 500;
BA_ "GenSigTimeoutTime_SGW" SG_ 2565865739 AbsFullyOp 500;
BA_ "GenSigTimeoutTime_RM_IRCS" SG_ 2565865739 AbsFullyOp 500;
BA_ "GenSigTimeoutTime_PCM" SG_ 2565865739 AbsFullyOp 500;
BA_ "GenSigTimeoutTime_IC_MulticS" SG_ 2565865739 AbsFullyOp 500;
BA_ "GenSigTimeoutTime_IC_MulticII" SG_ 2565865739 AbsFullyOp 500;
BA_ "GenSigTimeoutTime_ETC_Ecolife2" SG_ 2565865739 AbsFullyOp 500;
BA_ "GenSigTimeoutTime_ETC_DiwaNXT_MH" SG_ 2565865739 AbsFullyOp 500;
BA_ "GenSigTimeoutTime_ETC_DiwaNXT" SG_ 2565865739 AbsFullyOp 500;
BA_ "GenSigTimeoutTime_BCM_NBM" SG_ 2565865739 AbsFullyOp 500;
BA_ "GenSigTimeoutTime_ADCU" SG_ 2565865739 AbsFullyOp 500;
BA_ "CI_SigName" SG_ 2565865739 AbsFullyOp "ABS Fully Operational";
BA_ "CI_SigId" SG_ 2565865739 AbsFullyOp 245;
BA_ "CI_ParId" SG_ 2565865739 AbsFullyOp "1243";
BA_ "SigType" SG_ 2565865739 BrkPedPos 1;
BA_ "SPN" SG_ 2565865739 BrkPedPos 521;
BA_ "GenSigTimeoutTime_VMU" SG_ 2565865739 BrkPedPos 500;
BA_ "GenSigTimeoutTime_VCU" SG_ 2565865739 BrkPedPos 500;
BA_ "GenSigTimeoutTime_VCM" SG_ 2565865739 BrkPedPos 500;
BA_ "GenSigTimeoutTime_SGW" SG_ 2565865739 BrkPedPos 500;
BA_ "GenSigTimeoutTime_PCM" SG_ 2565865739 BrkPedPos 500;
BA_ "GenSigTimeoutTime_MPPxPTFE2" SG_ 2565865739 BrkPedPos 500;
BA_ "GenSigTimeoutTime_INVEM1_ELFA3" SG_ 2565865739 BrkPedPos 500;
BA_ "GenSigTimeoutTime_IC_MulticII" SG_ 2565865739 BrkPedPos 500;
BA_ "GenSigTimeoutTime_FMS_FMS5" SG_ 2565865739 BrkPedPos 500;
BA_ "GenSigTimeoutTime_FMS_FMS4" SG_ 2565865739 BrkPedPos 500;
BA_ "GenSigTimeoutTime_ETC_Ecolife2" SG_ 2565865739 BrkPedPos 500;
BA_ "GenSigTimeoutTime_ETC_DiwaNXT_MH" SG_ 2565865739 BrkPedPos 500;
BA_ "GenSigTimeoutTime_ETC_DiwaNXT" SG_ 2565865739 BrkPedPos 500;
BA_ "GenSigTimeoutTime_DICO" SG_ 2565865739 BrkPedPos 500;
BA_ "GenSigTimeoutTime_BCM_NBM" SG_ 2565865739 BrkPedPos 500;
BA_ "GenSigTimeoutTime_ADCU" SG_ 2565865739 BrkPedPos 500;
BA_ "CI_SigName" SG_ 2565865739 BrkPedPos "Brake Pedal Position";
BA_ "CI_SigId" SG_ 2565865739 BrkPedPos 235;
BA_ "CI_ParId" SG_ 2565865739 BrkPedPos "521";
BA_ "SigType" SG_ 2565865739 AbsActv 4;
BA_ "SPN" SG_ 2565865739 AbsActv 563;
BA_ "GenSigTimeoutTime_VMU" SG_ 2565865739 AbsActv 500;
BA_ "GenSigTimeoutTime_VCU" SG_ 2565865739 AbsActv 500;
BA_ "GenSigTimeoutTime_VCM" SG_ 2565865739 AbsActv 500;
BA_ "GenSigTimeoutTime_SGW" SG_ 2565865739 AbsActv 500;
BA_ "GenSigTimeoutTime_PCM" SG_ 2565865739 AbsActv 500;
BA_ "GenSigTimeoutTime_INVEM1_ELFA3" SG_ 2565865739 AbsActv 500;
BA_ "GenSigTimeoutTime_IC_MulticII" SG_ 2565865739 AbsActv 500;
BA_ "GenSigTimeoutTime_ETC_Ecolife2" SG_ 2565865739 AbsActv 500;
BA_ "GenSigTimeoutTime_ETC_DiwaNXT_MH" SG_ 2565865739 AbsActv 500;
BA_ "GenSigTimeoutTime_ETC_DiwaNXT" SG_ 2565865739 AbsActv 500;
BA_ "GenSigTimeoutTime_DICO" SG_ 2565865739 AbsActv 500;
BA_ "GenSigTimeoutTime_BCM_NBM" SG_ 2565865739 AbsActv 500;
BA_ "GenSigTimeoutTime_ADCU" SG_ 2565865739 AbsActv 500;
BA_ "CI_SigName" SG_ 2565865739 AbsActv "Anti-Lock Braking (ABS) Active";
BA_ "CI_SigId" SG_ 2565865739 AbsActv 233;
BA_ "CI_ParId" SG_ 2565865739 AbsActv "563";
BA_ "SigType" SG_ 2565865739 AsrBrkCtrlActv 4;
BA_ "SPN" SG_ 2565865739 AsrBrkCtrlActv 562;
BA_ "GenSigTimeoutTime_VMU" SG_ 2565865739 AsrBrkCtrlActv 500;
BA_ "GenSigTimeoutTime_VCU" SG_ 2565865739 AsrBrkCtrlActv 500;
BA_ "GenSigTimeoutTime_VCM" SG_ 2565865739 AsrBrkCtrlActv 500;
BA_ "GenSigTimeoutTime_SGW" SG_ 2565865739 AsrBrkCtrlActv 500;
BA_ "GenSigTimeoutTime_PCM" SG_ 2565865739 AsrBrkCtrlActv 500;
BA_ "GenSigTimeoutTime_INVEM1_ELFA3" SG_ 2565865739 AsrBrkCtrlActv 500;
BA_ "GenSigTimeoutTime_IC_MulticS" SG_ 2565865739 AsrBrkCtrlActv 500;
BA_ "GenSigTimeoutTime_IC_MulticII" SG_ 2565865739 AsrBrkCtrlActv 500;
BA_ "GenSigTimeoutTime_ETC_Ecolife2" SG_ 2565865739 AsrBrkCtrlActv 500;
BA_ "GenSigTimeoutTime_ETC_DiwaNXT_MH" SG_ 2565865739 AsrBrkCtrlActv 500;
BA_ "GenSigTimeoutTime_ETC_DiwaNXT" SG_ 2565865739 AsrBrkCtrlActv 500;
BA_ "GenSigTimeoutTime_DICO" SG_ 2565865739 AsrBrkCtrlActv 500;
BA_ "GenSigTimeoutTime_ADCU" SG_ 2565865739 AsrBrkCtrlActv 500;
BA_ "CI_SigName" SG_ 2565865739 AsrBrkCtrlActv "ASR Brake Control Active";
BA_ "CI_SigId" SG_ 2565865739 AsrBrkCtrlActv 232;
BA_ "CI_ParId" SG_ 2565865739 AsrBrkCtrlActv "562";
BA_ "SigType" SG_ 2565865739 AsrEngCtrlActv 4;
BA_ "SPN" SG_ 2565865739 AsrEngCtrlActv 561;
BA_ "GenSigTimeoutTime_VMU" SG_ 2565865739 AsrEngCtrlActv 500;
BA_ "GenSigTimeoutTime_VCU" SG_ 2565865739 AsrEngCtrlActv 500;
BA_ "GenSigTimeoutTime_VCM" SG_ 2565865739 AsrEngCtrlActv 500;
BA_ "GenSigTimeoutTime_SGW" SG_ 2565865739 AsrEngCtrlActv 500;
BA_ "GenSigTimeoutTime_PCM" SG_ 2565865739 AsrEngCtrlActv 500;
BA_ "GenSigTimeoutTime_INVEM1_ELFA3" SG_ 2565865739 AsrEngCtrlActv 500;
BA_ "GenSigTimeoutTime_IC_MulticS" SG_ 2565865739 AsrEngCtrlActv 500;
BA_ "GenSigTimeoutTime_IC_MulticII" SG_ 2565865739 AsrEngCtrlActv 500;
BA_ "GenSigTimeoutTime_ETC_Ecolife2" SG_ 2565865739 AsrEngCtrlActv 500;
BA_ "GenSigTimeoutTime_ETC_DiwaNXT_MH" SG_ 2565865739 AsrEngCtrlActv 500;
BA_ "GenSigTimeoutTime_ETC_DiwaNXT" SG_ 2565865739 AsrEngCtrlActv 500;
BA_ "GenSigTimeoutTime_DICO" SG_ 2565865739 AsrEngCtrlActv 500;
BA_ "GenSigTimeoutTime_ADCU" SG_ 2565865739 AsrEngCtrlActv 500;
BA_ "CI_SigName" SG_ 2565865739 AsrEngCtrlActv "ASR Engine Control Active";
BA_ "CI_SigId" SG_ 2565865739 AsrEngCtrlActv 231;
BA_ "CI_ParId" SG_ 2565865739 AsrEngCtrlActv "561";
BA_ "SigType" SG_ 2566831883 RelSpeedRa2R 1;
BA_ "SPN" SG_ 2566831883 RelSpeedRa2R 910;
BA_ "GenSigTimeoutTime_VMU" SG_ 2566831883 RelSpeedRa2R 500;
BA_ "GenSigTimeoutTime_VCU" SG_ 2566831883 RelSpeedRa2R 500;
BA_ "GenSigTimeoutTime_VCM" SG_ 2566831883 RelSpeedRa2R 500;
BA_ "GenSigTimeoutTime_SGW" SG_ 2566831883 RelSpeedRa2R 500;
BA_ "GenSigTimeoutTime_PCM" SG_ 2566831883 RelSpeedRa2R 500;
BA_ "GenSigTimeoutTime_MPPxPTFE2" SG_ 2566831883 RelSpeedRa2R 500;
BA_ "GenSigTimeoutTime_INVEM1_ELFA3" SG_ 2566831883 RelSpeedRa2R 500;
BA_ "GenSigTimeoutTime_FMS_FMS5" SG_ 2566831883 RelSpeedRa2R 500;
BA_ "GenSigTimeoutTime_FMS_FMS4" SG_ 2566831883 RelSpeedRa2R 500;
BA_ "GenSigTimeoutTime_BCM_NBM" SG_ 2566831883 RelSpeedRa2R 500;
BA_ "GenSigStartValue" SG_ 2566831883 RelSpeedRa2R 125;
BA_ "CI_SigName" SG_ 2566831883 RelSpeedRa2R "Relative Speed; Rear Axle #2, Right Wheel";
BA_ "CI_SigId" SG_ 2566831883 RelSpeedRa2R 273;
BA_ "CI_ParId" SG_ 2566831883 RelSpeedRa2R "910";
BA_ "SigType" SG_ 2566831883 RelSpeedRa2L 1;
BA_ "SPN" SG_ 2566831883 RelSpeedRa2L 909;
BA_ "GenSigTimeoutTime_VMU" SG_ 2566831883 RelSpeedRa2L 500;
BA_ "GenSigTimeoutTime_VCU" SG_ 2566831883 RelSpeedRa2L 500;
BA_ "GenSigTimeoutTime_VCM" SG_ 2566831883 RelSpeedRa2L 500;
BA_ "GenSigTimeoutTime_SGW" SG_ 2566831883 RelSpeedRa2L 500;
BA_ "GenSigTimeoutTime_PCM" SG_ 2566831883 RelSpeedRa2L 500;
BA_ "GenSigTimeoutTime_MPPxPTFE2" SG_ 2566831883 RelSpeedRa2L 500;
BA_ "GenSigTimeoutTime_INVEM1_ELFA3" SG_ 2566831883 RelSpeedRa2L 500;
BA_ "GenSigTimeoutTime_FMS_FMS5" SG_ 2566831883 RelSpeedRa2L 500;
BA_ "GenSigTimeoutTime_FMS_FMS4" SG_ 2566831883 RelSpeedRa2L 500;
BA_ "GenSigTimeoutTime_BCM_NBM" SG_ 2566831883 RelSpeedRa2L 500;
BA_ "GenSigStartValue" SG_ 2566831883 RelSpeedRa2L 125;
BA_ "CI_SigName" SG_ 2566831883 RelSpeedRa2L "Relative Speed; Rear Axle #2, Left Wheel";
BA_ "CI_SigId" SG_ 2566831883 RelSpeedRa2L 272;
BA_ "CI_ParId" SG_ 2566831883 RelSpeedRa2L "909";
BA_ "SigType" SG_ 2566831883 RelSpeedRa1R 1;
BA_ "SPN" SG_ 2566831883 RelSpeedRa1R 908;
BA_ "GenSigTimeoutTime_VMU" SG_ 2566831883 RelSpeedRa1R 500;
BA_ "GenSigTimeoutTime_VCU" SG_ 2566831883 RelSpeedRa1R 500;
BA_ "GenSigTimeoutTime_VCM" SG_ 2566831883 RelSpeedRa1R 500;
BA_ "GenSigTimeoutTime_SGW" SG_ 2566831883 RelSpeedRa1R 500;
BA_ "GenSigTimeoutTime_PCM" SG_ 2566831883 RelSpeedRa1R 500;
BA_ "GenSigTimeoutTime_MPPxPTFE2" SG_ 2566831883 RelSpeedRa1R 500;
BA_ "GenSigTimeoutTime_INVEM1_ELFA3" SG_ 2566831883 RelSpeedRa1R 500;
BA_ "GenSigTimeoutTime_FMS_FMS5" SG_ 2566831883 RelSpeedRa1R 500;
BA_ "GenSigTimeoutTime_FMS_FMS4" SG_ 2566831883 RelSpeedRa1R 500;
BA_ "GenSigTimeoutTime_BCM_NBM" SG_ 2566831883 RelSpeedRa1R 500;
BA_ "GenSigTimeoutTime_ADCU" SG_ 2566831883 RelSpeedRa1R 500;
BA_ "GenSigStartValue" SG_ 2566831883 RelSpeedRa1R 125;
BA_ "CI_SigName" SG_ 2566831883 RelSpeedRa1R "Relative Speed; Rear Axle #1, Right Wheel";
BA_ "CI_SigId" SG_ 2566831883 RelSpeedRa1R 271;
BA_ "CI_ParId" SG_ 2566831883 RelSpeedRa1R "908";
BA_ "SigType" SG_ 2566831883 RelSpeedRa1L 1;
BA_ "SPN" SG_ 2566831883 RelSpeedRa1L 907;
BA_ "GenSigTimeoutTime_VMU" SG_ 2566831883 RelSpeedRa1L 500;
BA_ "GenSigTimeoutTime_VCU" SG_ 2566831883 RelSpeedRa1L 500;
BA_ "GenSigTimeoutTime_VCM" SG_ 2566831883 RelSpeedRa1L 500;
BA_ "GenSigTimeoutTime_SGW" SG_ 2566831883 RelSpeedRa1L 500;
BA_ "GenSigTimeoutTime_PCM" SG_ 2566831883 RelSpeedRa1L 500;
BA_ "GenSigTimeoutTime_MPPxPTFE2" SG_ 2566831883 RelSpeedRa1L 500;
BA_ "GenSigTimeoutTime_INVEM1_ELFA3" SG_ 2566831883 RelSpeedRa1L 500;
BA_ "GenSigTimeoutTime_FMS_FMS5" SG_ 2566831883 RelSpeedRa1L 500;
BA_ "GenSigTimeoutTime_FMS_FMS4" SG_ 2566831883 RelSpeedRa1L 500;
BA_ "GenSigTimeoutTime_BCM_NBM" SG_ 2566831883 RelSpeedRa1L 500;
BA_ "GenSigTimeoutTime_ADCU" SG_ 2566831883 RelSpeedRa1L 500;
BA_ "GenSigStartValue" SG_ 2566831883 RelSpeedRa1L 125;
BA_ "CI_SigName" SG_ 2566831883 RelSpeedRa1L "Relative Speed; Rear Axle #1, Left Wheel";
BA_ "CI_SigId" SG_ 2566831883 RelSpeedRa1L 270;
BA_ "CI_ParId" SG_ 2566831883 RelSpeedRa1L "907";
BA_ "SigType" SG_ 2566831883 RelSpeedFaR 1;
BA_ "SPN" SG_ 2566831883 RelSpeedFaR 906;
BA_ "GenSigTimeoutTime_VMU" SG_ 2566831883 RelSpeedFaR 500;
BA_ "GenSigTimeoutTime_VCU" SG_ 2566831883 RelSpeedFaR 500;
BA_ "GenSigTimeoutTime_VCM" SG_ 2566831883 RelSpeedFaR 500;
BA_ "GenSigTimeoutTime_SGW" SG_ 2566831883 RelSpeedFaR 500;
BA_ "GenSigTimeoutTime_PCM" SG_ 2566831883 RelSpeedFaR 500;
BA_ "GenSigTimeoutTime_MPPxPTFE2" SG_ 2566831883 RelSpeedFaR 500;
BA_ "GenSigTimeoutTime_INVEM1_ELFA3" SG_ 2566831883 RelSpeedFaR 500;
BA_ "GenSigTimeoutTime_FMS_FMS5" SG_ 2566831883 RelSpeedFaR 500;
BA_ "GenSigTimeoutTime_FMS_FMS4" SG_ 2566831883 RelSpeedFaR 500;
BA_ "GenSigTimeoutTime_BCM_NBM" SG_ 2566831883 RelSpeedFaR 500;
BA_ "GenSigTimeoutTime_ADCU" SG_ 2566831883 RelSpeedFaR 500;
BA_ "GenSigStartValue" SG_ 2566831883 RelSpeedFaR 125;
BA_ "CI_SigName" SG_ 2566831883 RelSpeedFaR "Relative Speed; Front Axle, Right Wheel";
BA_ "CI_SigId" SG_ 2566831883 RelSpeedFaR 269;
BA_ "CI_ParId" SG_ 2566831883 RelSpeedFaR "906";
BA_ "SigType" SG_ 2566831883 RelSpeedFaL 1;
BA_ "SPN" SG_ 2566831883 RelSpeedFaL 905;
BA_ "GenSigTimeoutTime_VMU" SG_ 2566831883 RelSpeedFaL 500;
BA_ "GenSigTimeoutTime_VCU" SG_ 2566831883 RelSpeedFaL 500;
BA_ "GenSigTimeoutTime_VCM" SG_ 2566831883 RelSpeedFaL 500;
BA_ "GenSigTimeoutTime_SGW" SG_ 2566831883 RelSpeedFaL 500;
BA_ "GenSigTimeoutTime_PCM" SG_ 2566831883 RelSpeedFaL 500;
BA_ "GenSigTimeoutTime_MPPxPTFE2" SG_ 2566831883 RelSpeedFaL 500;
BA_ "GenSigTimeoutTime_INVEM1_ELFA3" SG_ 2566831883 RelSpeedFaL 500;
BA_ "GenSigTimeoutTime_FMS_FMS5" SG_ 2566831883 RelSpeedFaL 500;
BA_ "GenSigTimeoutTime_FMS_FMS4" SG_ 2566831883 RelSpeedFaL 500;
BA_ "GenSigTimeoutTime_BCM_NBM" SG_ 2566831883 RelSpeedFaL 500;
BA_ "GenSigTimeoutTime_ADCU" SG_ 2566831883 RelSpeedFaL 500;
BA_ "GenSigStartValue" SG_ 2566831883 RelSpeedFaL 125;
BA_ "CI_SigName" SG_ 2566831883 RelSpeedFaL "Relative Speed; Front Axle, Left Wheel";
BA_ "CI_SigId" SG_ 2566831883 RelSpeedFaL 268;
BA_ "CI_ParId" SG_ 2566831883 RelSpeedFaL "905";
BA_ "SigType" SG_ 2566831883 FaSpeed 1;
BA_ "SPN" SG_ 2566831883 FaSpeed 904;
BA_ "GenSigTimeoutTime_VMU" SG_ 2566831883 FaSpeed 500;
BA_ "GenSigTimeoutTime_VCU" SG_ 2566831883 FaSpeed 500;
BA_ "GenSigTimeoutTime_VCM" SG_ 2566831883 FaSpeed 500;
BA_ "GenSigTimeoutTime_Tacho_TSU" SG_ 2566831883 FaSpeed 500;
BA_ "GenSigTimeoutTime_Tacho_MTCO" SG_ 2566831883 FaSpeed 500;
BA_ "GenSigTimeoutTime_Tacho_DTCO" SG_ 2566831883 FaSpeed 500;
BA_ "GenSigTimeoutTime_TASM_ETS" SG_ 2566831883 FaSpeed 500;
BA_ "GenSigTimeoutTime_SGW" SG_ 2566831883 FaSpeed 500;
BA_ "GenSigTimeoutTime_PCM" SG_ 2566831883 FaSpeed 500;
BA_ "GenSigTimeoutTime_MPPxPTFE2" SG_ 2566831883 FaSpeed 500;
BA_ "GenSigTimeoutTime_INVEM1_ELFA3" SG_ 2566831883 FaSpeed 500;
BA_ "GenSigTimeoutTime_FMS_FMS5" SG_ 2566831883 FaSpeed 500;
BA_ "GenSigTimeoutTime_FMS_FMS4" SG_ 2566831883 FaSpeed 500;
BA_ "GenSigTimeoutTime_DMS" SG_ 2566831883 FaSpeed 500;
BA_ "GenSigTimeoutTime_BCM_NBM" SG_ 2566831883 FaSpeed 500;
BA_ "GenSigTimeoutTime_ASM_ELC5_Fr" SG_ 2566831883 FaSpeed 500;
BA_ "GenSigTimeoutTime_ADCU" SG_ 2566831883 FaSpeed 500;
BA_ "GenSigTimeoutTime_ACU" SG_ 2566831883 FaSpeed 500;
BA_ "CI_SigName" SG_ 2566831883 FaSpeed "Front Axle Speed";
BA_ "CI_SigId" SG_ 2566831883 FaSpeed 267;
BA_ "CI_ParId" SG_ 2566831883 FaSpeed "904";
BA_ "SigType" SG_ 2633935883 BrkLinRemRa3R 1;
BA_ "SPN" SG_ 2633935883 BrkLinRemRa3R 1106;
BA_ "CI_SigName" SG_ 2633935883 BrkLinRemRa3R "Brake Lining Remaining, Rear Axle #3, Right Wheel";
BA_ "CI_SigId" SG_ 2633935883 BrkLinRemRa3R 300;
BA_ "CI_ParId" SG_ 2633935883 BrkLinRemRa3R "1106";
BA_ "SigType" SG_ 2633935883 BrkLinRemRa3L 1;
BA_ "SPN" SG_ 2633935883 BrkLinRemRa3L 1105;
BA_ "CI_SigName" SG_ 2633935883 BrkLinRemRa3L "Brake Lining Remaining, Rear Axle #3, Left Wheel";
BA_ "CI_SigId" SG_ 2633935883 BrkLinRemRa3L 299;
BA_ "CI_ParId" SG_ 2633935883 BrkLinRemRa3L "1105";
BA_ "SigType" SG_ 2633935883 BrkLinRemRa2R 1;
BA_ "SPN" SG_ 2633935883 BrkLinRemRa2R 1104;
BA_ "GenSigTimeoutTime_SGW" SG_ 2633935883 BrkLinRemRa2R 25000;
BA_ "GenSigTimeoutTime_PCM" SG_ 2633935883 BrkLinRemRa2R 25000;
BA_ "GenSigTimeoutTime_MPPxPTFE2" SG_ 2633935883 BrkLinRemRa2R 25000;
BA_ "GenSigTimeoutTime_IC_MulticS" SG_ 2633935883 BrkLinRemRa2R 25000;
BA_ "GenSigTimeoutTime_IC_MulticII" SG_ 2633935883 BrkLinRemRa2R 25000;
BA_ "GenSigTimeoutTime_FMS_FMS5" SG_ 2633935883 BrkLinRemRa2R 25000;
BA_ "GenSigTimeoutTime_FMS_FMS4" SG_ 2633935883 BrkLinRemRa2R 25000;
BA_ "CI_SigName" SG_ 2633935883 BrkLinRemRa2R "Brake Lining Remaining, Rear Axle #2, Right Wheel";
BA_ "CI_SigId" SG_ 2633935883 BrkLinRemRa2R 298;
BA_ "CI_ParId" SG_ 2633935883 BrkLinRemRa2R "1104";
BA_ "SigType" SG_ 2633935883 BrkLinRemRa2L 1;
BA_ "SPN" SG_ 2633935883 BrkLinRemRa2L 1103;
BA_ "GenSigTimeoutTime_SGW" SG_ 2633935883 BrkLinRemRa2L 25000;
BA_ "GenSigTimeoutTime_PCM" SG_ 2633935883 BrkLinRemRa2L 25000;
BA_ "GenSigTimeoutTime_MPPxPTFE2" SG_ 2633935883 BrkLinRemRa2L 25000;
BA_ "GenSigTimeoutTime_IC_MulticS" SG_ 2633935883 BrkLinRemRa2L 25000;
BA_ "GenSigTimeoutTime_IC_MulticII" SG_ 2633935883 BrkLinRemRa2L 25000;
BA_ "GenSigTimeoutTime_FMS_FMS5" SG_ 2633935883 BrkLinRemRa2L 25000;
BA_ "GenSigTimeoutTime_FMS_FMS4" SG_ 2633935883 BrkLinRemRa2L 25000;
BA_ "CI_SigName" SG_ 2633935883 BrkLinRemRa2L "Brake Lining Remaining, Rear Axle #2, Left Wheel";
BA_ "CI_SigId" SG_ 2633935883 BrkLinRemRa2L 297;
BA_ "CI_ParId" SG_ 2633935883 BrkLinRemRa2L "1103";
BA_ "SigType" SG_ 2633935883 BrkLinRemRa1R 1;
BA_ "SPN" SG_ 2633935883 BrkLinRemRa1R 1102;
BA_ "GenSigTimeoutTime_SGW" SG_ 2633935883 BrkLinRemRa1R 25000;
BA_ "GenSigTimeoutTime_PCM" SG_ 2633935883 BrkLinRemRa1R 25000;
BA_ "GenSigTimeoutTime_MPPxPTFE2" SG_ 2633935883 BrkLinRemRa1R 25000;
BA_ "GenSigTimeoutTime_IC_MulticS" SG_ 2633935883 BrkLinRemRa1R 25000;
BA_ "GenSigTimeoutTime_IC_MulticII" SG_ 2633935883 BrkLinRemRa1R 25000;
BA_ "GenSigTimeoutTime_FMS_FMS5" SG_ 2633935883 BrkLinRemRa1R 25000;
BA_ "GenSigTimeoutTime_FMS_FMS4" SG_ 2633935883 BrkLinRemRa1R 25000;
BA_ "CI_SigName" SG_ 2633935883 BrkLinRemRa1R "Brake Lining Remaining, Rear Axle #1, Right Wheel";
BA_ "CI_SigId" SG_ 2633935883 BrkLinRemRa1R 296;
BA_ "CI_ParId" SG_ 2633935883 BrkLinRemRa1R "1102";
BA_ "SigType" SG_ 2633935883 BrkLinRemRa1L 1;
BA_ "SPN" SG_ 2633935883 BrkLinRemRa1L 1101;
BA_ "GenSigTimeoutTime_SGW" SG_ 2633935883 BrkLinRemRa1L 25000;
BA_ "GenSigTimeoutTime_PCM" SG_ 2633935883 BrkLinRemRa1L 25000;
BA_ "GenSigTimeoutTime_MPPxPTFE2" SG_ 2633935883 BrkLinRemRa1L 25000;
BA_ "GenSigTimeoutTime_IC_MulticS" SG_ 2633935883 BrkLinRemRa1L 25000;
BA_ "GenSigTimeoutTime_IC_MulticII" SG_ 2633935883 BrkLinRemRa1L 25000;
BA_ "GenSigTimeoutTime_FMS_FMS5" SG_ 2633935883 BrkLinRemRa1L 25000;
BA_ "GenSigTimeoutTime_FMS_FMS4" SG_ 2633935883 BrkLinRemRa1L 25000;
BA_ "CI_SigName" SG_ 2633935883 BrkLinRemRa1L "Brake Lining Remaining, Rear Axle #1, Left Wheel";
BA_ "CI_SigId" SG_ 2633935883 BrkLinRemRa1L 295;
BA_ "CI_ParId" SG_ 2633935883 BrkLinRemRa1L "1101";
BA_ "SigType" SG_ 2633935883 BrkLinRemFaR 1;
BA_ "SPN" SG_ 2633935883 BrkLinRemFaR 1100;
BA_ "GenSigTimeoutTime_SGW" SG_ 2633935883 BrkLinRemFaR 25000;
BA_ "GenSigTimeoutTime_PCM" SG_ 2633935883 BrkLinRemFaR 25000;
BA_ "GenSigTimeoutTime_MPPxPTFE2" SG_ 2633935883 BrkLinRemFaR 25000;
BA_ "GenSigTimeoutTime_IC_MulticS" SG_ 2633935883 BrkLinRemFaR 25000;
BA_ "GenSigTimeoutTime_IC_MulticII" SG_ 2633935883 BrkLinRemFaR 25000;
BA_ "GenSigTimeoutTime_FMS_FMS5" SG_ 2633935883 BrkLinRemFaR 25000;
BA_ "GenSigTimeoutTime_FMS_FMS4" SG_ 2633935883 BrkLinRemFaR 25000;
BA_ "CI_SigName" SG_ 2633935883 BrkLinRemFaR "Brake Lining Remaining, Front Axle, Right Wheel";
BA_ "CI_SigId" SG_ 2633935883 BrkLinRemFaR 294;
BA_ "CI_ParId" SG_ 2633935883 BrkLinRemFaR "1100";
BA_ "SigType" SG_ 2633935883 BrkLinRemFaL 1;
BA_ "SPN" SG_ 2633935883 BrkLinRemFaL 1099;
BA_ "GenSigTimeoutTime_SGW" SG_ 2633935883 BrkLinRemFaL 25000;
BA_ "GenSigTimeoutTime_PCM" SG_ 2633935883 BrkLinRemFaL 25000;
BA_ "GenSigTimeoutTime_MPPxPTFE2" SG_ 2633935883 BrkLinRemFaL 25000;
BA_ "GenSigTimeoutTime_IC_MulticS" SG_ 2633935883 BrkLinRemFaL 25000;
BA_ "GenSigTimeoutTime_IC_MulticII" SG_ 2633935883 BrkLinRemFaL 25000;
BA_ "GenSigTimeoutTime_FMS_FMS5" SG_ 2633935883 BrkLinRemFaL 25000;
BA_ "GenSigTimeoutTime_FMS_FMS4" SG_ 2633935883 BrkLinRemFaL 25000;
BA_ "CI_SigName" SG_ 2633935883 BrkLinRemFaL "Brake Lining Remaining, Front Axle, Left Wheel";
BA_ "CI_SigId" SG_ 2633935883 BrkLinRemFaL 293;
BA_ "CI_ParId" SG_ 2633935883 BrkLinRemFaL "1099";
BA_ "SPN" SG_ 2566767627 HhMode 2912;
BA_ "GenSigTimeoutTime_VMU" SG_ 2566767627 HhMode 500;
BA_ "GenSigTimeoutTime_VCU" SG_ 2566767627 HhMode 500;
BA_ "GenSigTimeoutTime_SGW" SG_ 2566767627 HhMode 500;
BA_ "GenSigTimeoutTime_PCM" SG_ 2566767627 HhMode 500;
BA_ "GenSigTimeoutTime_IC_MulticS" SG_ 2566767627 HhMode 500;
BA_ "GenSigTimeoutTime_ETC_Ecolife2" SG_ 2566767627 HhMode 500;
BA_ "GenSigTimeoutTime_DICO" SG_ 2566767627 HhMode 500;
BA_ "GenSigTimeoutTime_BCM_NBM" SG_ 2566767627 HhMode 500;
BA_ "CI_SigName" SG_ 2566767627 HhMode "Hill holder mode";
BA_ "CI_SigId" SG_ 2566767627 HhMode 304;
BA_ "CI_ParId" SG_ 2566767627 HhMode "2912";
BA_ "SPN" SG_ 2566767627 HaltBrkMode 2913;
BA_ "GenSigTimeoutTime_VMU" SG_ 2566767627 HaltBrkMode 500;
BA_ "GenSigTimeoutTime_VCU" SG_ 2566767627 HaltBrkMode 500;
BA_ "GenSigTimeoutTime_SGW" SG_ 2566767627 HaltBrkMode 500;
BA_ "GenSigTimeoutTime_PCM" SG_ 2566767627 HaltBrkMode 500;
BA_ "GenSigTimeoutTime_IC_MulticS" SG_ 2566767627 HaltBrkMode 500;
BA_ "GenSigTimeoutTime_ETC_Ecolife2" SG_ 2566767627 HaltBrkMode 500;
BA_ "GenSigTimeoutTime_DICO" SG_ 2566767627 HaltBrkMode 500;
BA_ "GenSigTimeoutTime_BCM_NBM" SG_ 2566767627 HaltBrkMode 500;
BA_ "CI_SigName" SG_ 2566767627 HaltBrkMode "Halt brake mode";
BA_ "CI_SigId" SG_ 2566767627 HaltBrkMode 303;
BA_ "CI_ParId" SG_ 2566767627 HaltBrkMode "2913";
BA_ "SigType" SG_ 2566841088 EngMaxMomOvrSpeedPnt7 1;
BA_ "SPN" SG_ 2566841088 EngMaxMomOvrSpeedPnt7 533;
BA_ "GenSigTimeoutTime_VCM" SG_ 2566841088 EngMaxMomOvrSpeedPnt7 25000;
BA_ "GenSigTimeoutTime_SGW" SG_ 2566841088 EngMaxMomOvrSpeedPnt7 25000;
BA_ "GenSigTimeoutTime_PCM" SG_ 2566841088 EngMaxMomOvrSpeedPnt7 25000;
BA_ "GenSigSendType" SG_ 2566841088 EngMaxMomOvrSpeedPnt7 3;
BA_ "CI_SigName" SG_ 2566841088 EngMaxMomOvrSpeedPnt7 "Engine Maximum Momentary Override Speed, Point 7";
BA_ "CI_SigId" SG_ 2566841088 EngMaxMomOvrSpeedPnt7 979;
BA_ "CI_ParId" SG_ 2566841088 EngMaxMomOvrSpeedPnt7 "533";
BA_ "SigType" SG_ 2566841088 EngRefTrq 1;
BA_ "SPN" SG_ 2566841088 EngRefTrq 544;
BA_ "GenSigTimeoutTime_VCM" SG_ 2566841088 EngRefTrq 25000;
BA_ "GenSigTimeoutTime_SGW" SG_ 2566841088 EngRefTrq 25000;
BA_ "GenSigTimeoutTime_PCM" SG_ 2566841088 EngRefTrq 25000;
BA_ "GenSigTimeoutTime_IC_MulticS" SG_ 2566841088 EngRefTrq 25000;
BA_ "GenSigTimeoutTime_ETC_Ecolife2" SG_ 2566841088 EngRefTrq 25000;
BA_ "GenSigTimeoutTime_ETC_DiwaNXT_MH" SG_ 2566841088 EngRefTrq 25000;
BA_ "GenSigTimeoutTime_ETC_DiwaNXT" SG_ 2566841088 EngRefTrq 25000;
BA_ "GenSigTimeoutTime_BSM_EBS" SG_ 2566841088 EngRefTrq 25000;
BA_ "GenSigTimeoutTime_ADCU" SG_ 2566841088 EngRefTrq 25000;
BA_ "GenSigSendType" SG_ 2566841088 EngRefTrq 3;
BA_ "CI_SigName" SG_ 2566841088 EngRefTrq "Engine Reference Torque";
BA_ "CI_SigId" SG_ 2566841088 EngRefTrq 978;
BA_ "CI_ParId" SG_ 2566841088 EngRefTrq "544";
BA_ "SigType" SG_ 2566841088 EngSpeedAtHighIdlePnt6 1;
BA_ "SPN" SG_ 2566841088 EngSpeedAtHighIdlePnt6 532;
BA_ "GenSigTimeoutTime_VCM" SG_ 2566841088 EngSpeedAtHighIdlePnt6 25000;
BA_ "GenSigTimeoutTime_SGW" SG_ 2566841088 EngSpeedAtHighIdlePnt6 25000;
BA_ "GenSigTimeoutTime_PCM" SG_ 2566841088 EngSpeedAtHighIdlePnt6 25000;
BA_ "GenSigSendType" SG_ 2566841088 EngSpeedAtHighIdlePnt6 3;
BA_ "CI_SigName" SG_ 2566841088 EngSpeedAtHighIdlePnt6 "Engine Speed At High Idle, Point 6";
BA_ "CI_SigId" SG_ 2566841088 EngSpeedAtHighIdlePnt6 976;
BA_ "CI_ParId" SG_ 2566841088 EngSpeedAtHighIdlePnt6 "532";
BA_ "SigType" SG_ 2566841088 EngSpeedAtIdlePnt1 1;
BA_ "SPN" SG_ 2566841088 EngSpeedAtIdlePnt1 188;
BA_ "GenSigTimeoutTime_VCM" SG_ 2566841088 EngSpeedAtIdlePnt1 25000;
BA_ "GenSigTimeoutTime_SGW" SG_ 2566841088 EngSpeedAtIdlePnt1 25000;
BA_ "GenSigTimeoutTime_PCM" SG_ 2566841088 EngSpeedAtIdlePnt1 25000;
BA_ "GenSigTimeoutTime_ETC_DiwaNXT_MH" SG_ 2566841088 EngSpeedAtIdlePnt1 25000;
BA_ "GenSigTimeoutTime_ETC_DiwaNXT" SG_ 2566841088 EngSpeedAtIdlePnt1 25000;
BA_ "GenSigTimeoutTime_ADCU" SG_ 2566841088 EngSpeedAtIdlePnt1 25000;
BA_ "GenSigSendType" SG_ 2566841088 EngSpeedAtIdlePnt1 3;
BA_ "CI_SigName" SG_ 2566841088 EngSpeedAtIdlePnt1 "Engine Speed At Idle, Point 1";
BA_ "CI_SigId" SG_ 2566841088 EngSpeedAtIdlePnt1 966;
BA_ "CI_ParId" SG_ 2566841088 EngSpeedAtIdlePnt1 "188";
BA_ "SigType" SG_ 2566841216 EngRefTrq_FEE380 1;
BA_ "SPN" SG_ 2566841216 EngRefTrq_FEE380 544;
BA_ "GenSigTimeoutTime_VMU" SG_ 2566841216 EngRefTrq_FEE380 10000;
BA_ "GenSigTimeoutTime_VCU" SG_ 2566841216 EngRefTrq_FEE380 10000;
BA_ "GenSigTimeoutTime_SGW" SG_ 2566841216 EngRefTrq_FEE380 10000;
BA_ "GenSigTimeoutTime_PCM" SG_ 2566841216 EngRefTrq_FEE380 10000;
BA_ "GenSigTimeoutTime_IC_MulticS" SG_ 2566841216 EngRefTrq_FEE380 10000;
BA_ "GenSigTimeoutTime_IC_MulticII" SG_ 2566841216 EngRefTrq_FEE380 10000;
BA_ "GenSigTimeoutTime_BSM_EBS" SG_ 2566841216 EngRefTrq_FEE380 10000;
BA_ "GenSigTimeoutTime_ADCU" SG_ 2566841216 EngRefTrq_FEE380 10000;
BA_ "CI_SigName" SG_ 2566841216 EngRefTrq_FEE380 "Engine Reference Torque";
BA_ "CI_SigId" SG_ 2566841216 EngRefTrq_FEE380 1008;
BA_ "CI_ParId" SG_ 2566841216 EngRefTrq_FEE380 "544";
BA_ "SigType" SG_ 2566891081 FccuCombo2Lckpositionvoltage 1;
BA_ "GenSigTimeoutTime_SGW2" SG_ 2566891081 FccuCombo2Lckpositionvoltage 5000;
BA_ "GenSigTimeoutTime_SGW" SG_ 2566891081 FccuCombo2Lckpositionvoltage 5000;
BA_ "GenSigTimeoutTime_PCM" SG_ 2566891081 FccuCombo2Lckpositionvoltage 5000;
BA_ "CI_SigName" SG_ 2566891081 FccuCombo2Lckpositionvoltage "FCCU_Combo2LockPositionVoltage";
BA_ "CI_SigId" SG_ 2566891081 FccuCombo2Lckpositionvoltage 2907;
BA_ "CI_ParId" SG_ 2566891081 FccuCombo2Lckpositionvoltage "IB835";
BA_ "SigType" SG_ 2566891081 FccuCombo2Temp 1;
BA_ "GenSigTimeoutTime_SGW2" SG_ 2566891081 FccuCombo2Temp 5000;
BA_ "GenSigTimeoutTime_SGW" SG_ 2566891081 FccuCombo2Temp 5000;
BA_ "GenSigTimeoutTime_PCM" SG_ 2566891081 FccuCombo2Temp 5000;
BA_ "GenSigStartValue" SG_ 2566891081 FccuCombo2Temp 150;
BA_ "CI_SigName" SG_ 2566891081 FccuCombo2Temp "FCCU_Combo2Temperature";
BA_ "CI_SigId" SG_ 2566891081 FccuCombo2Temp 2906;
BA_ "CI_ParId" SG_ 2566891081 FccuCombo2Temp "IB834";
BA_ "SigType" SG_ 2566891081 FccuWifiantennasignalpower 1;
BA_ "GenSigTimeoutTime_SGW2" SG_ 2566891081 FccuWifiantennasignalpower 5000;
BA_ "GenSigTimeoutTime_SGW" SG_ 2566891081 FccuWifiantennasignalpower 5000;
BA_ "GenSigTimeoutTime_PCM" SG_ 2566891081 FccuWifiantennasignalpower 5000;
BA_ "GenSigStartValue" SG_ 2566891081 FccuWifiantennasignalpower 100;
BA_ "CI_SigName" SG_ 2566891081 FccuWifiantennasignalpower "FCCU_WiFiAntennaSignalPower";
BA_ "CI_SigId" SG_ 2566891081 FccuWifiantennasignalpower 2905;
BA_ "CI_ParId" SG_ 2566891081 FccuWifiantennasignalpower "IB833";
BA_ "SigType" SG_ 2566889801 EvsePresCur 1;
BA_ "GenSigTimeoutTime_VCU" SG_ 2566889801 EvsePresCur 25000;
BA_ "GenSigTimeoutTime_SGW" SG_ 2566889801 EvsePresCur 25000;
BA_ "GenSigTimeoutTime_PCM" SG_ 2566889801 EvsePresCur 25000;
BA_ "GenSigTimeoutTime_MPPxPTFE2" SG_ 2566889801 EvsePresCur 25000;
BA_ "CI_SigName" SG_ 2566889801 EvsePresCur "EVSE Present Current";
BA_ "CI_SigId" SG_ 2566889801 EvsePresCur 4044;
BA_ "CI_ParId" SG_ 2566889801 EvsePresCur "IB556";
BA_ "SigType" SG_ 2566889801 ChgIntrp 4;
BA_ "GenSigTimeoutTime_VCU" SG_ 2566889801 ChgIntrp 25000;
BA_ "GenSigTimeoutTime_SGW" SG_ 2566889801 ChgIntrp 25000;
BA_ "GenSigTimeoutTime_PCM" SG_ 2566889801 ChgIntrp 25000;
BA_ "GenSigTimeoutTime_MPPxPTFE2" SG_ 2566889801 ChgIntrp 25000;
BA_ "CI_SigName" SG_ 2566889801 ChgIntrp "Charge interrupt";
BA_ "CI_SigId" SG_ 2566889801 ChgIntrp 4039;
BA_ "CI_ParId" SG_ 2566889801 ChgIntrp "IB551";
BA_ "SigType" SG_ 2566767966 EcuManName 8;
BA_ "SPN" SG_ 2566767966 EcuManName 4304;
BA_ "GenSigTimeoutTime_SGW2" SG_ 2566767966 EcuManName 5000;
BA_ "GenSigTimeoutTime_SGW" SG_ 2566767966 EcuManName 5000;
BA_ "GenSigTimeoutTime_PCM" SG_ 2566767966 EcuManName 5000;
BA_ "CI_SigName" SG_ 2566767966 EcuManName "ECU Manufacturer Name";
BA_ "CI_SigId" SG_ 2566767966 EcuManName 13534;
BA_ "CI_ParId" SG_ 2566767966 EcuManName "4304";
BA_ "SigType" SG_ 2566767966 EcuLoc 8;
BA_ "SPN" SG_ 2566767966 EcuLoc 2903;
BA_ "GenSigTimeoutTime_SGW2" SG_ 2566767966 EcuLoc 5000;
BA_ "GenSigTimeoutTime_SGW" SG_ 2566767966 EcuLoc 5000;
BA_ "GenSigTimeoutTime_PCM" SG_ 2566767966 EcuLoc 5000;
BA_ "CI_SigName" SG_ 2566767966 EcuLoc "ECU Location";
BA_ "CI_SigId" SG_ 2566767966 EcuLoc 10346;
BA_ "CI_ParId" SG_ 2566767966 EcuLoc "2903";
BA_ "SigType" SG_ 2566767966 EcuSn 8;
BA_ "SPN" SG_ 2566767966 EcuSn 2902;
BA_ "GenSigTimeoutTime_SGW2" SG_ 2566767966 EcuSn 5000;
BA_ "GenSigTimeoutTime_SGW" SG_ 2566767966 EcuSn 5000;
BA_ "GenSigTimeoutTime_PCM" SG_ 2566767966 EcuSn 5000;
BA_ "CI_SigName" SG_ 2566767966 EcuSn "ECU Serial Number";
BA_ "CI_SigId" SG_ 2566767966 EcuSn 10345;
BA_ "CI_ParId" SG_ 2566767966 EcuSn "2902";
BA_ "SigType" SG_ 2566767966 EcuPn 8;
BA_ "SPN" SG_ 2566767966 EcuPn 2901;
BA_ "GenSigTimeoutTime_SGW2" SG_ 2566767966 EcuPn 5000;
BA_ "GenSigTimeoutTime_SGW" SG_ 2566767966 EcuPn 5000;
BA_ "GenSigTimeoutTime_PCM" SG_ 2566767966 EcuPn 5000;
BA_ "CI_SigName" SG_ 2566767966 EcuPn "ECU Part Number";
BA_ "CI_SigId" SG_ 2566767966 EcuPn 10344;
BA_ "CI_ParId" SG_ 2566767966 EcuPn "2901";
BA_ "SigType" SG_ 2566767901 EcuManName_FDC51D 8;
BA_ "SPN" SG_ 2566767901 EcuManName_FDC51D 4304;
BA_ "CI_SigName" SG_ 2566767901 EcuManName_FDC51D "ECU Manufacturer Name";
BA_ "CI_SigId" SG_ 2566767901 EcuManName_FDC51D 10327;
BA_ "CI_ParId" SG_ 2566767901 EcuManName_FDC51D "4304";
BA_ "SigType" SG_ 2566767901 EcuType 8;
BA_ "SPN" SG_ 2566767901 EcuType 2904;
BA_ "CI_SigName" SG_ 2566767901 EcuType "ECU Type";
BA_ "CI_SigId" SG_ 2566767901 EcuType 10326;
BA_ "CI_ParId" SG_ 2566767901 EcuType "2904";
BA_ "SigType" SG_ 2566767901 EcuLoc_FDC51D 8;
BA_ "SPN" SG_ 2566767901 EcuLoc_FDC51D 2903;
BA_ "CI_SigName" SG_ 2566767901 EcuLoc_FDC51D "ECU Location";
BA_ "CI_SigId" SG_ 2566767901 EcuLoc_FDC51D 10325;
BA_ "CI_ParId" SG_ 2566767901 EcuLoc_FDC51D "2903";
BA_ "SigType" SG_ 2566767901 EcuSn_FDC51D 8;
BA_ "SPN" SG_ 2566767901 EcuSn_FDC51D 2902;
BA_ "CI_SigName" SG_ 2566767901 EcuSn_FDC51D "ECU Serial Number";
BA_ "CI_SigId" SG_ 2566767901 EcuSn_FDC51D 10324;
BA_ "CI_ParId" SG_ 2566767901 EcuSn_FDC51D "2902";
BA_ "SigType" SG_ 2566767901 EcuPn_FDC51D 8;
BA_ "SPN" SG_ 2566767901 EcuPn_FDC51D 2901;
BA_ "CI_SigName" SG_ 2566767901 EcuPn_FDC51D "ECU Part Number";
BA_ "CI_SigId" SG_ 2566767901 EcuPn_FDC51D 10323;
BA_ "CI_ParId" SG_ 2566767901 EcuPn_FDC51D "2901";
BA_ "SigType" SG_ 2566849280 EngOilTempHigh 4;
BA_ "GenSigTimeoutTime_SGW" SG_ 2566849280 EngOilTempHigh 500;
BA_ "GenSigTimeoutTime_PCM" SG_ 2566849280 EngOilTempHigh 500;
BA_ "GenSigTimeoutTime_IC_MulticS" SG_ 2566849280 EngOilTempHigh 500;
BA_ "GenSigTimeoutTime_FMS_FMS5" SG_ 2566849280 EngOilTempHigh 500;
BA_ "GenSigTimeoutTime_FMS_FMS4" SG_ 2566849280 EngOilTempHigh 500;
BA_ "CI_SigName" SG_ 2566849280 EngOilTempHigh "Engine Oil Temperature High";
BA_ "CI_SigId" SG_ 2566849280 EngOilTempHigh 4068;
BA_ "CI_ParId" SG_ 2566849280 EngOilTempHigh "I081";
BA_ "SigType" SG_ 2566849280 EconMode 4;
BA_ "GenSigTimeoutTime_SGW" SG_ 2566849280 EconMode 500;
BA_ "GenSigTimeoutTime_PCM" SG_ 2566849280 EconMode 500;
BA_ "GenSigTimeoutTime_IC_MulticS" SG_ 2566849280 EconMode 500;
BA_ "GenSigTimeoutTime_FMS_FMS5" SG_ 2566849280 EconMode 500;
BA_ "GenSigTimeoutTime_FMS_FMS4" SG_ 2566849280 EconMode 500;
BA_ "CI_SigName" SG_ 2566849280 EconMode "Economy Mode";
BA_ "CI_SigId" SG_ 2566849280 EconMode 4066;
BA_ "CI_ParId" SG_ 2566849280 EconMode "IS656";
BA_ "SigType" SG_ 2566849280 EngOilPrsLow 4;
BA_ "GenSigTimeoutTime_SGW" SG_ 2566849280 EngOilPrsLow 500;
BA_ "GenSigTimeoutTime_PCM" SG_ 2566849280 EngOilPrsLow 500;
BA_ "GenSigTimeoutTime_IC_MulticS" SG_ 2566849280 EngOilPrsLow 500;
BA_ "GenSigTimeoutTime_FMS_FMS5" SG_ 2566849280 EngOilPrsLow 500;
BA_ "GenSigTimeoutTime_FMS_FMS4" SG_ 2566849280 EngOilPrsLow 500;
BA_ "GenSigTimeoutTime_BCM_NBM" SG_ 2566849280 EngOilPrsLow 500;
BA_ "CI_SigName" SG_ 2566849280 EngOilPrsLow "Engine Oil Pressure Low";
BA_ "CI_SigId" SG_ 2566849280 EngOilPrsLow 4065;
BA_ "CI_ParId" SG_ 2566849280 EngOilPrsLow "I022";
BA_ "SigType" SG_ 2566849280 CabTilted 4;
BA_ "GenSigTimeoutTime_SGW" SG_ 2566849280 CabTilted 500;
BA_ "GenSigTimeoutTime_PCM" SG_ 2566849280 CabTilted 500;
BA_ "GenSigTimeoutTime_IC_MulticS" SG_ 2566849280 CabTilted 500;
BA_ "GenSigTimeoutTime_FMS_FMS5" SG_ 2566849280 CabTilted 500;
BA_ "GenSigTimeoutTime_FMS_FMS4" SG_ 2566849280 CabTilted 500;
BA_ "GenSigTimeoutTime_BCM_NBM" SG_ 2566849280 CabTilted 500;
BA_ "CI_SigName" SG_ 2566849280 CabTilted "Cabin Tilted";
BA_ "CI_SigId" SG_ 2566849280 CabTilted 4061;
BA_ "CI_ParId" SG_ 2566849280 CabTilted "I028";
BA_ "SigType" SG_ 2566849280 MaxVslSetp 1;
BA_ "GenSigTimeoutTime_SGW" SG_ 2566849280 MaxVslSetp 500;
BA_ "GenSigTimeoutTime_PCM" SG_ 2566849280 MaxVslSetp 500;
BA_ "GenSigTimeoutTime_IC_MulticS" SG_ 2566849280 MaxVslSetp 500;
BA_ "GenSigTimeoutTime_FMS_FMS5" SG_ 2566849280 MaxVslSetp 500;
BA_ "GenSigTimeoutTime_FMS_FMS4" SG_ 2566849280 MaxVslSetp 500;
BA_ "CI_SigName" SG_ 2566849280 MaxVslSetp "Maximum Vehicle Speed Limit Setpoint";
BA_ "CI_SigId" SG_ 2566849280 MaxVslSetp 4056;
BA_ "CI_ParId" SG_ 2566849280 MaxVslSetp "I025";
BA_ "GenSigTimeoutTime_SGW" SG_ 2566849280 EngOverTemp 500;
BA_ "GenSigTimeoutTime_PCM" SG_ 2566849280 EngOverTemp 500;
BA_ "GenSigTimeoutTime_IC_MulticS" SG_ 2566849280 EngOverTemp 500;
BA_ "GenSigTimeoutTime_FMS_FMS5" SG_ 2566849280 EngOverTemp 500;
BA_ "GenSigTimeoutTime_FMS_FMS4" SG_ 2566849280 EngOverTemp 500;
BA_ "CI_SigName" SG_ 2566849280 EngOverTemp "Engine Over Temperature";
BA_ "CI_SigId" SG_ 2566849280 EngOverTemp 4055;
BA_ "CI_ParId" SG_ 2566849280 EngOverTemp "I254";
BA_ "SigType" SG_ 2364539904 EngDemPcTrq 1;
BA_ "SPN" SG_ 2364539904 EngDemPcTrq 2432;
BA_ "GenSigTimeoutTime_VCM" SG_ 2364539904 EngDemPcTrq 500;
BA_ "GenSigTimeoutTime_SGW2" SG_ 2364539904 EngDemPcTrq 500;
BA_ "GenSigTimeoutTime_SGW" SG_ 2364539904 EngDemPcTrq 500;
BA_ "GenSigTimeoutTime_PCM" SG_ 2364539904 EngDemPcTrq 500;
BA_ "GenSigStartValue" SG_ 2364539904 EngDemPcTrq 125;
BA_ "CI_SigName" SG_ 2364539904 EngDemPcTrq "Engine Demand - Percent Torque";
BA_ "CI_SigId" SG_ 2364539904 EngDemPcTrq 844;
BA_ "CI_ParId" SG_ 2364539904 EngDemPcTrq "2432";
BA_ "SigType" SG_ 2364539904 EngSpeed 1;
BA_ "SPN" SG_ 2364539904 EngSpeed 190;
BA_ "GenSigTimeoutTime_VCM" SG_ 2364539904 EngSpeed 500;
BA_ "GenSigTimeoutTime_Tacho_MTCO" SG_ 2364539904 EngSpeed 500;
BA_ "GenSigTimeoutTime_Tacho_DTCO" SG_ 2364539904 EngSpeed 500;
BA_ "GenSigTimeoutTime_TPMS" SG_ 2364539904 EngSpeed 500;
BA_ "GenSigTimeoutTime_TASM_ETS" SG_ 2364539904 EngSpeed 500;
BA_ "GenSigTimeoutTime_SGW2" SG_ 2364539904 EngSpeed 500;
BA_ "GenSigTimeoutTime_SGW" SG_ 2364539904 EngSpeed 500;
BA_ "GenSigTimeoutTime_SAS" SG_ 2364539904 EngSpeed 500;
BA_ "GenSigTimeoutTime_RM_IRCS" SG_ 2364539904 EngSpeed 500;
BA_ "GenSigTimeoutTime_RM_INTD" SG_ 2364539904 EngSpeed 500;
BA_ "GenSigTimeoutTime_PCM" SG_ 2364539904 EngSpeed 500;
BA_ "GenSigTimeoutTime_IC_MulticS" SG_ 2364539904 EngSpeed 500;
BA_ "GenSigTimeoutTime_FMS_FMS5" SG_ 2364539904 EngSpeed 500;
BA_ "GenSigTimeoutTime_FMS_FMS4" SG_ 2364539904 EngSpeed 500;
BA_ "GenSigTimeoutTime_ETC_Ecolife2" SG_ 2364539904 EngSpeed 500;
BA_ "GenSigTimeoutTime_ETC_DiwaNXT_MH" SG_ 2364539904 EngSpeed 500;
BA_ "GenSigTimeoutTime_DMS" SG_ 2364539904 EngSpeed 500;
BA_ "GenSigTimeoutTime_BSM_EBS" SG_ 2364539904 EngSpeed 500;
BA_ "GenSigTimeoutTime_BCM_NBM" SG_ 2364539904 EngSpeed 500;
BA_ "GenSigTimeoutTime_Av2HP" SG_ 2364539904 EngSpeed 500;
BA_ "GenSigTimeoutTime_ADCU" SG_ 2364539904 EngSpeed 500;
BA_ "CI_SigName" SG_ 2364539904 EngSpeed "Engine Speed";
BA_ "CI_SigId" SG_ 2364539904 EngSpeed 841;
BA_ "CI_ParId" SG_ 2364539904 EngSpeed "190";
BA_ "SigType" SG_ 2364539904 ActEngPcTrq 1;
BA_ "SPN" SG_ 2364539904 ActEngPcTrq 513;
BA_ "GenSigTimeoutTime_VCM" SG_ 2364539904 ActEngPcTrq 500;
BA_ "GenSigTimeoutTime_SGW2" SG_ 2364539904 ActEngPcTrq 500;
BA_ "GenSigTimeoutTime_SGW" SG_ 2364539904 ActEngPcTrq 500;
BA_ "GenSigTimeoutTime_PCM" SG_ 2364539904 ActEngPcTrq 500;
BA_ "GenSigTimeoutTime_IC_MulticS" SG_ 2364539904 ActEngPcTrq 500;
BA_ "GenSigTimeoutTime_FMS_FMS5" SG_ 2364539904 ActEngPcTrq 500;
BA_ "GenSigTimeoutTime_FMS_FMS4" SG_ 2364539904 ActEngPcTrq 500;
BA_ "GenSigTimeoutTime_ETC_Ecolife2" SG_ 2364539904 ActEngPcTrq 500;
BA_ "GenSigTimeoutTime_BSM_EBS" SG_ 2364539904 ActEngPcTrq 500;
BA_ "GenSigTimeoutTime_BCM_NBM" SG_ 2364539904 ActEngPcTrq 500;
BA_ "GenSigTimeoutTime_ADCU" SG_ 2364539904 ActEngPcTrq 500;
BA_ "GenSigStartValue" SG_ 2364539904 ActEngPcTrq 125;
BA_ "CI_SigName" SG_ 2364539904 ActEngPcTrq "Actual Engine - Percent Torque";
BA_ "CI_SigId" SG_ 2364539904 ActEngPcTrq 840;
BA_ "CI_ParId" SG_ 2364539904 ActEngPcTrq "513";
BA_ "SPN" SG_ 2364539904 EngTrqMode 899;
BA_ "GenSigTimeoutTime_VCM" SG_ 2364539904 EngTrqMode 500;
BA_ "GenSigTimeoutTime_SGW2" SG_ 2364539904 EngTrqMode 500;
BA_ "GenSigTimeoutTime_SGW" SG_ 2364539904 EngTrqMode 500;
BA_ "GenSigTimeoutTime_PCM" SG_ 2364539904 EngTrqMode 500;
BA_ "GenSigTimeoutTime_ETC_Ecolife2" SG_ 2364539904 EngTrqMode 500;
BA_ "GenSigTimeoutTime_DMS" SG_ 2364539904 EngTrqMode 500;
BA_ "GenSigTimeoutTime_BSM_EBS" SG_ 2364539904 EngTrqMode 500;
BA_ "GenSigTimeoutTime_ADCU" SG_ 2364539904 EngTrqMode 500;
BA_ "CI_SigName" SG_ 2364539904 EngTrqMode "Engine Torque Mode";
BA_ "CI_SigId" SG_ 2364539904 EngTrqMode 837;
BA_ "CI_ParId" SG_ 2364539904 EngTrqMode "899";
BA_ "SigType" SG_ 2364540032 EngSpeed_00480 1;
BA_ "SPN" SG_ 2364540032 EngSpeed_00480 190;
BA_ "GenSigTimeoutTime_VMU" SG_ 2364540032 EngSpeed_00480 500;
BA_ "GenSigTimeoutTime_VCU" SG_ 2364540032 EngSpeed_00480 500;
BA_ "GenSigTimeoutTime_TPMS" SG_ 2364540032 EngSpeed_00480 500;
BA_ "GenSigTimeoutTime_SGW" SG_ 2364540032 EngSpeed_00480 500;
BA_ "GenSigTimeoutTime_PCM" SG_ 2364540032 EngSpeed_00480 500;
BA_ "GenSigTimeoutTime_IC_MulticS" SG_ 2364540032 EngSpeed_00480 500;
BA_ "GenSigTimeoutTime_IC_MulticII" SG_ 2364540032 EngSpeed_00480 500;
BA_ "GenSigTimeoutTime_BSM_EBS" SG_ 2364540032 EngSpeed_00480 500;
BA_ "GenSigTimeoutTime_ADCU" SG_ 2364540032 EngSpeed_00480 500;
BA_ "CI_SigName" SG_ 2364540032 EngSpeed_00480 "Engine Speed";
BA_ "CI_SigId" SG_ 2364540032 EngSpeed_00480 859;
BA_ "CI_ParId" SG_ 2364540032 EngSpeed_00480 "190";
BA_ "SigType" SG_ 2364540032 ActEngPcTrq_00480 1;
BA_ "SPN" SG_ 2364540032 ActEngPcTrq_00480 513;
BA_ "GenSigTimeoutTime_VMU" SG_ 2364540032 ActEngPcTrq_00480 500;
BA_ "GenSigTimeoutTime_VCU" SG_ 2364540032 ActEngPcTrq_00480 500;
BA_ "GenSigTimeoutTime_SGW" SG_ 2364540032 ActEngPcTrq_00480 500;
BA_ "GenSigTimeoutTime_PCM" SG_ 2364540032 ActEngPcTrq_00480 500;
BA_ "GenSigTimeoutTime_IC_MulticS" SG_ 2364540032 ActEngPcTrq_00480 500;
BA_ "GenSigTimeoutTime_IC_MulticII" SG_ 2364540032 ActEngPcTrq_00480 500;
BA_ "GenSigTimeoutTime_BSM_EBS" SG_ 2364540032 ActEngPcTrq_00480 500;
BA_ "GenSigTimeoutTime_ADCU" SG_ 2364540032 ActEngPcTrq_00480 500;
BA_ "GenSigStartValue" SG_ 2364540032 ActEngPcTrq_00480 125;
BA_ "CI_SigName" SG_ 2364540032 ActEngPcTrq_00480 "Actual Engine - Percent Torque";
BA_ "CI_SigId" SG_ 2364540032 ActEngPcTrq_00480 858;
BA_ "CI_ParId" SG_ 2364540032 ActEngPcTrq_00480 "513";
BA_ "SPN" SG_ 2566767127 FuelType 5837;
BA_ "GenSigTimeoutTime_SGW" SG_ 2566767127 FuelType 50000;
BA_ "GenSigTimeoutTime_PCM" SG_ 2566767127 FuelType 50000;
BA_ "GenSigTimeoutTime_MPPxPTFE2" SG_ 2566767127 FuelType 50000;
BA_ "GenSigTimeoutTime_FMS_FMS5" SG_ 2566767127 FuelType 50000;
BA_ "GenSigTimeoutTime_FMS_FMS4" SG_ 2566767127 FuelType 50000;
BA_ "CI_SigName" SG_ 2566767127 FuelType "Fuel Type";
BA_ "CI_SigId" SG_ 2566767127 FuelType 960;
BA_ "CI_ParId" SG_ 2566767127 FuelType "5837";
BA_ "SigType" SG_ 2364539648 EngPcLoadAtCurSpeed 1;
BA_ "SPN" SG_ 2364539648 EngPcLoadAtCurSpeed 92;
BA_ "GenSigTimeoutTime_VCM" SG_ 2364539648 EngPcLoadAtCurSpeed 500;
BA_ "GenSigTimeoutTime_SGW" SG_ 2364539648 EngPcLoadAtCurSpeed 500;
BA_ "GenSigTimeoutTime_PCM" SG_ 2364539648 EngPcLoadAtCurSpeed 500;
BA_ "GenSigTimeoutTime_ETC_Ecolife2" SG_ 2364539648 EngPcLoadAtCurSpeed 500;
BA_ "GenSigTimeoutTime_DMS" SG_ 2364539648 EngPcLoadAtCurSpeed 500;
BA_ "GenSigTimeoutTime_BSM_EBS" SG_ 2364539648 EngPcLoadAtCurSpeed 500;
BA_ "GenSigTimeoutTime_ADCU" SG_ 2364539648 EngPcLoadAtCurSpeed 500;
BA_ "CI_SigName" SG_ 2364539648 EngPcLoadAtCurSpeed "Engine Percent Load At Current Speed";
BA_ "CI_SigId" SG_ 2364539648 EngPcLoadAtCurSpeed 869;
BA_ "CI_ParId" SG_ 2364539648 EngPcLoadAtCurSpeed "92";
BA_ "SigType" SG_ 2364539648 AccPedPos1 1;
BA_ "SPN" SG_ 2364539648 AccPedPos1 91;
BA_ "GenSigTimeoutTime_SGW" SG_ 2364539648 AccPedPos1 500;
BA_ "GenSigTimeoutTime_RM_IRCS" SG_ 2364539648 AccPedPos1 500;
BA_ "GenSigTimeoutTime_PCM" SG_ 2364539648 AccPedPos1 500;
BA_ "GenSigTimeoutTime_FMS_FMS5" SG_ 2364539648 AccPedPos1 500;
BA_ "GenSigTimeoutTime_FMS_FMS4" SG_ 2364539648 AccPedPos1 500;
BA_ "GenSigTimeoutTime_ETC_Ecolife2" SG_ 2364539648 AccPedPos1 500;
BA_ "GenSigTimeoutTime_BSM_EBS" SG_ 2364539648 AccPedPos1 500;
BA_ "GenSigTimeoutTime_BCM_NBM" SG_ 2364539648 AccPedPos1 500;
BA_ "GenSigTimeoutTime_Av2HP" SG_ 2364539648 AccPedPos1 500;
BA_ "GenSigTimeoutTime_ADCU" SG_ 2364539648 AccPedPos1 500;
BA_ "CI_SigName" SG_ 2364539648 AccPedPos1 "Accelerator Pedal Position 1";
BA_ "CI_SigId" SG_ 2364539648 AccPedPos1 868;
BA_ "CI_ParId" SG_ 2364539648 AccPedPos1 "91";
BA_ "SigType" SG_ 2364539648 AccPedKdSw 4;
BA_ "SPN" SG_ 2364539648 AccPedKdSw 559;
BA_ "GenSigTimeoutTime_SGW" SG_ 2364539648 AccPedKdSw 500;
BA_ "GenSigTimeoutTime_PCM" SG_ 2364539648 AccPedKdSw 500;
BA_ "GenSigTimeoutTime_ETC_Ecolife2" SG_ 2364539648 AccPedKdSw 500;
BA_ "GenSigTimeoutTime_ADCU" SG_ 2364539648 AccPedKdSw 500;
BA_ "CI_SigName" SG_ 2364539648 AccPedKdSw "Accelerator Pedal Kickdown Switch";
BA_ "CI_SigId" SG_ 2364539648 AccPedKdSw 865;
BA_ "CI_ParId" SG_ 2364539648 AccPedKdSw "559";
BA_ "SigType" SG_ 2364539648 AccPed1LowIdleSw 4;
BA_ "SPN" SG_ 2364539648 AccPed1LowIdleSw 558;
BA_ "GenSigTimeoutTime_SGW" SG_ 2364539648 AccPed1LowIdleSw 500;
BA_ "GenSigTimeoutTime_PCM" SG_ 2364539648 AccPed1LowIdleSw 500;
BA_ "GenSigTimeoutTime_BSM_EBS" SG_ 2364539648 AccPed1LowIdleSw 500;
BA_ "GenSigTimeoutTime_BCM_NBM" SG_ 2364539648 AccPed1LowIdleSw 500;
BA_ "CI_SigName" SG_ 2364539648 AccPed1LowIdleSw "Accelerator Pedal 1 Low Idle Switch";
BA_ "CI_SigId" SG_ 2364539648 AccPed1LowIdleSw 864;
BA_ "CI_ParId" SG_ 2364539648 AccPed1LowIdleSw "558";
BA_ "SigType" SG_ 2364539776 ActMaxAvEngPcTrq 1;
BA_ "SPN" SG_ 2364539776 ActMaxAvEngPcTrq 3357;
BA_ "GenSigTimeoutTime_VMU" SG_ 2364539776 ActMaxAvEngPcTrq 500;
BA_ "GenSigTimeoutTime_VCU" SG_ 2364539776 ActMaxAvEngPcTrq 500;
BA_ "GenSigTimeoutTime_SGW" SG_ 2364539776 ActMaxAvEngPcTrq 500;
BA_ "GenSigTimeoutTime_PCM" SG_ 2364539776 ActMaxAvEngPcTrq 500;
BA_ "CI_SigName" SG_ 2364539776 ActMaxAvEngPcTrq "Actual Maximum Available Engine - Percent Torque";
BA_ "CI_SigId" SG_ 2364539776 ActMaxAvEngPcTrq 889;
BA_ "CI_ParId" SG_ 2364539776 ActMaxAvEngPcTrq "3357";
BA_ "SigType" SG_ 2364539776 EngPcLoadAtCurSpeed_00380 1;
BA_ "SPN" SG_ 2364539776 EngPcLoadAtCurSpeed_00380 92;
BA_ "GenSigTimeoutTime_SGW" SG_ 2364539776 EngPcLoadAtCurSpeed_00380 500;
BA_ "GenSigTimeoutTime_PCM" SG_ 2364539776 EngPcLoadAtCurSpeed_00380 500;
BA_ "GenSigTimeoutTime_MPPxPTFE2" SG_ 2364539776 EngPcLoadAtCurSpeed_00380 500;
BA_ "GenSigTimeoutTime_FMS_FMS5" SG_ 2364539776 EngPcLoadAtCurSpeed_00380 500;
BA_ "GenSigTimeoutTime_FMS_FMS4" SG_ 2364539776 EngPcLoadAtCurSpeed_00380 500;
BA_ "GenSigTimeoutTime_BSM_EBS" SG_ 2364539776 EngPcLoadAtCurSpeed_00380 500;
BA_ "GenSigTimeoutTime_ADCU" SG_ 2364539776 EngPcLoadAtCurSpeed_00380 500;
BA_ "CI_SigName" SG_ 2364539776 EngPcLoadAtCurSpeed_00380 "Engine Percent Load At Current Speed";
BA_ "CI_SigId" SG_ 2364539776 EngPcLoadAtCurSpeed_00380 884;
BA_ "CI_ParId" SG_ 2364539776 EngPcLoadAtCurSpeed_00380 "92";
BA_ "SigType" SG_ 2364539776 AccPedPos1_00380 1;
BA_ "SPN" SG_ 2364539776 AccPedPos1_00380 91;
BA_ "GenSigTimeoutTime_SGW" SG_ 2364539776 AccPedPos1_00380 500;
BA_ "GenSigTimeoutTime_PCM" SG_ 2364539776 AccPedPos1_00380 500;
BA_ "GenSigTimeoutTime_MPPxPTFE2" SG_ 2364539776 AccPedPos1_00380 500;
BA_ "GenSigTimeoutTime_FMS_FMS5" SG_ 2364539776 AccPedPos1_00380 500;
BA_ "GenSigTimeoutTime_FMS_FMS4" SG_ 2364539776 AccPedPos1_00380 500;
BA_ "GenSigTimeoutTime_BSM_EBS" SG_ 2364539776 AccPedPos1_00380 500;
BA_ "GenSigTimeoutTime_BCM_NBM" SG_ 2364539776 AccPedPos1_00380 500;
BA_ "GenSigTimeoutTime_ADCU" SG_ 2364539776 AccPedPos1_00380 500;
BA_ "CI_SigName" SG_ 2364539776 AccPedPos1_00380 "Accelerator Pedal Position 1";
BA_ "CI_SigId" SG_ 2364539776 AccPedPos1_00380 883;
BA_ "CI_ParId" SG_ 2364539776 AccPedPos1_00380 "91";
BA_ "SigType" SG_ 2566840064 NomFrictPcTrq 1;
BA_ "SPN" SG_ 2566840064 NomFrictPcTrq 514;
BA_ "GenSigTimeoutTime_VCM" SG_ 2566840064 NomFrictPcTrq 1250;
BA_ "GenSigTimeoutTime_SGW" SG_ 2566840064 NomFrictPcTrq 1250;
BA_ "GenSigTimeoutTime_PCM" SG_ 2566840064 NomFrictPcTrq 1250;
BA_ "GenSigTimeoutTime_ETC_Ecolife2" SG_ 2566840064 NomFrictPcTrq 1250;
BA_ "GenSigTimeoutTime_BSM_EBS" SG_ 2566840064 NomFrictPcTrq 1250;
BA_ "GenSigTimeoutTime_ADCU" SG_ 2566840064 NomFrictPcTrq 1250;
BA_ "GenSigStartValue" SG_ 2566840064 NomFrictPcTrq 125;
BA_ "CI_SigName" SG_ 2566840064 NomFrictPcTrq "Nominal Friction - Percent Torque";
BA_ "CI_SigId" SG_ 2566840064 NomFrictPcTrq 932;
BA_ "CI_ParId" SG_ 2566840064 NomFrictPcTrq "514";
BA_ "SigType" SG_ 2566840192 NomFrictPcTrq_FEDF80 1;
BA_ "SPN" SG_ 2566840192 NomFrictPcTrq_FEDF80 514;
BA_ "GenSigTimeoutTime_VMU" SG_ 2566840192 NomFrictPcTrq_FEDF80 1000;
BA_ "GenSigTimeoutTime_VCU" SG_ 2566840192 NomFrictPcTrq_FEDF80 1000;
BA_ "GenSigTimeoutTime_SGW" SG_ 2566840192 NomFrictPcTrq_FEDF80 1000;
BA_ "GenSigTimeoutTime_PCM" SG_ 2566840192 NomFrictPcTrq_FEDF80 1000;
BA_ "GenSigTimeoutTime_IC_MulticII" SG_ 2566840192 NomFrictPcTrq_FEDF80 1000;
BA_ "GenSigTimeoutTime_BSM_EBS" SG_ 2566840192 NomFrictPcTrq_FEDF80 1000;
BA_ "GenSigTimeoutTime_ADCU" SG_ 2566840192 NomFrictPcTrq_FEDF80 1000;
BA_ "GenSigStartValue" SG_ 2566840192 NomFrictPcTrq_FEDF80 125;
BA_ "CI_SigName" SG_ 2566840192 NomFrictPcTrq_FEDF80 "Nominal Friction - Percent Torque";
BA_ "CI_SigId" SG_ 2566840192 NomFrictPcTrq_FEDF80 943;
BA_ "CI_ParId" SG_ 2566840192 NomFrictPcTrq_FEDF80 "514";
BA_ "SigType" SG_ 2566844160 EngOilPrs1 1;
BA_ "SPN" SG_ 2566844160 EngOilPrs1 100;
BA_ "GenSigTimeoutTime_VCM" SG_ 2566844160 EngOilPrs1 2500;
BA_ "GenSigTimeoutTime_SGW" SG_ 2566844160 EngOilPrs1 2500;
BA_ "GenSigTimeoutTime_PCM" SG_ 2566844160 EngOilPrs1 2500;
BA_ "GenSigTimeoutTime_IC_MulticS" SG_ 2566844160 EngOilPrs1 2500;
BA_ "GenSigTimeoutTime_FMS_FMS5" SG_ 2566844160 EngOilPrs1 2500;
BA_ "GenSigTimeoutTime_FMS_FMS4" SG_ 2566844160 EngOilPrs1 2500;
BA_ "GenSigTimeoutTime_BCM_NBM" SG_ 2566844160 EngOilPrs1 2500;
BA_ "CI_SigName" SG_ 2566844160 EngOilPrs1 "Engine Oil Pressure 1";
BA_ "CI_SigId" SG_ 2566844160 EngOilPrs1 1081;
BA_ "CI_ParId" SG_ 2566844160 EngOilPrs1 "100";
BA_ "SigType" SG_ 2566844160 EngFuelDelPrs 1;
BA_ "SPN" SG_ 2566844160 EngFuelDelPrs 94;
BA_ "GenSigTimeoutTime_VCM" SG_ 2566844160 EngFuelDelPrs 2500;
BA_ "GenSigTimeoutTime_SGW" SG_ 2566844160 EngFuelDelPrs 2500;
BA_ "GenSigTimeoutTime_PCM" SG_ 2566844160 EngFuelDelPrs 2500;
BA_ "GenSigTimeoutTime_IC_MulticS" SG_ 2566844160 EngFuelDelPrs 2500;
BA_ "GenSigTimeoutTime_FMS_FMS5" SG_ 2566844160 EngFuelDelPrs 2500;
BA_ "GenSigTimeoutTime_FMS_FMS4" SG_ 2566844160 EngFuelDelPrs 2500;
BA_ "GenSigTimeoutTime_BCM_NBM" SG_ 2566844160 EngFuelDelPrs 2500;
BA_ "CI_SigName" SG_ 2566844160 EngFuelDelPrs "Engine Fuel Delivery Pressure";
BA_ "CI_SigId" SG_ 2566844160 EngFuelDelPrs 1077;
BA_ "CI_ParId" SG_ 2566844160 EngFuelDelPrs "94";
BA_ "SigType" SG_ 2566844193 EngCoolLev1 1;
BA_ "SPN" SG_ 2566844193 EngCoolLev1 111;
BA_ "GenSigTimeoutTime_SGW" SG_ 2566844193 EngCoolLev1 2500;
BA_ "CI_SigName" SG_ 2566844193 EngCoolLev1 "Engine Coolant Level 1";
BA_ "CI_SigId" SG_ 2566844193 EngCoolLev1 1092;
BA_ "CI_ParId" SG_ 2566844193 EngCoolLev1 "111";
BA_ "SigType" SG_ 2566844193 EngCoolPrs1 1;
BA_ "SPN" SG_ 2566844193 EngCoolPrs1 109;
BA_ "GenSigTimeoutTime_SGW" SG_ 2566844193 EngCoolPrs1 2500;
BA_ "CI_SigName" SG_ 2566844193 EngCoolPrs1 "Engine Coolant Pressure 1";
BA_ "CI_SigId" SG_ 2566844193 EngCoolPrs1 1091;
BA_ "CI_ParId" SG_ 2566844193 EngCoolPrs1 "109";
BA_ "SigType" SG_ 2566844193 EngCrkcPrs1 1;
BA_ "SPN" SG_ 2566844193 EngCrkcPrs1 101;
BA_ "GenSigTimeoutTime_SGW" SG_ 2566844193 EngCrkcPrs1 2500;
BA_ "GenSigStartValue" SG_ 2566844193 EngCrkcPrs1 32000;
BA_ "CI_SigName" SG_ 2566844193 EngCrkcPrs1 "Engine Crankcase Pressure 1";
BA_ "CI_SigId" SG_ 2566844193 EngCrkcPrs1 1090;
BA_ "CI_ParId" SG_ 2566844193 EngCrkcPrs1 "101";
BA_ "SigType" SG_ 2566844193 EngOilPrs1_FEEF21 1;
BA_ "SPN" SG_ 2566844193 EngOilPrs1_FEEF21 100;
BA_ "GenSigTimeoutTime_SGW" SG_ 2566844193 EngOilPrs1_FEEF21 2500;
BA_ "CI_SigName" SG_ 2566844193 EngOilPrs1_FEEF21 "Engine Oil Pressure 1";
BA_ "CI_SigId" SG_ 2566844193 EngOilPrs1_FEEF21 1089;
BA_ "CI_ParId" SG_ 2566844193 EngOilPrs1_FEEF21 "100";
BA_ "SigType" SG_ 2566844193 EngOilLev 1;
BA_ "SPN" SG_ 2566844193 EngOilLev 98;
BA_ "GenSigTimeoutTime_SGW" SG_ 2566844193 EngOilLev 2500;
BA_ "GenSigTimeoutTime_IC_MulticS" SG_ 2566844193 EngOilLev 2500;
BA_ "GenSigTimeoutTime_FMS_FMS5" SG_ 2566844193 EngOilLev 2500;
BA_ "GenSigTimeoutTime_FMS_FMS4" SG_ 2566844193 EngOilLev 2500;
BA_ "CI_SigName" SG_ 2566844193 EngOilLev "Engine Oil Level";
BA_ "CI_SigId" SG_ 2566844193 EngOilLev 1088;
BA_ "CI_ParId" SG_ 2566844193 EngOilLev "98";
BA_ "SigType" SG_ 2566844193 EngExCrkcBlowByPrs 1;
BA_ "SPN" SG_ 2566844193 EngExCrkcBlowByPrs 22;
BA_ "GenSigTimeoutTime_SGW" SG_ 2566844193 EngExCrkcBlowByPrs 2500;
BA_ "CI_SigName" SG_ 2566844193 EngExCrkcBlowByPrs "Engine Extended Crankcase Blow-by Pressure";
BA_ "CI_SigId" SG_ 2566844193 EngExCrkcBlowByPrs 1087;
BA_ "CI_ParId" SG_ 2566844193 EngExCrkcBlowByPrs "22";
BA_ "SigType" SG_ 2566844193 EngFuelDelPrs_FEEF21 1;
BA_ "SPN" SG_ 2566844193 EngFuelDelPrs_FEEF21 94;
BA_ "GenSigTimeoutTime_SGW" SG_ 2566844193 EngFuelDelPrs_FEEF21 2500;
BA_ "GenSigTimeoutTime_FMS_FMS5" SG_ 2566844193 EngFuelDelPrs_FEEF21 2500;
BA_ "GenSigTimeoutTime_FMS_FMS4" SG_ 2566844193 EngFuelDelPrs_FEEF21 2500;
BA_ "CI_SigName" SG_ 2566844193 EngFuelDelPrs_FEEF21 "Engine Fuel Delivery Pressure";
BA_ "CI_SigId" SG_ 2566844193 EngFuelDelPrs_FEEF21 1086;
BA_ "CI_ParId" SG_ 2566844193 EngFuelDelPrs_FEEF21 "94";
BA_ "GenSigTimeoutTime_VCU" SG_ 2566885210 Modefb 500;
BA_ "GenSigTimeoutTime_SGW" SG_ 2566885210 Modefb 500;
BA_ "GenSigTimeoutTime_PCM" SG_ 2566885210 Modefb 500;
BA_ "CI_SigName" SG_ 2566885210 Modefb "ModeFB";
BA_ "CI_SigId" SG_ 2566885210 Modefb 1366;
BA_ "CI_ParId" SG_ 2566885210 Modefb "IB105";
BA_ "SigType" SG_ 2566898290 EngStopSw 4;
BA_ "GenSigTimeoutTime_SGW" SG_ 2566898290 EngStopSw 500;
BA_ "GenSigTimeoutTime_PCM" SG_ 2566898290 EngStopSw 500;
BA_ "GenSigTimeoutTime_ETC_DiwaNXT_MH" SG_ 2566898290 EngStopSw 500;
BA_ "GenSigTimeoutTime_ETC_DiwaNXT" SG_ 2566898290 EngStopSw 500;
BA_ "CI_SigName" SG_ 2566898290 EngStopSw "Engine Stop Switch";
BA_ "CI_SigId" SG_ 2566898290 EngStopSw 3937;
BA_ "CI_ParId" SG_ 2566898290 EngStopSw "IS003";
BA_ "SigType" SG_ 2565865488 RetSelNonEng 1;
BA_ "SPN" SG_ 2565865488 RetSelNonEng 1716;
BA_ "GenSigTimeoutTime_VCM" SG_ 2565865488 RetSelNonEng 500;
BA_ "GenSigTimeoutTime_SGW" SG_ 2565865488 RetSelNonEng 500;
BA_ "GenSigTimeoutTime_PCM" SG_ 2565865488 RetSelNonEng 500;
BA_ "CI_SigName" SG_ 2565865488 RetSelNonEng "Retarder Selection, non-engine";
BA_ "CI_SigId" SG_ 2565865488 RetSelNonEng 419;
BA_ "CI_ParId" SG_ 2565865488 RetSelNonEng "1716";
BA_ "SigType" SG_ 2565865488 ActRetPcTrq 1;
BA_ "SPN" SG_ 2565865488 ActRetPcTrq 520;
BA_ "GenSigTimeoutTime_VMU" SG_ 2565865488 ActRetPcTrq 500;
BA_ "GenSigTimeoutTime_VCU" SG_ 2565865488 ActRetPcTrq 500;
BA_ "GenSigTimeoutTime_VCM" SG_ 2565865488 ActRetPcTrq 500;
BA_ "GenSigTimeoutTime_SGW" SG_ 2565865488 ActRetPcTrq 500;
BA_ "GenSigTimeoutTime_PCM" SG_ 2565865488 ActRetPcTrq 500;
BA_ "GenSigTimeoutTime_MPPxPTFE2" SG_ 2565865488 ActRetPcTrq 500;
BA_ "GenSigTimeoutTime_IC_MulticS" SG_ 2565865488 ActRetPcTrq 500;
BA_ "GenSigTimeoutTime_FMS_FMS5" SG_ 2565865488 ActRetPcTrq 500;
BA_ "GenSigTimeoutTime_FMS_FMS4" SG_ 2565865488 ActRetPcTrq 500;
BA_ "GenSigTimeoutTime_BSM_EBS" SG_ 2565865488 ActRetPcTrq 500;
BA_ "GenSigTimeoutTime_BCM_NBM" SG_ 2565865488 ActRetPcTrq 500;
BA_ "GenSigTimeoutTime_ADCU" SG_ 2565865488 ActRetPcTrq 500;
BA_ "GenSigStartValue" SG_ 2565865488 ActRetPcTrq 125;
BA_ "CI_SigName" SG_ 2565865488 ActRetPcTrq "Actual Retarder - Percent Torque";
BA_ "CI_SigId" SG_ 2565865488 ActRetPcTrq 411;
BA_ "CI_ParId" SG_ 2565865488 ActRetPcTrq "520";
BA_ "SPN" SG_ 2565865488 RetTrqMode 900;
BA_ "GenSigTimeoutTime_VMU" SG_ 2565865488 RetTrqMode 500;
BA_ "GenSigTimeoutTime_VCU" SG_ 2565865488 RetTrqMode 500;
BA_ "GenSigTimeoutTime_VCM" SG_ 2565865488 RetTrqMode 500;
BA_ "GenSigTimeoutTime_SGW" SG_ 2565865488 RetTrqMode 500;
BA_ "GenSigTimeoutTime_PCM" SG_ 2565865488 RetTrqMode 500;
BA_ "GenSigTimeoutTime_MPPxPTFE2" SG_ 2565865488 RetTrqMode 500;
BA_ "GenSigTimeoutTime_IC_MulticS" SG_ 2565865488 RetTrqMode 500;
BA_ "GenSigTimeoutTime_FMS_FMS5" SG_ 2565865488 RetTrqMode 500;
BA_ "GenSigTimeoutTime_FMS_FMS4" SG_ 2565865488 RetTrqMode 500;
BA_ "GenSigTimeoutTime_BSM_EBS" SG_ 2565865488 RetTrqMode 500;
BA_ "GenSigTimeoutTime_ADCU" SG_ 2565865488 RetTrqMode 500;
BA_ "CI_SigName" SG_ 2565865488 RetTrqMode "Retarder Torque Mode";
BA_ "CI_SigId" SG_ 2565865488 RetTrqMode 408;
BA_ "CI_ParId" SG_ 2565865488 RetTrqMode "900";
BA_ "SigType" SG_ 2565865487 ActRetPcTrq_F0000F 1;
BA_ "SPN" SG_ 2565865487 ActRetPcTrq_F0000F 520;
BA_ "GenSigTimeoutTime_VCM" SG_ 2565865487 ActRetPcTrq_F0000F 500;
BA_ "GenSigTimeoutTime_SGW" SG_ 2565865487 ActRetPcTrq_F0000F 500;
BA_ "GenSigTimeoutTime_PCM" SG_ 2565865487 ActRetPcTrq_F0000F 500;
BA_ "GenSigTimeoutTime_IC_MulticS" SG_ 2565865487 ActRetPcTrq_F0000F 500;
BA_ "GenSigTimeoutTime_ETC_Ecolife2" SG_ 2565865487 ActRetPcTrq_F0000F 500;
BA_ "GenSigTimeoutTime_BSM_EBS" SG_ 2565865487 ActRetPcTrq_F0000F 500;
BA_ "GenSigTimeoutTime_BCM_NBM" SG_ 2565865487 ActRetPcTrq_F0000F 500;
BA_ "GenSigTimeoutTime_ADCU" SG_ 2565865487 ActRetPcTrq_F0000F 500;
BA_ "GenSigStartValue" SG_ 2565865487 ActRetPcTrq_F0000F 125;
BA_ "CI_SigName" SG_ 2565865487 ActRetPcTrq_F0000F "Actual Retarder - Percent Torque";
BA_ "CI_SigId" SG_ 2565865487 ActRetPcTrq_F0000F 396;
BA_ "CI_ParId" SG_ 2565865487 ActRetPcTrq_F0000F "520";
BA_ "SigType" SG_ 2566843904 EngOilTemp1 1;
BA_ "SPN" SG_ 2566843904 EngOilTemp1 175;
BA_ "GenSigTimeoutTime_VCM" SG_ 2566843904 EngOilTemp1 5000;
BA_ "GenSigTimeoutTime_SGW" SG_ 2566843904 EngOilTemp1 5000;
BA_ "GenSigTimeoutTime_PCM" SG_ 2566843904 EngOilTemp1 5000;
BA_ "GenSigTimeoutTime_BCM_NBM" SG_ 2566843904 EngOilTemp1 5000;
BA_ "GenSigTimeoutTime_Av2HP" SG_ 2566843904 EngOilTemp1 5000;
BA_ "GenSigStartValue" SG_ 2566843904 EngOilTemp1 8736;
BA_ "CI_SigName" SG_ 2566843904 EngOilTemp1 "Engine Oil Temperature 1";
BA_ "CI_SigId" SG_ 2566843904 EngOilTemp1 1072;
BA_ "CI_ParId" SG_ 2566843904 EngOilTemp1 "175";
BA_ "SigType" SG_ 2566843904 EngFuel1Temp1 1;
BA_ "SPN" SG_ 2566843904 EngFuel1Temp1 174;
BA_ "GenSigTimeoutTime_VCM" SG_ 2566843904 EngFuel1Temp1 5000;
BA_ "GenSigTimeoutTime_SGW" SG_ 2566843904 EngFuel1Temp1 5000;
BA_ "GenSigTimeoutTime_PCM" SG_ 2566843904 EngFuel1Temp1 5000;
BA_ "GenSigTimeoutTime_BCM_NBM" SG_ 2566843904 EngFuel1Temp1 5000;
BA_ "GenSigStartValue" SG_ 2566843904 EngFuel1Temp1 40;
BA_ "CI_SigName" SG_ 2566843904 EngFuel1Temp1 "Engine Fuel 1 Temperature 1";
BA_ "CI_SigId" SG_ 2566843904 EngFuel1Temp1 1071;
BA_ "CI_ParId" SG_ 2566843904 EngFuel1Temp1 "174";
BA_ "SigType" SG_ 2566843904 EngCoolTemp 1;
BA_ "SPN" SG_ 2566843904 EngCoolTemp 110;
BA_ "GenSigTimeoutTime_VCM" SG_ 2566843904 EngCoolTemp 5000;
BA_ "GenSigTimeoutTime_SGW" SG_ 2566843904 EngCoolTemp 5000;
BA_ "GenSigTimeoutTime_PCM" SG_ 2566843904 EngCoolTemp 5000;
BA_ "GenSigTimeoutTime_IC_MulticS" SG_ 2566843904 EngCoolTemp 5000;
BA_ "GenSigTimeoutTime_FMS_FMS5" SG_ 2566843904 EngCoolTemp 5000;
BA_ "GenSigTimeoutTime_FMS_FMS4" SG_ 2566843904 EngCoolTemp 5000;
BA_ "GenSigTimeoutTime_FCCU" SG_ 2566843904 EngCoolTemp 5000;
BA_ "GenSigTimeoutTime_EBS_EBR" SG_ 2566843904 EngCoolTemp 5000;
BA_ "GenSigTimeoutTime_DMS" SG_ 2566843904 EngCoolTemp 5000;
BA_ "GenSigTimeoutTime_BSM_EBS" SG_ 2566843904 EngCoolTemp 5000;
BA_ "GenSigTimeoutTime_BCM_NBM" SG_ 2566843904 EngCoolTemp 5000;
BA_ "GenSigTimeoutTime_Av2HP" SG_ 2566843904 EngCoolTemp 5000;
BA_ "GenSigTimeoutTime_ADCU" SG_ 2566843904 EngCoolTemp 5000;
BA_ "GenSigStartValue" SG_ 2566843904 EngCoolTemp 40;
BA_ "CI_SigName" SG_ 2566843904 EngCoolTemp "Engine Coolant Temperature";
BA_ "CI_SigId" SG_ 2566843904 EngCoolTemp 1070;
BA_ "CI_ParId" SG_ 2566843904 EngCoolTemp "110";
VAL_ 2561142090 BenefitLateral 0 "False" 1 "True" 2 "Reserved" 3 "Not available" ;
VAL_ 2561142090 ValidLateral 0 "False" 1 "True" 2 "Reserved" 3 "Not available" ;
VAL_ 2561134666 BenefitLaneDpt 0 "False" 1 "True" 2 "Reserved" 3 "Not available" ;
VAL_ 2561134666 ValidLaneDpt 0 "False" 1 "True" 2 "Reserved" 3 "Not available" ;
VAL_ 2561134922 EventLaneDpt 0 "NoEvent" 1 "LaneDepartEnabled" 2 "LaneDepartDisabled" 3 "LaneDepartTriggered" ;
VAL_ 2561142346 BenefitLongitudinal 0 "False" 1 "True" 2 "Reserved" 3 "Not available" ;
VAL_ 2561142346 ValidLongitudinal 0 "False" 1 "True" 2 "Reserved" 3 "Not available" ;
VAL_ 2561146186 BenefitMois 0 "False" 1 "True" 2 "Reserved" 3 "Not available" ;
VAL_ 2561146186 ValidMois 0 "False" 1 "True" 2 "Reserved" 3 "Not available" ;
VAL_ 2561135178 NotificationTextId 0 "NoText" 1 "AccelerationGood" 2 "AccelerationBad" 3 "INERTIA_GOODGASBRAKE" 4 "INERTIA_BADGASBRAKE" 5 "INERTIA_GOODGASGAS" 6 "PECC_ENABLED" 7 "PECC_DISABLED" 8 "STOP_GOOD" 9 "STOP_BAD" 10 "STOP_PANIC" 11 "RPM_GOOD" 12 "RPM_BADHIGH" 13 "RPM_BADLOW" 14 "RPM_GSIFAULT" 15 "AUXILIARYBRAKE_GOOD" 16 "AUXILIARYBRAKE_BAD" 17 "AUXILIARYBRAKE_DISABLEDTEMP" 18 "AUXILIARYBRAKE_DISABLEDMASS" 19 "TIRESAVING_BAG" 20 "ECOSWITCH_ENABLED" 21 "ECOSWITCH_DISABLED" 22 "LANEDEPARTURE_ENABLED" 23 "LANEDEPARTURE_DISABLED" 24 "LANEDEPARTURE_TRIGGERED" 25 "AEBS_ENABLED" 26 "AEBS_DISABLED" 27 "AEBS_TRIGGERED" 28 "ADAPTIVECRUISE_ENABLED" 29 "ADAPTIVECRUISE_DISABLED" 30 "HANDBRAKE_BAD" 31 "HARSHBRAKING_BAD" 32 "HARSHSTEERING_BAD" 33 "SAFEDISTANCE_BAD" 34 "STABILITY_BAD" 35 "TIRESAFETY_BAD" 36 "DAS_WARNING" 37 "AS_STOP" 38 "Reserved1" 39 "Reserved2" 40 "TRIP_INFO" 41 "TRIP_START" 42 "TRIP_END" ;
VAL_ 2561135434 OldDasEnabled 0 "False" 1 "True" 2 "Reserved" 3 "Not available" ;
VAL_ 2561135434 OldDasWarning 0 "False" 1 "True" 2 "Reserved" 3 "Not available" ;
VAL_ 2561135434 OldDasStop 0 "False" 1 "True" 2 "Reserved" 3 "Not available" ;
VAL_ 2561135690 BenefitPecc 0 "False" 1 "True" 2 "Reserved" 3 "Not available" ;
VAL_ 2561135690 ValidPecc 0 "False" 1 "True" 2 "Reserved" 3 "Not available" ;
VAL_ 2561135946 EventPecc 0 "NoEvent" 1 "PeccEnabled" 2 "PeccDisabled" ;
VAL_ 2561136202 BenefitRadar 0 "False" 1 "True" 2 "Reserved" 3 "Not available" ;
VAL_ 2561136202 ValidRadar 0 "False" 1 "True" 2 "Reserved" 3 "Not available" ;
VAL_ 2561136458 EventRadar 0 "NoEvent" 1 "UnsafeDistanceDetected" ;
VAL_ 2561136714 BenefitRpm 0 "False" 1 "True" 2 "Reserved" 3 "Not available" ;
VAL_ 2561136714 ValidRpm 0 "False" 1 "True" 2 "Reserved" 3 "Not available" ;
VAL_ 2561136970 TorqueLevel 0 "Low" 1 "High" ;
VAL_ 2561136970 RPMZone 0 "Low" 1 "Middle" 2 "High" ;
VAL_ 2561136970 RPMLevel 0 "Low" 1 "Middle" 2 "High" ;
VAL_ 2561136970 EventRPM 0 "NoEvent" 1 "GoodRPM_Style" 2 "BadRPM_StyleHigh" 3 "BadRPM_StyleLow" 4 "BadRPM_GsiFault" ;
VAL_ 2561145162 BenefitSafeDistance 0 "False" 1 "True" 2 "Reserved" 3 "Not available" ;
VAL_ 2561145162 ValidSafeDistance 0 "False" 1 "True" 2 "Reserved" 3 "Not available" ;
VAL_ 2561145418 BenefitSafePosition 0 "False" 1 "True" 2 "Reserved" 3 "Not available" ;
VAL_ 2561145418 ValidSafePosition 0 "False" 1 "True" 2 "Reserved" 3 "Not available" ;
VAL_ 2561137226 BenefitSafety 0 "False" 1 "True" 2 "Reserved" 3 "Not available" ;
VAL_ 2561137226 ValidSafety 0 "False" 1 "True" 2 "Reserved" 3 "Not available" ;
VAL_ 2561137482 BenefitTireSafety 0 "False" 1 "True" 2 "Reserved" 3 "Not available" ;
VAL_ 2561137482 ValidTireSafety 0 "False" 1 "True" 2 "Reserved" 3 "Not available" ;
VAL_ 2561137738 EventTireSafety 0 "NoEvent" 1 "UnsafeTirePressure" ;
VAL_ 2561144650 BenefitSlowManeuver 0 "False" 1 "True" 2 "Reserved" 3 "Not available" ;
VAL_ 2561144650 ValidSlowManeuver 0 "False" 1 "True" 2 "Reserved" 3 "Not available" ;
VAL_ 2561144394 BenefitSpeed 0 "False" 1 "True" 2 "Reserved" 3 "Not available" ;
VAL_ 2561144394 ValidSpeed 0 "False" 1 "True" 2 "Reserved" 3 "Not available" ;
VAL_ 2566875466 AccPedPrsTooLong 0 "Inactive" 1 "Active" 2 "Error" 3 "NA" ;
VAL_ 2566875466 MaxSpeedExc 0 "Inactive" 1 "Active" 2 "Error" 3 "NA" ;
VAL_ 2566875466 HarshVertAccel_Down 0 "Inactive" 1 "Active" 2 "Error" 3 "NA" ;
VAL_ 2566875466 HarshVertAccel_UP 0 "Inactive" 1 "Active" 2 "Error" 3 "NA" ;
VAL_ 2566875466 HarshAccel 0 "Inactive" 1 "Active" 2 "Error" 3 "NA" ;
VAL_ 2566875466 HarshBrk 0 "Inactive" 1 "Active" 2 "Error" 3 "NA" ;
VAL_ 2566875466 HarshLeftTurn 0 "Inactive" 1 "Active" 2 "Error" 3 "NA" ;
VAL_ 2566875466 HarshRightTurn 0 "Inactive" 1 "Active" 2 "Error" 3 "NA" ;
VAL_ 2561138250 TripEndReason 0 "NotEnded" 1 "KeyOff" 2 "DriverIDChanged" 3 "UserReset" 4 "TelemAppReset" ;
VAL_ 2561138250 TripActive 0 "False" 1 "True" 2 "Reserved" 3 "Not available" ;
VAL_ 2561138250 TripEnded 0 "False" 1 "True" 2 "Reserved" 3 "Not available" ;
VAL_ 2561138250 TripStarted 0 "False" 1 "True" 2 "Reserved" 3 "Not available" ;
VAL_ 2561138506 BenefitStabilityControl 0 "False" 1 "True" 2 "Reserved" 3 "Not available" ;
VAL_ 2561138506 ValidStabilityControl 0 "False" 1 "True" 2 "Reserved" 3 "Not available" ;
VAL_ 2561138762 EventStabilityControl 0 "NoEvent" 1 "DrivingDetected" ;
VAL_ 2561139018 BenefitStop 0 "False" 1 "True" 2 "Reserved" 3 "Not available" ;
VAL_ 2561139018 ValidStop 0 "False" 1 "True" 2 "Reserved" 3 "Not available" ;
VAL_ 2561139274 PanicBrakeState 0 "PanicBrakeAllowed" 1 "PanicBrakeNotAllowed" 2 "PanicBrakeDetected" ;
VAL_ 2561139274 EventStop 0 "NoEvent" 1 "GoodStop" 2 "BadStop" 3 "PanicStop" ;
VAL_ 2561141066 EventValid 0 "False" 1 "True" 2 "Reserved" 3 "Not available" ;
VAL_ 2561139530 BenefitTire 0 "False" 1 "True" 2 "Reserved" 3 "Not available" ;
VAL_ 2561139530 ValidTire 0 "False" 1 "True" 2 "Reserved" 3 "Not available" ;
VAL_ 2561139786 EventTireSaving 0 "NoEvent" 1 "WastefulTirePressure" ;
VAL_ 2561144906 BenefitVehicleControl 0 "False" 1 "True" 2 "Reserved" 3 "Not available" ;
VAL_ 2561144906 ValidVehicleControl 0 "False" 1 "True" 2 "Reserved" 3 "Not available" ;
VAL_ 2561142602 BenefitVertical 0 "False" 1 "True" 2 "Reserved" 3 "Not available" ;
VAL_ 2561142602 ValidVertical 0 "False" 1 "True" 2 "Reserved" 3 "Not available" ;
VAL_ 2565865739 Atc_AsrInfoSig 0 "Off" 1 "On" 2 "Reserved" 3 "Take no action" ;
VAL_ 2565865739 AbsFullyOp 0 "Not Fully Operational" 1 "Fully Operational" 2 "Reserved" 3 "Not Available" ;
VAL_ 2565865739 AbsActv 0 "ABS passive but installed" 1 "ABS active" 2 "Error" 3 "Not available" ;
VAL_ 2565865739 AsrBrkCtrlActv 0 "ASR_BrkCtrlPassiveButInstal" 1 "ASR BrkCtrlActive" 2 "Error" 3 "Not available" ;
VAL_ 2565865739 AsrEngCtrlActv 0 "Brake Switch not set" 1 "Brake Switch set" 2 "Error" 3 "Not available" ;
VAL_ 2566831883 FaSpeed 254 "Error" 255 "Not Available" ;
VAL_ 2633935883 BrkLinRemRa3R 0 "Totally worn linings" 250 "New brake linings" 254 "Error" 255 "Not Available" ;
VAL_ 2633935883 BrkLinRemRa3L 0 "Totally worn linings" 250 "New brake linings" ;
VAL_ 2633935883 BrkLinRemRa2R 0 "Totally worn linings" 250 "New brake linings" 254 "Error" 255 "Not Available" ;
VAL_ 2633935883 BrkLinRemRa2L 0 "Totally worn linings" 250 "New brake linings" 254 "Error" 255 "Not Available" ;
VAL_ 2633935883 BrkLinRemRa1R 0 "Totally worn linings" 250 "New brake linings" 254 "Error" 255 "Not Available" ;
VAL_ 2633935883 BrkLinRemRa1L 0 "Totally worn linings" 250 "New brake linings" 254 "Error" 255 "Not Available" ;
VAL_ 2633935883 BrkLinRemFaR 0 "Totally worn linings" 250 "New brake linings" 254 "Error" 255 "Not Available" ;
VAL_ 2633935883 BrkLinRemFaL 0 "Totally worn linings" 250 "New brake linings" 254 "Error" 255 "Not Available" ;
VAL_ 2566767627 HhMode 0 "Inactive" 1 "Active" 2 "Active, will change to inactive" 3 "Active, may activate park brake" 4 "Reserved" 5 "Reserved" 6 "Hill holder not functional" 7 "Not Available" ;
VAL_ 2566767627 HaltBrkMode 0 "Inactive" 1 "Active" 2 "Active, but not functioning" 3 "Not defined" 4 "Not defined" 5 "Not defined" 6 "Not functional" 7 "Not Available" ;
VAL_ 2566889801 ChgIntrp 0 "Not Interrupt" 1 "Charge Interrupt" 2 "Error" 3 "Unavailable" ;
VAL_ 2566849280 EngOilTempHigh 0 "Normal" 1 "Above operating range" 3 "Not Available" ;
VAL_ 2566849280 EconMode 0 "Off" 1 "On" ;
VAL_ 2566849280 EngOilPrsLow 0 "Normal" 1 "Below operating range" 2 "Error" 3 "Not Available" ;
VAL_ 2566849280 CabTilted 0 "Upright" 1 "Tilted" 3 "Not Available" ;
VAL_ 2566849280 EngOverTemp 0 "No warning" 1 "Prewarning" 2 "Warning" ;
VAL_ 2364539904 EngDemPcTrq 254 "Error" 255 "Not_available" ;
VAL_ 2364539904 EngSpeed 65024 "Error" 65535 "Not_Available" ;
VAL_ 2364539904 ActEngPcTrq 254 "Error" 255 "Not_available" ;
VAL_ 2364539904 EngTrqMode 0 "Low idle / No request" 1 "APP/operator selection" 2 "Cruise control" 3 "PTO governor" 4 "Road speed governor" 5 "ASR control" 6 "Transmission control" 7 "ABS control" 8 "Torque limiting" 9 "High speed governor" 10 "Braking system" 11 "Remote accelerator" 12 "Service procedure" 13 "not defined" 14 "Other" 15 "Not Available" ;
VAL_ 2364540032 EngSpeed_00480 65024 "Error" 65535 "Not_Available" ;
VAL_ 2364540032 ActEngPcTrq_00480 254 "Error" 255 "Not_available" ;
VAL_ 2566767127 FuelType 0 "Not Available, NONE" 1 "GAS" 2 "METH" 3 "ETH" 4 "DSL" 5 "LPG" 6 "CNG" 7 "PROP" 8 "ELEC" 9 "BI_GAS" 10 "BI_METH" 11 "BI_ETH" 12 "BI_LPG" 13 "BI_CNG" 14 "BI_PROP" 15 "BI_ELEC" 16 "BI_MIX" 17 "HYB_GAS" 18 "HYB_ETH" 19 "HYB_DSL" 20 "HYB_ELEC" 21 "HYB_MIX" 22 "HYB_REG" 23 "NG" 24 "BI_NG" 25 "Bi-fuel using diesel" 26 "Natural Gas (Compr. or Liquid)" 27 "Dual Fuel, Diesel and CNG" 28 "Dual Fuel, Diesel and LNG" 29 "Fuel Cell Utilizing Hydrogen" 30 "Hydrogen Internal Combustion" 31 "Kerosene" 32 "Heavy Fuel Oil" 33 "Reserved" 253 "Reserved" 254 "Error" 255 "Not Available" ;
VAL_ 2364539648 EngPcLoadAtCurSpeed 254 "Error" 255 "Not_available" ;
VAL_ 2364539648 AccPedPos1 254 "Error" 255 "Not_available" ;
VAL_ 2364539648 AccPedKdSw 0 "Kickdown passive" 1 "Kickdown active" 2 "Error" 3 "Not Available" ;
VAL_ 2364539648 AccPed1LowIdleSw 0 "Not in low idle" 1 "Low idle" 2 "Error" 3 "Not Available" ;
VAL_ 2364539776 ActMaxAvEngPcTrq 254 "Error" 255 "Not_available" ;
VAL_ 2364539776 EngPcLoadAtCurSpeed_00380 254 "Error" 255 "Not_available" ;
VAL_ 2364539776 AccPedPos1_00380 254 "Error" 255 "Not_available" ;
VAL_ 2566844193 EngOilLev 254 "Error" 255 "Not_available" ;
VAL_ 2566844193 EngExCrkcBlowByPrs 254 "Error" 255 "Not_available" ;
VAL_ 2566898290 EngStopSw 0 "Off" 1 "On" ;
VAL_ 2565865488 RetSelNonEng 254 "Error" 255 "Not_available" ;
VAL_ 2565865488 ActRetPcTrq 254 "Error" 255 "Not_available" ;
VAL_ 2565865488 RetTrqMode 0 "Low idle / No request" 1 "APP / Operator selection" 2 "Cruise control" 3 "PTO governor" 4 "Road speed governor" 5 "ASR control" 6 "Transmission control" 7 "ABS control" 8 "Torque limiting" 9 "High speed governor" 10 "Braking system" 11 "Remote accelerator" 12 "Service procedure" 13 "not defined" 14 "Other" 15 "Not Available" ;
VAL_ 2565865487 ActRetPcTrq_F0000F 254 "Error" 255 "Not_available" ;
